VERSION ""

NS_ :

BS_:

BU_: TPM_HS EPS_HS IPC_HS TestTool_HS EBCM_HS BCM_HS TCM_HS ECM_HS

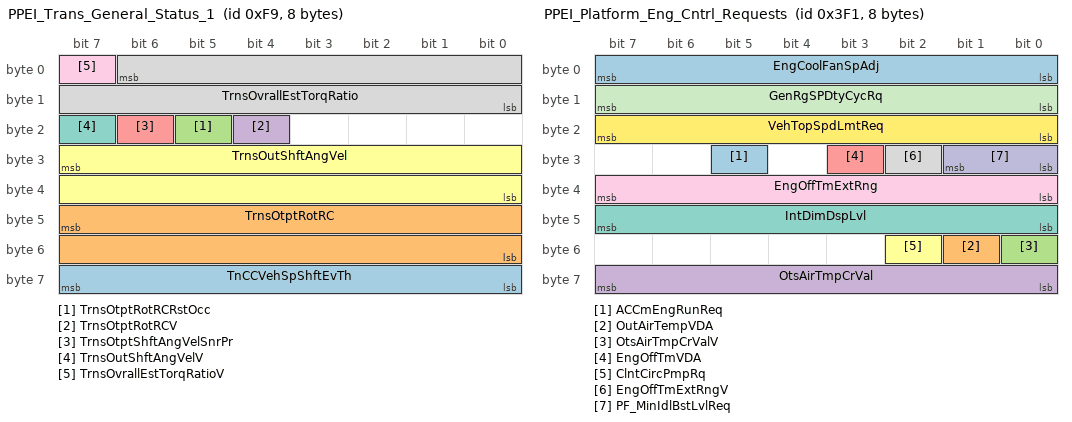
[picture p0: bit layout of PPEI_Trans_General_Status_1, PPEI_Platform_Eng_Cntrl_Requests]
BO_ 249 PPEI_Trans_General_Status_1: 8 ECM_HS
 SG_ TnCCVehSpShftEvTh : 63|8@0+ (2,0) [0|510] "km / h"  ECM_HS
 SG_ TrnsOtptRotRC : 47|16@0+ (0.0078125,0) [0|511.9921875] "rot"  ECM_HS
 SG_ TrnsOtptRotRCRstOcc : 21|1@0+ (1,0) [0|1] ""  ECM_HS
 SG_ TrnsOtptRotRCV : 20|1@0+ (1,0) [0|1] ""  ECM_HS
 SG_ TrnsOtptShftAngVelSnrPr : 22|1@0+ (1,0) [0|1] ""  ECM_HS
 SG_ TrnsOutShftAngVel : 31|16@0+ (0.25,0) [0|16383.75] "rpm"  ECM_HS
 SG_ TrnsOutShftAngVelV : 23|1@0+ (1,0) [0|1] ""  ECM_HS
 SG_ TrnsOvrallEstTorqRatio : 6|15@0- (0.00390625,0) [-64|63.99609375] ""  ECM_HS
 SG_ TrnsOvrallEstTorqRatioV : 7|1@0+ (1,0) [0|1] ""  ECM_HS

BO_ 1009 PPEI_Platform_Eng_Cntrl_Requests: 8 BCM_HS
 SG_ ACCmEngRunReq : 29|1@0+ (1,0) [0|1] ""  ECM_HS
 SG_ OutAirTempVDA : 49|1@0+ (1,0) [0|1] ""  ECM_HS
 SG_ OtsAirTmpCrValV : 48|1@0+ (1,0) [0|1] ""  ECM_HS
 SG_ OtsAirTmpCrVal : 63|8@0+ (0.5,-40) [-40|87.5] "deg C"  ECM_HS
 SG_ EngOffTmVDA : 27|1@0+ (1,0) [0|1] ""  EPS_HS
 SG_ ClntCircPmpRq : 50|1@0+ (1,0) [0|1] ""  ECM_HS
 SG_ IntDimDspLvl : 47|8@0+ (0.392157,0) [0|100.000035] "%" Vector__XXX
 SG_ EngOffTmExtRngV : 26|1@0+ (1,0) [0|1] ""  EPS_HS
 SG_ EngOffTmExtRng : 39|8@0+ (4,0) [0|1020] "min"  EPS_HS
 SG_ PF_MinIdlBstLvlReq : 25|2@0+ (1,0) [0|3] ""  ECM_HS
 SG_ GenRgSPDtyCycRq : 15|8@0+ (0.392157,0) [0|100.000035] "%"  ECM_HS
 SG_ VehTopSpdLmtReq : 23|8@0+ (2,0) [0|510] "km / h"  ECM_HS
 SG_ EngCoolFanSpAdj : 7|8@0- (0.78125,0) [-100|99.21875] "%"  ECM_HS

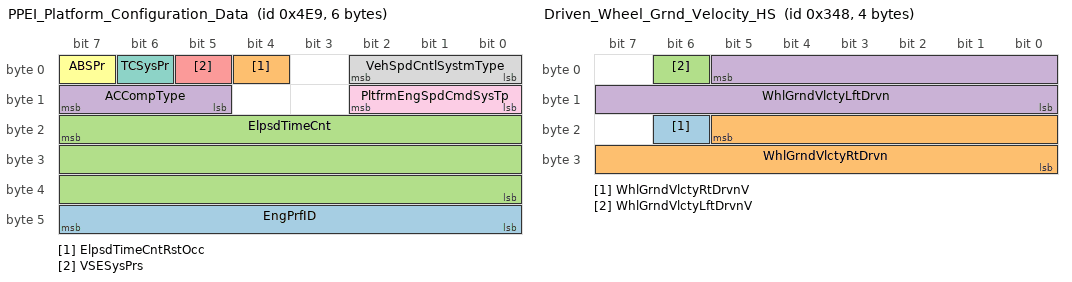
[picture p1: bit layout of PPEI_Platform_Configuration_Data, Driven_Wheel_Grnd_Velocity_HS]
BO_ 1257 PPEI_Platform_Configuration_Data: 6 BCM_HS
 SG_ EngPrfID : 47|8@0+ (2,0) [0|510] "kW"  ECM_HS
 SG_ ElpsdTimeCntRstOcc : 4|1@0+ (1,0) [0|1] ""  ECM_HS
 SG_ ElpsdTimeCnt : 23|24@0+ (1,0) [0|16777215] "min"  ECM_HS
 SG_ ACCompType : 15|3@0+ (1,0) [0|7] ""  ECM_HS
 SG_ VSESysPrs : 5|1@0+ (1,0) [0|1] ""  TCM_HS,ECM_HS
 SG_ ABSPr : 7|1@0+ (1,0) [0|1] ""  TCM_HS,ECM_HS
 SG_ TCSysPr : 6|1@0+ (1,0) [0|1] ""  TCM_HS,ECM_HS
 SG_ VehSpdCntlSystmType : 2|3@0+ (1,0) [0|7] ""  ECM_HS
 SG_ PltfrmEngSpdCmdSysTp : 10|3@0+ (1,0) [0|7] ""  TCM_HS,ECM_HS

BO_ 497 PPEI_Platform_General_Status: 8 BCM_HS
 SG_ FuelFltLfRstRqd : 56|1@0+ (1,0) [0|1] ""  IPC_HS,ECM_HS
 SG_ ACCompSysVDA : 9|1@0+ (1,0) [0|1] ""  ECM_HS
 SG_ BkupPwrModeMstrVDA : 7|1@0+ (1,0) [0|1] ""  EBCM_HS
 SG_ PrkBrkVDA : 35|1@0+ (1,0) [0|1] ""  ECM_HS
 SG_ PrkBrkVDM : 62|1@0+ (1,0) [0|1] "" Vector__XXX
 SG_ BkupPwrModeMstrVDM : 61|1@0+ (1,0) [0|1] ""  ECM_HS
 SG_ ACCompSysVDM : 60|1@0+ (1,0) [0|1] "" Vector__XXX
 SG_ AirbgVDA : 57|1@0+ (1,0) [0|1] ""  ECM_HS
 SG_ SysBkupPwrMdEn : 6|1@0+ (1,0) [0|1] ""  EPS_HS,EBCM_HS,TCM_HS,ECM_HS
 SG_ SysBkUpPwrMd : 5|2@0+ (1,0) [0|3] ""  EPS_HS,EBCM_HS,TCM_HS,ECM_HS
 SG_ SysPwrMd : 1|2@0+ (1,0) [0|3] ""  TPM_HS,EPS_HS,IPC_HS,TCM_HS,ECM_HS,EBCM_HS
 SG_ TrStLgMdAtv : 34|1@0+ (1,0) [0|1] ""  EPS_HS,TCM_HS,ECM_HS,EBCM_HS
 SG_ DispMeasSys : 59|1@0+ (1,0) [0|1] ""  ECM_HS
 SG_ ACCmpsrFldOn : 63|1@0+ (1,0) [0|1] ""  ECM_HS
 SG_ ACCompModReq : 12|2@0+ (1,0) [0|3] ""  ECM_HS
 SG_ ACCompNormLd : 55|8@0+ (0.1,0) [0|25.5] "l/min"  ECM_HS
 SG_ ACCompNormLdV : 10|1@0+ (1,0) [0|1] ""  ECM_HS
 SG_ PTORSMstrEngShtReq : 13|1@0+ (1,0) [0|1] ""  ECM_HS
 SG_ EngOilLfRstRq : 37|1@0+ (1,0) [0|1] ""  ECM_HS
 SG_ SIRDpl : 58|1@0+ (1,0) [0|1] ""  IPC_HS,ECM_HS
 SG_ PTORmStMsEngStRq : 14|1@0+ (1,0) [0|1] ""  ECM_HS
 SG_ RmVehStrRq : 15|1@0+ (1,0) [0|1] ""  ECM_HS
 SG_ ThrtlPrgrsnReq : 39|2@0+ (1,0) [0|3] ""  ECM_HS
 SG_ PrkBrkSwAtv : 36|1@0+ (1,0) [0|1] ""  TPM_HS,IPC_HS,EBCM_HS,ECM_HS
 SG_ PMMAccTrmSt : 2|1@0+ (1,0) [0|1] ""  IPC_HS,TCM_HS,ECM_HS
 SG_ PMMRunCrkTrmSt : 3|1@0+ (1,0) [0|1] ""  IPC_HS,TCM_HS,ECM_HS
 SG_ ImmblzrPreRelPswdStat : 8|1@0+ (1,0) [0|1] ""  ECM_HS
 SG_ ImmblzrPreRelPswrd : 23|16@0+ (1,0) [0|65535] "passwrd"  ECM_HS

BO_ 969 PPEI_Platform_Immobilizer_Data: 8 BCM_HS
 SG_ ImoInf : 7|64@0+ (1,0) [0|1.8446744074E+019] ""  ECM_HS

BO_ 1249 PPEI_VIN_Digits_10_to_17: 8 BCM_HS
 SG_ VehIdNmDig10_17 : 7|64@0+ (1,0) [0|1] ""  TCM_HS,ECM_HS

BO_ 2024 USDT_Resp_From_ECM_HS: 8 ECM_HS
 SG_ DgnInf : 7|64@0+ (1,0) [0|1.8446744074E+019] ""  TestTool_HS

BO_ 1512 UUDT_Resp_From_ECM: 8 ECM_HS
 SG_ DgnInf : 7|64@0+ (1,0) [0|1.8446744074E+019] ""  TestTool_HS

BO_ 840 Driven_Wheel_Grnd_Velocity_HS: 4 EBCM_HS
 SG_ WhlGrndVlctyRtDrvnV : 22|1@0+ (1,0) [0|1] ""  EPS_HS,IPC_HS,BCM_HS
 SG_ WhlGrndVlctyRtDrvn : 21|14@0+ (0.03125,0) [0|511.96875] "km / h"  EPS_HS,IPC_HS,BCM_HS
 SG_ WhlGrndVlctyLftDrvnV : 6|1@0+ (1,0) [0|1] ""  EPS_HS,IPC_HS,BCM_HS
 SG_ WhlGrndVlctyLftDrvn : 5|14@0+ (0.03125,0) [0|511.96875] "km / h"  EPS_HS,IPC_HS,BCM_HS

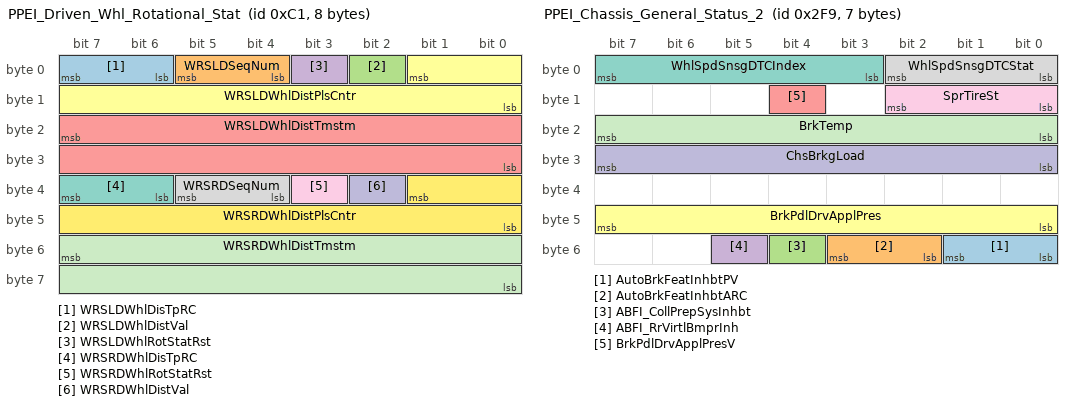
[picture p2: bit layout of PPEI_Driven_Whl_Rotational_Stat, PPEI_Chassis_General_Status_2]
BO_ 193 PPEI_Driven_Whl_Rotational_Stat: 8 EBCM_HS
 SG_ WRSLDWhlDisTpRC : 7|2@0+ (1,0) [0|3] "counts"  EPS_HS,BCM_HS,TCM_HS,ECM_HS
 SG_ WRSLDSeqNum : 5|2@0+ (1,0) [0|3] "counts"  EPS_HS,BCM_HS,TCM_HS,ECM_HS
 SG_ WRSLDWhlDistVal : 2|1@0+ (1,0) [0|1] ""  EPS_HS,BCM_HS,TCM_HS,ECM_HS
 SG_ WRSLDWhlRotStatRst : 3|1@0+ (1,0) [0|1] ""  EPS_HS,BCM_HS,TCM_HS,ECM_HS
 SG_ WRSLDWhlDistTmstm : 23|16@0+ (1,0) [0|65535] "counts"  EPS_HS,BCM_HS,TCM_HS,ECM_HS
 SG_ WRSLDWhlDistPlsCntr : 1|10@0+ (1,0) [0|1023] "counts"  EPS_HS,BCM_HS,TCM_HS,ECM_HS
 SG_ WRSRDWhlDisTpRC : 39|2@0+ (1,0) [0|3] "counts"  EPS_HS,BCM_HS,TCM_HS,ECM_HS
 SG_ WRSRDSeqNum : 37|2@0+ (1,0) [0|3] "counts"  EPS_HS,BCM_HS,TCM_HS,ECM_HS
 SG_ WRSRDWhlRotStatRst : 35|1@0+ (1,0) [0|1] ""  EPS_HS,BCM_HS,TCM_HS,ECM_HS
 SG_ WRSRDWhlDistVal : 34|1@0+ (1,0) [0|1] ""  EPS_HS,BCM_HS,TCM_HS,ECM_HS
 SG_ WRSRDWhlDistTmstm : 55|16@0+ (1,0) [0|65535] "counts"  EPS_HS,BCM_HS,TCM_HS,ECM_HS
 SG_ WRSRDWhlDistPlsCntr : 33|10@0+ (1,0) [0|1023] "counts"  EPS_HS,BCM_HS,TCM_HS,ECM_HS

BO_ 481 PPEI_Cruise_Control_Sw_Status: 7 BCM_HS
 SG_ AuxHtrRq : 31|1@0+ (1,0) [0|1] ""  ECM_HS
 SG_ AuxHtrAtv : 30|1@0+ (1,0) [0|1] ""  ECM_HS
 SG_ DrvSelMdSwStaARC : 33|2@0+ (1,0) [0|3] ""  ECM_HS
 SG_ DrvSelMdSw1Sta : 39|1@0+ (1,0) [0|1] ""  ECM_HS
 SG_ CrsSpdLmtrSwStatPVal : 55|4@0+ (1,0) [0|15] ""  ECM_HS
 SG_ CrsSpdLmtrSwStatARC : 43|2@0+ (1,0) [0|3] ""  ECM_HS
 SG_ FuelMdSwActV : 29|1@0+ (1,0) [0|1] ""  ECM_HS
 SG_ FuelMdSwAct : 28|1@0+ (1,0) [0|1] ""  ECM_HS
 SG_ CrsSpdLmtrSwStat : 47|4@0+ (1,0) [0|15] ""  ECM_HS
 SG_ AdptCrsGapSwAct : 23|2@0+ (1,0) [0|3] "" Vector__XXX
 SG_ CrsCntrlSwStCanSwAct : 7|1@0+ (1,0) [0|1] ""  ECM_HS
 SG_ CrsCntrlSwStSwDataIntgty : 1|2@0+ (1,0) [0|3] ""  ECM_HS
 SG_ CrsCntrlSwStSpdInSwAct : 3|1@0+ (1,0) [0|1] ""  ECM_HS
 SG_ CrsCntrlSwStSpDcSwAct : 2|1@0+ (1,0) [0|1] ""  ECM_HS
 SG_ CrsCntrlSwStSetSwAct : 4|1@0+ (1,0) [0|1] ""  ECM_HS
 SG_ CrsCntrlSwStResSwAct : 5|1@0+ (1,0) [0|1] ""  ECM_HS
 SG_ CrsCntrlSwStOnSwAct : 6|1@0+ (1,0) [0|1] ""  ECM_HS
 SG_ CrsCntrlSwStatProtValue : 15|8@0+ (1,0) [0|255] ""  ECM_HS
 SG_ CrsCntrlSwStAlvRollCnt : 17|2@0+ (1,0) [0|3] ""  ECM_HS
 SG_ CrsCntCncRq : 18|1@0+ (1,0) [0|1] ""  ECM_HS

BO_ 761 PPEI_Chassis_General_Status_2: 7 EBCM_HS
 SG_ AutoBrkFeatInhbtPV : 49|2@0+ (1,0) [0|3] ""  ECM_HS
 SG_ AutoBrkFeatInhbtARC : 51|2@0+ (1,0) [0|3] ""  ECM_HS
 SG_ ABFI_CollPrepSysInhbt : 52|1@0+ (1,0) [0|1] ""  ECM_HS
 SG_ ABFI_RrVirtlBmprInh : 53|1@0+ (1,0) [0|1] ""  ECM_HS
 SG_ BrkPdlDrvApplPresV : 12|1@0+ (1,0) [0|1] ""  ECM_HS,TCM_HS
 SG_ BrkPdlDrvApplPres : 47|8@0+ (75,0) [0|19125] "kPa"  ECM_HS,TCM_HS
 SG_ WhlSpdSnsgDTCIndex : 7|5@0+ (1,0) [0|31] ""  ECM_HS
 SG_ WhlSpdSnsgDTCStat : 2|3@0+ (1,0) [0|7] ""  ECM_HS
 SG_ SprTireSt : 10|3@0+ (1,0) [0|7] ""  BCM_HS
 SG_ ChsBrkgLoad : 31|8@0+ (0.392157,0) [0|100.000035] "%"  TCM_HS
 SG_ BrkTemp : 23|8@0+ (4,-40) [-40|980] "deg C"  TCM_HS

BO_ 489 PPEI_Chassis_General_Status_1: 8 EBCM_HS
 SG_ DrvIndpntBrkAppAct : 55|1@0+ (1,0) [0|1] ""  TCM_HS,ECM_HS
 SG_ WhlSlpSt : 52|2@0+ (1,0) [0|3] ""  ECM_HS,TCM_HS
 SG_ BSTGRReqdGear : 19|4@0+ (1,0) [0|15] ""  TCM_HS
 SG_ BSTGRReqType : 21|2@0+ (1,0) [0|3] ""  TCM_HS
 SG_ VehDynOvrUndrStr : 49|10@0- (0.5,0) [-256|255.5] "%" Vector__XXX
 SG_ VSELatAccV : 4|1@0+ (1,0) [0|1] ""  BCM_HS,TCM_HS,ECM_HS
 SG_ VSELatAcc : 3|12@0- (0.015625,0) [-32|31.984375] "m/s^2"  BCM_HS,TCM_HS,ECM_HS
 SG_ VSEAct : 24|1@0+ (1,0) [0|1] ""  EPS_HS,ECM_HS
 SG_ VhDynCntlSysSt : 39|3@0+ (1,0) [0|7] ""  EPS_HS,ECM_HS
 SG_ VehDynYawRateV : 36|1@0+ (1,0) [0|1] ""  EPS_HS,BCM_HS
 SG_ VehDynYawRate : 35|12@0- (0.0625,0) [-128|127.9375] "deg/sec"  EPS_HS,BCM_HS
 SG_ TrnsBrkSysCltchRelRqd : 5|1@0+ (1,0) [0|1] ""  TCM_HS
 SG_ TracCntrlSysDrIntnt : 26|1@0+ (1,0) [0|1] ""  ECM_HS
 SG_ VehDynOvrUndrStrV : 50|1@0+ (1,0) [0|1] "" Vector__XXX
 SG_ TCSysEnbld : 27|1@0+ (1,0) [0|1] ""  EPS_HS,TCM_HS,ECM_HS
 SG_ TCSysAtv : 28|1@0+ (1,0) [0|1] ""  EPS_HS,BCM_HS,TCM_HS,ECM_HS
 SG_ BrkPdlDrvAppPrsDetcdV : 7|1@0+ (1,0) [0|1] ""  TCM_HS,ECM_HS
 SG_ BrkPdlDrvAppPrsDetcd : 6|1@0+ (1,0) [0|1] ""  TCM_HS,ECM_HS
 SG_ ACCBrkngAct : 31|1@0+ (1,0) [0|1] ""  TCM_HS,ECM_HS
 SG_ ABSFld : 29|1@0+ (1,0) [0|1] ""  EPS_HS,TCM_HS,ECM_HS
 SG_ ABSAtv : 30|1@0+ (1,0) [0|1] ""  EPS_HS,IPC_HS,BCM_HS,TCM_HS,ECM_HS

BO_ 381 Antilock_Brake_and_TC_Status_HS: 6 EBCM_HS
 SG_ EBDFailed : 23|1@0+ (1,0) [0|1] ""  IPC_HS,BCM_HS
 SG_ StWhAnVDA : 17|1@0+ (1,0) [0|1] ""  IPC_HS,BCM_HS
 SG_ TirePrsLowIO : 9|1@0+ (1,0) [0|1] ""  BCM_HS
 SG_ VaccBoostFailure : 16|1@0+ (1,0) [0|1] ""  BCM_HS
 SG_ VSESysPrs : 1|1@0+ (1,0) [0|1] ""  BCM_HS
 SG_ HalfSysFail : 18|1@0+ (1,0) [0|1] ""  IPC_HS,BCM_HS
 SG_ ActVehAccel : 35|12@0- (0.01,0) [-20.48|20.47] "m/s^2" Vector__XXX
 SG_ ActVehAccelV : 20|1@0+ (1,0) [0|1] "" Vector__XXX
 SG_ BksOvht : 8|1@0+ (1,0) [0|1] ""  IPC_HS,BCM_HS
 SG_ TCSysPr : 10|1@0+ (1,0) [0|1] ""  BCM_HS
 SG_ ABSPr : 22|1@0+ (1,0) [0|1] ""  IPC_HS,BCM_HS
 SG_ TreInfMonSysRstPrfmd : 11|1@0+ (1,0) [0|1] ""  BCM_HS
 SG_ ABSIO : 12|1@0+ (1,0) [0|1] ""  IPC_HS,BCM_HS
 SG_ BrkPadWrnIO : 0|1@0+ (1,0) [0|1] ""  BCM_HS
 SG_ VehStabEnhmntMd : 15|3@0+ (1,0) [0|7] ""  BCM_HS
 SG_ VehStabEnhmntStat : 4|3@0+ (1,0) [0|7] ""  BCM_HS
 SG_ TCSysOpMd : 7|3@0+ (1,0) [0|7] ""  BCM_HS
 SG_ TCSysOpStat : 38|3@0+ (1,0) [0|7] ""  IPC_HS,BCM_HS
 SG_ BrkSysVTopSpdLimVal : 31|8@0+ (2,0) [0|510] "km / h"  IPC_HS,BCM_HS
 SG_ BrkSysRedBrkTlltlReq : 19|1@0+ (1,0) [0|1] ""  IPC_HS,BCM_HS
 SG_ BrkSysBrkLtsReqd : 21|1@0+ (1,0) [0|1] ""  IPC_HS,BCM_HS

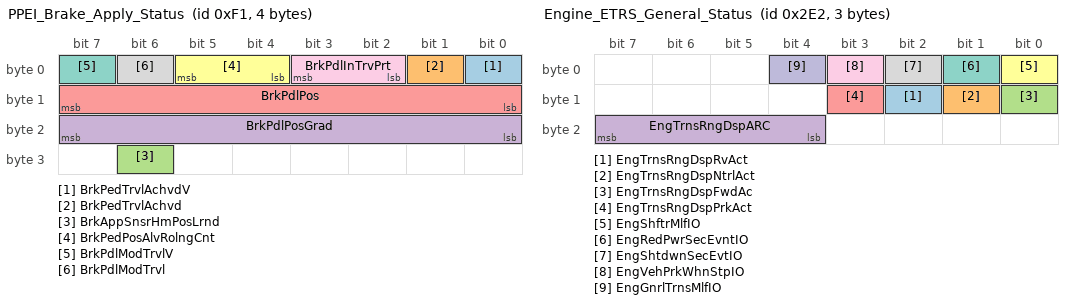
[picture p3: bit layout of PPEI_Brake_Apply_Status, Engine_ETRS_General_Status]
BO_ 241 PPEI_Brake_Apply_Status: 4 BCM_HS
 SG_ BrkPedTrvlAchvdV : 0|1@0+ (1,0) [0|1] ""  ECM_HS,EBCM_HS
 SG_ BrkPedTrvlAchvd : 1|1@0+ (1,0) [0|1] ""  ECM_HS,EBCM_HS
 SG_ BrkAppSnsrHmPosLrnd : 30|1@0+ (1,0) [0|1] ""  ECM_HS,EBCM_HS
 SG_ BrkPdlPosGrad : 23|8@0- (40,0) [-5120|5080] "%/s"  EBCM_HS
 SG_ BrkPdlPos : 15|8@0+ (0.392157,0) [0|100.000035] "% full"  TCM_HS,EBCM_HS
 SG_ BrkPedPosAlvRolngCnt : 5|2@0+ (1,0) [0|3] ""  EBCM_HS,TCM_HS,ECM_HS
 SG_ BrkPdlModTrvlV : 7|1@0+ (1,0) [0|1] ""  TCM_HS,ECM_HS
 SG_ BrkPdlModTrvl : 6|1@0+ (1,0) [0|1] ""  TCM_HS,ECM_HS
 SG_ BrkPdlInTrvPrt : 3|2@0+ (1,0) [0|3] ""  EBCM_HS,TCM_HS,ECM_HS

BO_ 1356 UUDT_Resp_From_IPC_HS: 8 IPC_HS
 SG_ DgnInf_HS541 : 7|64@0+ (1,0) [0|1.8446744074E+019] ""  TestTool_HS

BO_ 500 PPEI_Drv_Pref_Mode_Switch_Status: 2 ECM_HS
 SG_ DrvSelMd1ReqDnd : 14|1@0+ (1,0) [0|1] ""  BCM_HS
 SG_ DrvSelMd1Stat : 15|1@0+ (1,0) [0|1] ""  BCM_HS

BO_ 407 PTEI_Trans_Ratio_Status: 2 TCM_HS
 SG_ TrnsOvrallActTorqRatioV : 7|1@0+ (1,0) [0|0] ""  ECM_HS
 SG_ TrnsOvrallActTorqRatio : 6|15@0- (0.00390625,0) [0|127.99609375] ""  ECM_HS

BO_ 1221 PPEI_Platform_Eng_Cntrl_Req_2: 2 BCM_HS
 SG_ PFFanSpdPrcntRq : 15|8@0+ (0.392157,0) [0|100.000035] "%"  ECM_HS

BO_ 738 Engine_ETRS_General_Status: 3 ECM_HS
 SG_ EngTrnsRngDspRvAct : 10|1@0+ (1,0) [0|1] ""  BCM_HS
 SG_ EngTrnsRngDspNtrlAct : 9|1@0+ (1,0) [0|1] ""  BCM_HS
 SG_ EngTrnsRngDspFwdAc : 8|1@0+ (1,0) [0|1] ""  BCM_HS
 SG_ EngTrnsRngDspARC : 23|4@0+ (1,0) [0|15] ""  BCM_HS
 SG_ EngTrnsRngDspPrkAct : 11|1@0+ (1,0) [0|1] ""  BCM_HS
 SG_ EngShftrMlfIO : 0|1@0+ (1,0) [0|1] ""  BCM_HS
 SG_ EngRedPwrSecEvntIO : 1|1@0+ (1,0) [0|1] ""  BCM_HS
 SG_ EngShtdwnSecEvtIO : 2|1@0+ (1,0) [0|1] ""  BCM_HS
 SG_ EngVehPrkWhnStpIO : 3|1@0+ (1,0) [0|1] ""  BCM_HS
 SG_ EngGnrlTrnsMlfIO : 4|1@0+ (1,0) [0|1] ""  BCM_HS

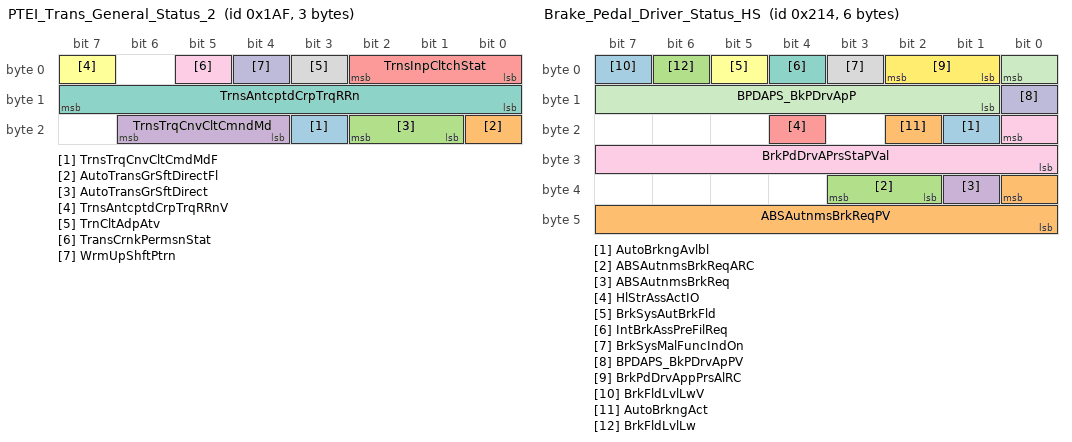
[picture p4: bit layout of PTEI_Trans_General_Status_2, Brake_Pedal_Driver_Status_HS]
BO_ 431 PTEI_Trans_General_Status_2: 3 TCM_HS
 SG_ TrnsTrqCnvCltCmdMdF : 19|1@0+ (1,0) [0|1] ""  ECM_HS
 SG_ AutoTransGrSftDirectFl : 16|1@0+ (1,0) [0|1] ""  ECM_HS
 SG_ AutoTransGrSftDirect : 18|2@0+ (1,0) [0|3] ""  ECM_HS
 SG_ TrnsTrqCnvCltCmndMd : 22|3@0+ (1,0) [0|7] ""  ECM_HS
 SG_ TrnsInpCltchStat : 2|3@0+ (1,0) [0|0] ""  ECM_HS
 SG_ TrnsAntcptdCrpTrqRRnV : 7|1@0+ (1,0) [0|0] ""  ECM_HS
 SG_ TrnsAntcptdCrpTrqRRn : 15|8@0+ (0.5,0) [0|127.5] "Nm"  ECM_HS
 SG_ TrnCltAdpAtv : 3|1@0+ (1,0) [0|1] ""  ECM_HS
 SG_ TransCrnkPermsnStat : 5|1@0+ (1,0) [0|0] ""  ECM_HS
 SG_ WrmUpShftPtrn : 4|1@0+ (1,0) [0|0] ""  ECM_HS

BO_ 1345 UUDT_Resp_From_BCM_HS: 8 BCM_HS
 SG_ DgnInf_HS541 : 7|64@0+ (1,0) [0|1.8446744074E+019] ""  TestTool_HS

BO_ 309 Body_Information_2_HS: 8 BCM_HS
 SG_ StBltTgtCSRq : 23|3@0+ (1,0) [0|0] "" Vector__XXX
 SG_ ColPrSysCustReq : 15|3@0+ (1,0) [0|0] "" Vector__XXX
 SG_ SecV : 62|1@0+ (1,0) [0|1] "" Vector__XXX
 SG_ Sec : 61|6@0+ (1,0) [0|63] "s" Vector__XXX
 SG_ CldrYr_154 : 55|8@0+ (1,2000) [2000|2255] "year" Vector__XXX
 SG_ CldrYr : 47|8@0+ (1,2000) [2000|2255] "year" Vector__XXX
 SG_ CldrMth_154 : 39|4@0+ (1,0) [0|15] "" Vector__XXX
 SG_ CldrMth : 35|4@0+ (1,0) [0|15] "" Vector__XXX
 SG_ CldrDay_154 : 30|5@0+ (1,0) [0|31] "days" Vector__XXX
 SG_ CldrDay : 20|5@0+ (1,0) [0|31] "days" Vector__XXX
 SG_ AutoHiBmVDA : 25|1@0+ (1,0) [0|1] "" Vector__XXX
 SG_ CtLghtDet : 24|1@0+ (1,0) [0|1] "" Vector__XXX
 SG_ RrClosVDA : 11|1@0+ (1,0) [0|1] "" Vector__XXX
 SG_ TCSysDisSwAtv : 4|1@0+ (1,0) [0|1] "" Vector__XXX
 SG_ VehMovState : 2|3@0+ (1,0) [0|0] "" Vector__XXX
 SG_ TCSysDisSwAtvV : 3|1@0+ (1,0) [0|1] "" Vector__XXX
 SG_ HillDesCtrlMdSwActV : 10|1@0+ (1,0) [0|0] "" Vector__XXX
 SG_ WSWshSwAtv : 5|1@0+ (1,0) [0|1] "" Vector__XXX
 SG_ HillDesCtrlMdSwAct : 9|1@0+ (1,0) [0|1] "" Vector__XXX
 SG_ RrClosAjarSwAct : 12|1@0+ (1,0) [0|1] ""  IPC_HS
 SG_ WSWprAct : 6|1@0+ (1,0) [0|1] "" Vector__XXX

BO_ 532 Brake_Pedal_Driver_Status_HS: 6 EBCM_HS
 SG_ AutoBrkngAvlbl : 17|1@0+ (1,0) [0|1] "" Vector__XXX
 SG_ ABSAutnmsBrkReqPV : 32|9@0+ (1,0) [0|511] "" Vector__XXX
 SG_ ABSAutnmsBrkReqARC : 35|2@0+ (1,0) [0|3] "" Vector__XXX
 SG_ ABSAutnmsBrkReq : 33|1@0+ (1,0) [0|1] "" Vector__XXX
 SG_ HlStrAssActIO : 20|1@0+ (1,0) [0|1] ""  BCM_HS
 SG_ BrkSysAutBrkFld : 5|1@0+ (1,0) [0|1] ""  BCM_HS
 SG_ IntBrkAssPreFilReq : 4|1@0+ (1,0) [0|1] "N/A"  BCM_HS
 SG_ BrkSysMalFuncIndOn : 3|1@0+ (1,0) [0|1] ""  IPC_HS,BCM_HS
 SG_ BrkPdDrvAPrsStaPVal : 16|9@0+ (1,0) [0|511] "" Vector__XXX
 SG_ BPDAPS_BkPDrvApPV : 8|1@0+ (1,0) [0|1] ""  BCM_HS
 SG_ BPDAPS_BkPDrvApP : 0|8@0+ (75,0) [0|19125] "kPa"  BCM_HS
 SG_ BrkPdDrvAppPrsAlRC : 2|2@0+ (1,0) [0|3] "" Vector__XXX
 SG_ BrkFldLvlLwV : 7|1@0+ (1,0) [0|1] ""  IPC_HS,BCM_HS
 SG_ AutoBrkngAct : 18|1@0+ (1,0) [0|1] "" Vector__XXX
 SG_ BrkFldLvlLw : 6|1@0+ (1,0) [0|1] ""  IPC_HS,BCM_HS

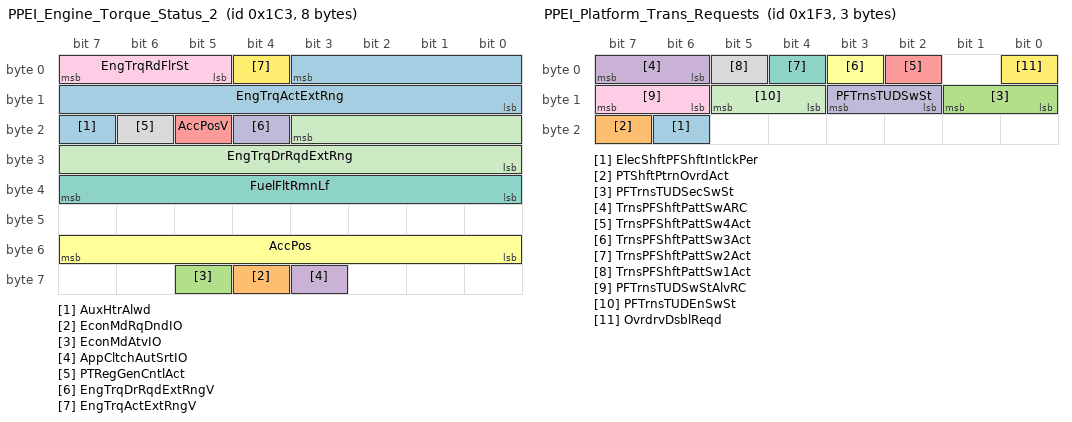
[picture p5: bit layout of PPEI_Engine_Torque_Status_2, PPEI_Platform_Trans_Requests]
BO_ 451 PPEI_Engine_Torque_Status_2: 8 ECM_HS
 SG_ AuxHtrAlwd : 23|1@0+ (1,0) [0|1] ""  BCM_HS
 SG_ EconMdRqDndIO : 60|1@0+ (1,0) [0|1] ""  BCM_HS
 SG_ EconMdAtvIO : 61|1@0+ (1,0) [0|1] ""  BCM_HS
 SG_ AppCltchAutSrtIO : 59|1@0+ (1,0) [0|1] ""  BCM_HS
 SG_ AccPosV : 21|1@0+ (1,0) [0|1] "" Vector__XXX
 SG_ AccPos : 55|8@0+ (0.392157,0) [0|100.000035] "%" Vector__XXX
 SG_ FuelFltRmnLf : 39|8@0+ (0.392157,0) [0|100.000035] "%"  BCM_HS
 SG_ PTRegGenCntlAct : 22|1@0+ (1,0) [0|1] ""  BCM_HS
 SG_ EngTrqRdFlrSt : 7|3@0+ (1,0) [0|7] "" Vector__XXX
 SG_ EngTrqDrRqdExtRngV : 20|1@0+ (1,0) [0|1] "" Vector__XXX
 SG_ EngTrqDrRqdExtRng : 19|12@0+ (0.5,-848) [-848|1199.5] "Nm" Vector__XXX
 SG_ EngTrqActExtRngV : 4|1@0+ (1,0) [0|1] ""  EPS_HS,BCM_HS
 SG_ EngTrqActExtRng : 3|12@0+ (0.5,-848) [-848|1199.5] "Nm"  EPS_HS,BCM_HS

BO_ 320 Exterior_Lighting_HS: 6 BCM_HS
 SG_ IntDimDspLvlPlt : 39|8@0+ (0.392157,0) [0|100.000035] "%"  IPC_HS
 SG_ IntDimLvl : 47|8@0+ (0.392157,0) [0|100.000035] "%"  IPC_HS
 SG_ HiBmIO : 13|1@0+ (1,0) [0|1] ""  IPC_HS
 SG_ PrkLtIO : 23|1@0+ (1,0) [0|1] ""  IPC_HS
 SG_ RrFgLtIO : 20|1@0+ (1,0) [0|1] ""  IPC_HS
 SG_ FrFgLtIO : 21|1@0+ (1,0) [0|1] ""  IPC_HS
 SG_ RtTrnLmpAtv : 27|2@0+ (1,0) [0|3] ""  IPC_HS
 SG_ LftTrnLmpAtv : 25|2@0+ (1,0) [0|3] ""  IPC_HS
 SG_ HazSwAtv : 22|1@0+ (1,0) [0|1] ""  IPC_HS
 SG_ BrkLtsAtv : 6|1@0+ (1,0) [0|1] ""  IPC_HS
 SG_ TrnSwAct : 19|2@0+ (1,0) [0|3] ""  IPC_HS
 SG_ RrFogLmpsAct : 8|1@0+ (1,0) [0|1] ""  IPC_HS
 SG_ OtsdAmbtLtLvlStatV : 2|1@0+ (1,0) [0|1] ""  IPC_HS
 SG_ OtsdAmbtLtLvlStat : 17|2@0+ (1,0) [0|3] ""  IPC_HS
 SG_ MainLghtSw : 12|2@0+ (1,0) [0|3] "N/A"  IPC_HS
 SG_ LowBmAct : 1|1@0+ (1,0) [0|1] ""  IPC_HS
 SG_ HighBmAct : 7|1@0+ (1,0) [0|1] ""  IPC_HS
 SG_ HdlmpBmSelectStat : 10|2@0+ (1,0) [0|3] ""  IPC_HS
 SG_ FlToPsSwAtv : 5|1@0+ (1,0) [0|1] ""  IPC_HS
 SG_ AdvFrntLghtSysEnbld : 3|1@0+ (1,0) [0|1] ""  IPC_HS
 SG_ FrFogLmpsAct : 0|1@0+ (1,0) [0|1] ""  IPC_HS
 SG_ AutLghtCtrl : 4|1@0+ (1,0) [0|1] "N/A"  IPC_HS

BO_ 1919 DTC_Triggered_77F: 7 TCM_HS
 SG_ DTCI_DTCFaultType_77F : 55|8@0+ (1,0) [0|255] "" Vector__XXX
 SG_ DTCI_CodeSupported_77F : 40|1@0+ (1,0) [0|1] "" Vector__XXX
 SG_ DTCI_CurrentStatus_77F : 41|1@0+ (1,0) [0|1] "" Vector__XXX
 SG_ DTCI_TstNPsdCdClrdSt_77F : 42|1@0+ (1,0) [0|1] "" Vector__XXX
 SG_ DTCI_TstFldCdClrdStat_77F : 43|1@0+ (1,0) [0|1] "" Vector__XXX
 SG_ DTCI_HistStat_77F : 44|1@0+ (1,0) [0|1] "" Vector__XXX
 SG_ DTCI_TstNPsdPwrUpSt_77F : 45|1@0+ (1,0) [0|1] "" Vector__XXX
 SG_ DTCI_TstFldPwrUpSt_77F : 46|1@0+ (1,0) [0|1] "" Vector__XXX
 SG_ DTCI_WrnIndRqdSt_77F : 47|1@0+ (1,0) [0|1] "" Vector__XXX
 SG_ DTCI_DTCFailType_77F : 39|8@0+ (1,0) [0|255] "" Vector__XXX
 SG_ DTCI_DTCNumber_77F : 23|16@0+ (1,0) [0|65535] "" Vector__XXX
 SG_ DTCI_DTCSource_77F : 15|8@0+ (1,0) [0|255] "" Vector__XXX
 SG_ DTCI_DTCTriggered_77F : 0|1@0+ (1,0) [0|1] "" Vector__XXX
 SG_ DTCIUnused7_77F : 1|1@0+ (1,0) [0|1] "" Vector__XXX
 SG_ DTCIUnused6_77F : 2|1@0+ (1,0) [0|1] "" Vector__XXX
 SG_ DTCIUnused5_77F : 3|1@0+ (1,0) [0|1] "" Vector__XXX
 SG_ DTCIUnused4_77F : 4|1@0+ (1,0) [0|1] "" Vector__XXX
 SG_ DTCIUnused3_77F : 5|1@0+ (1,0) [0|1] "" Vector__XXX
 SG_ DTCIUnused2_77F : 6|1@0+ (1,0) [0|1] "" Vector__XXX
 SG_ DTCIUnused1_77F : 7|1@0+ (1,0) [0|1] "" Vector__XXX

BO_ 588 USDT_Req_to_IPC_HS: 8 TestTool_HS
 SG_ DgnInf : 7|64@0+ (1,0) [0|1.8446744074E+019] ""  IPC_HS

BO_ 499 PPEI_Platform_Trans_Requests: 3 BCM_HS
 SG_ ElecShftPFShftIntlckPer : 22|1@0+ (1,0) [0|1] ""  TCM_HS
 SG_ PTShftPtrnOvrdAct : 23|1@0+ (1,0) [0|1] ""  TCM_HS
 SG_ PFTrnsTUDSecSwSt : 9|2@0+ (1,0) [0|3] ""  TCM_HS
 SG_ TrnsPFShftPattSwARC : 7|2@0+ (1,0) [0|3] ""  ECM_HS,TCM_HS
 SG_ TrnsPFShftPattSw4Act : 2|1@0+ (1,0) [0|1] ""  ECM_HS,TCM_HS
 SG_ TrnsPFShftPattSw3Act : 3|1@0+ (1,0) [0|1] ""  ECM_HS,TCM_HS
 SG_ TrnsPFShftPattSw2Act : 4|1@0+ (1,0) [0|1] ""  ECM_HS,TCM_HS
 SG_ TrnsPFShftPattSw1Act : 5|1@0+ (1,0) [0|1] ""  ECM_HS,TCM_HS
 SG_ PFTrnsTUDSwStAlvRC : 15|2@0+ (1,0) [0|3] ""  TCM_HS
 SG_ PFTrnsTUDSwSt : 11|2@0+ (1,0) [0|3] ""  TCM_HS
 SG_ PFTrnsTUDEnSwSt : 13|2@0+ (1,0) [0|3] ""  TCM_HS
 SG_ OvrdrvDsblReqd : 0|1@0+ (1,0) [0|1] "" Vector__XXX

BO_ 1906 DTC_Triggered_772: 7 ECM_HS
 SG_ DTCI_DTCFaultType_772 : 55|8@0+ (1,0) [0|255] "" Vector__XXX
 SG_ DTCI_CodeSupported_772 : 40|1@0+ (1,0) [0|1] "" Vector__XXX
 SG_ DTCI_CurrentStatus_772 : 41|1@0+ (1,0) [0|1] "" Vector__XXX
 SG_ DTCI_TstNPsdCdClrdSt_772 : 42|1@0+ (1,0) [0|1] "" Vector__XXX
 SG_ DTCI_TstFldCdClrdStat_772 : 43|1@0+ (1,0) [0|1] "" Vector__XXX
 SG_ DTCI_HistStat_772 : 44|1@0+ (1,0) [0|1] "" Vector__XXX
 SG_ DTCI_TstNPsdPwrUpSt_772 : 45|1@0+ (1,0) [0|1] "" Vector__XXX
 SG_ DTCI_TstFldPwrUpSt_772 : 46|1@0+ (1,0) [0|1] "" Vector__XXX
 SG_ DTCI_WrnIndRqdSt_772 : 47|1@0+ (1,0) [0|1] "" Vector__XXX
 SG_ DTCI_DTCFailType_772 : 39|8@0+ (1,0) [0|255] "" Vector__XXX
 SG_ DTCI_DTCNumber_772 : 23|16@0+ (1,0) [0|65535] "" Vector__XXX
 SG_ DTCI_DTCSource_772 : 15|8@0+ (1,0) [0|255] "" Vector__XXX
 SG_ DTCI_DTCTriggered_772 : 0|1@0+ (1,0) [0|1] "" Vector__XXX
 SG_ DTCIUnused7_772 : 1|1@0+ (1,0) [0|1] "" Vector__XXX
 SG_ DTCIUnused6_772 : 2|1@0+ (1,0) [0|1] "" Vector__XXX
 SG_ DTCIUnused5_772 : 3|1@0+ (1,0) [0|1] "" Vector__XXX
 SG_ DTCIUnused4_772 : 4|1@0+ (1,0) [0|1] "" Vector__XXX
 SG_ DTCIUnused3_772 : 5|1@0+ (1,0) [0|1] "" Vector__XXX
 SG_ DTCIUnused2_772 : 6|1@0+ (1,0) [0|1] "" Vector__XXX
 SG_ DTCIUnused1_772 : 7|1@0+ (1,0) [0|1] "" Vector__XXX

BO_ 579 USDT_Req_to_EBCM_HS: 8 TestTool_HS
 SG_ DgnInf : 7|64@0+ (1,0) [0|1.8446744074E+019] ""  EBCM_HS

BO_ 1603 USDT_Resp_From_EBCM_HS: 8 EBCM_HS
 SG_ DgnInf : 7|64@0+ (1,0) [0|1.8446744074E+019] ""  TestTool_HS

BO_ 1347 UUDT_Resp_From_EBCM: 8 EBCM_HS
 SG_ DgnInf_HS : 7|64@0+ (1,0) [0|1.8446744074E+019] ""  TestTool_HS

BO_ 577 USDT_Req_to_BCM_HS: 8 TestTool_HS
 SG_ DgnInf : 7|64@0+ (1,0) [0|1.8446744074E+019] ""  BCM_HS

BO_ 298 Body_Information_HS: 8 BCM_HS
 SG_ VhSecNImmoIndRq : 57|2@0+ (1,0) [0|3] ""  IPC_HS
 SG_ ChmAct : 55|1@0+ (1,0) [0|1] ""  IPC_HS
 SG_ DDAjrSwAtvM : 63|1@0+ (1,0) [0|0] "" Vector__XXX
 SG_ CrshAlrtDrvrSlctdType : 5|1@0+ (1,0) [0|0] "" Vector__XXX
 SG_ PsSbltAtcV : 54|1@0+ (1,0) [0|1] ""  IPC_HS
 SG_ PsSbltAtc : 53|1@0+ (1,0) [0|1] ""  IPC_HS
 SG_ TrlrBrkDsplyAct : 51|1@0+ (1,0) [0|1] "" Vector__XXX
 SG_ RdSpdCatType : 45|2@0+ (1,0) [0|0] "" Vector__XXX
 SG_ LnCat : 47|2@0+ (1,0) [0|0] "" Vector__XXX
 SG_ FncRdClass : 50|3@0+ (1,0) [0|7] "" Vector__XXX
 SG_ SprtLnRd : 43|1@0+ (1,0) [0|1] "" Vector__XXX
 SG_ CntrldAccRd : 39|1@0+ (1,0) [0|1] ""  IPC_HS
 SG_ BldUpArDet : 11|1@0+ (1,0) [0|1] "" Vector__XXX
 SG_ MpDataAvlbl : 3|1@0+ (1,0) [0|1] "" Vector__XXX
 SG_ SusCustStngReq : 42|3@0+ (1,0) [0|0] "" Vector__XXX
 SG_ StrCustStngReq : 38|3@0+ (1,0) [0|0] "" Vector__XXX
 SG_ RstrCustFctrDef : 35|1@0+ (1,0) [0|0] "" Vector__XXX
 SG_ DrvlnCustStngReq : 34|3@0+ (1,0) [0|7] "" Vector__XXX
 SG_ ChmMstrVDA : 22|1@0+ (1,0) [0|1] ""  IPC_HS
 SG_ IPCVDA : 21|1@0+ (1,0) [0|1] ""  IPC_HS
 SG_ HeadUpDispVDA : 20|1@0+ (1,0) [0|1] "" Vector__XXX
 SG_ HapticSeatVDA : 52|1@0+ (1,0) [0|1] "" Vector__XXX
 SG_ RRDoorAjarSwAct : 23|1@0+ (1,0) [0|1] ""  IPC_HS
 SG_ PDAjrSwAtv : 10|1@0+ (1,0) [0|1] ""  IPC_HS
 SG_ DDAjrSwAtv : 9|1@0+ (1,0) [0|1] ""  IPC_HS
 SG_ TrlrHWIntrfcVDA : 4|1@0+ (1,0) [0|1] "" Vector__XXX
 SG_ DrId : 15|3@0+ (1,0) [0|7] "" Vector__XXX
 SG_ EnrgMgtLdShdRq : 19|4@0+ (1,0) [0|15] "" Vector__XXX
 SG_ DrSbltAtcV : 2|1@0+ (1,0) [0|1] ""  IPC_HS
 SG_ TrlrHtchSwAtv : 0|1@0+ (1,0) [0|1] "" Vector__XXX
 SG_ TreInfMonSysRstReq : 7|1@0+ (1,0) [0|1] "" Vector__XXX
 SG_ HUDActv : 6|1@0+ (1,0) [0|1] "" Vector__XXX
 SG_ BatVltV : 1|1@0+ (1,0) [0|1] ""  IPC_HS
 SG_ BatVlt : 31|8@0+ (0.1,3) [3|28.5] "volts"  TPM_HS,IPC_HS
 SG_ RLDoorAjarSwAct : 8|1@0+ (1,0) [0|1] ""  IPC_HS
 SG_ DrSbltAtc : 12|1@0+ (1,0) [0|1] ""  IPC_HS

BO_ 1601 USDT_Resp_From_BCM_HS: 8 BCM_HS
 SG_ DgnInf : 7|64@0+ (1,0) [0|1.8446744074E+019] ""  TestTool_HS

BO_ 2018 USDT_Req_to_TCM_MTA_MTIO_HS: 8 TestTool_HS
 SG_ DgnInf : 7|64@0+ (1,0) [0|1.8446744074E+019] ""  TCM_HS

BO_ 2026 USDT_Resp_From_TCM_MTA_MTIO_HS: 8 TCM_HS
 SG_ DgnInf : 7|64@0+ (1,0) [0|1.8446744074E+019] ""  TestTool_HS

BO_ 1514 UUDT_Resp_From_TCM_MTA_MTIO_HS: 8 TCM_HS
 SG_ DgnInf : 7|64@0+ (1,0) [0|1.8446744074E+019] ""  TestTool_HS

BO_ 288 Vehicle_Odometer_HS: 5 IPC_HS
 SG_ VehOdo : 7|32@0+ (0.015625,0) [0|67108863.984] "km"  BCM_HS
 SG_ VehOdoV : 32|1@0+ (1,0) [0|1] ""  BCM_HS

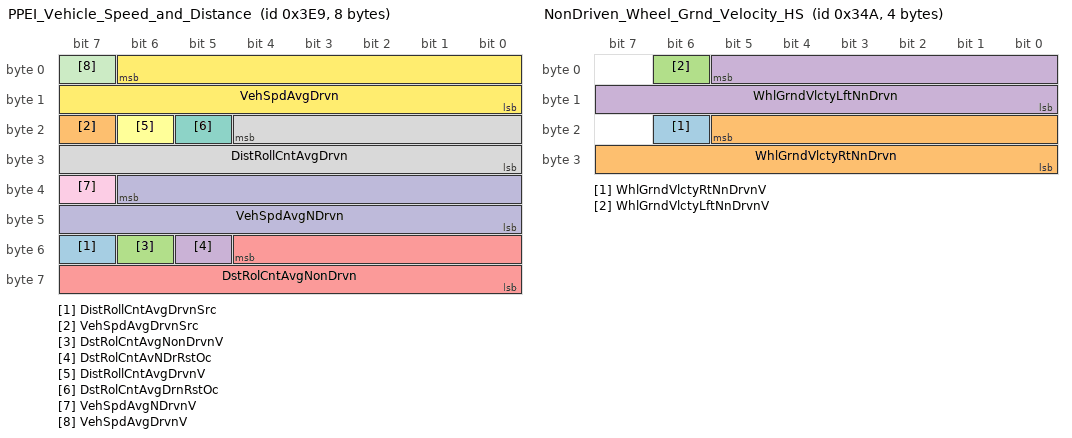
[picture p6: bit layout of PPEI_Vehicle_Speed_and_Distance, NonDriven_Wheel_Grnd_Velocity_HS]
BO_ 1001 PPEI_Vehicle_Speed_and_Distance: 8 ECM_HS
 SG_ DistRollCntAvgDrvnSrc : 55|1@0+ (1,0) [0|1] ""  EPS_HS,IPC_HS,TCM_HS,BCM_HS
 SG_ VehSpdAvgDrvnSrc : 23|1@0+ (1,0) [0|1] ""  EPS_HS,IPC_HS,BCM_HS
 SG_ DstRolCntAvgNonDrvnV : 54|1@0+ (1,0) [0|1] ""  EPS_HS,IPC_HS,BCM_HS
 SG_ DstRolCntAvNDrRstOc : 53|1@0+ (1,0) [0|1] ""  EPS_HS,IPC_HS,BCM_HS
 SG_ DstRolCntAvgNonDrvn : 52|13@0+ (0.125,0) [0|1023.875] "m"  EPS_HS,IPC_HS,BCM_HS
 SG_ DistRollCntAvgDrvnV : 22|1@0+ (1,0) [0|1] ""  EPS_HS,IPC_HS,TCM_HS,BCM_HS
 SG_ DstRolCntAvgDrnRstOc : 21|1@0+ (1,0) [0|1] ""  EPS_HS,IPC_HS,TCM_HS,BCM_HS
 SG_ DistRollCntAvgDrvn : 20|13@0+ (0.125,0) [0|1023.875] "m"  EPS_HS,IPC_HS,TCM_HS,BCM_HS
 SG_ VehSpdAvgNDrvnV : 39|1@0+ (1,0) [0|1] ""  EPS_HS,IPC_HS,BCM_HS
 SG_ VehSpdAvgNDrvn : 38|15@0+ (0.015625,0) [0|511.984375] "km / h"  EPS_HS,IPC_HS,BCM_HS
 SG_ VehSpdAvgDrvnV : 7|1@0+ (1,0) [0|1] ""  TPM_HS,EPS_HS,IPC_HS,BCM_HS
 SG_ VehSpdAvgDrvn : 6|15@0+ (0.015625,0) [0|511.984375] "km / h"  TPM_HS,EPS_HS,IPC_HS,BCM_HS

BO_ 961 PPEI_Powertrain_Immobilizer_Data: 8 ECM_HS
 SG_ PTImmblzerInfo : 7|64@0+ (1,0) [0|1.8446744074E+019] ""  BCM_HS

BO_ 842 NonDriven_Wheel_Grnd_Velocity_HS: 4 EBCM_HS
 SG_ WhlGrndVlctyRtNnDrvnV : 22|1@0+ (1,0) [0|1] ""  EPS_HS,IPC_HS,BCM_HS
 SG_ WhlGrndVlctyRtNnDrvn : 21|14@0+ (0.03125,0) [0|511.96875] "km / h"  EPS_HS,IPC_HS,BCM_HS
 SG_ WhlGrndVlctyLftNnDrvnV : 6|1@0+ (1,0) [0|1] ""  EPS_HS,IPC_HS,BCM_HS
 SG_ WhlGrndVlctyLftNnDrvn : 5|14@0+ (0.03125,0) [0|511.96875] "km / h"  EPS_HS,IPC_HS,BCM_HS

BO_TX_BU_ 249 : TCM_HS,ECM_HS;
CM_ SG_ 1249 VehIdNmDig10_17 "Desc: 8 ASCII Characters";
CM_ SG_ 481 AuxHtrRq "Auxiliary Heater shall be used to denote a heater function that uses some kind of power, electrical or mechanical,  that was generated by the engine.";
CM_ SG_ 481 AuxHtrAtv "Auxiliary Heater shall be used to denote a heater function that uses some kind of power, electrical or mechanical,  that was generated by the engine.";
CM_ BO_ 489 "Changed for PPEI 3.6";
CM_ SG_ 381 BrkSysRedBrkTlltlReq "Added acc to Björn 0410";
CM_ SG_ 241 BrkPdlModTrvlV "Indicates that the brake pedal position has passed a threshold for brake torque management and some 2 channel Vehicle Dynamics Control systems.";
CM_ SG_ 241 BrkPdlModTrvl "Indicates that the brake pedal position has passed a threshold for brake torque management and some 2 channel Vehicle Dynamics Control systems.";
CM_ SG_ 532 BrkSysAutBrkFld "BrakeSystemAutomaticBrakingFailed";
CM_ SG_ 532 IntBrkAssPreFilReq "IntelligentBrakeAssistPreFillRequest";
CM_ SG_ 320 IntDimDspLvlPlt "Change short and long name to differ from signal IntDimDspLvl of PPEI_Platform_Eng_Cntrl_Requests. 20110629";
CM_ SG_ 320 MainLghtSw "Operator selection for the main lighting switch";
CM_ SG_ 320 AutLghtCtrl "This signal represents if Automatic Lights Control feature is active/inactive";
CM_ SG_ 1919 DTCI_DTCFaultType_77F "Based on Powertrain definition.  Not expected to be supported by all devices.";
CM_ SG_ 1919 DTCI_DTCFailType_77F "Assigned per GMW3110, Appendix E";
CM_ SG_ 1919 DTCI_DTCSource_77F "This shall be equal to the Diagnostic Address of the transmittting device.";
CM_ SG_ 499 PFTrnsTUDSecSwSt "Added 2006 Nov 10 according to CR1112";
CM_ SG_ 1906 DTCI_DTCFaultType_772 "Based on Powertrain definition.  Not expected to be supported by all devices.";
CM_ SG_ 1906 DTCI_DTCFailType_772 "Assigned per GMW3110, Appendix E";
CM_ SG_ 1906 DTCI_DTCSource_772 "This shall be equal to the Diagnostic Address of the transmittting device.";
CM_ SG_ 298 DrId "Driver 8 changed to Unknown on 3/30/99";
BA_DEF_ SG_  "VNSigSLHS_VNReq" ENUM  "No","Yes";
BA_DEF_ SG_  "VNSigSLHSSharedDiagnostic" ENUM  "No","Yes";
BA_DEF_ SG_  "SignalType" STRING ;
BA_DEF_ SG_  "PacketOrder" INT 0 65535;
BA_DEF_ SG_  "SignalLongName" STRING ;
BA_DEF_ SG_  "GenSigStartValue" INT 0 65535;
BA_DEF_ SG_  "VNSigAllNodes" ENUM  "No","Yes";
BA_DEF_ SG_  "GenSigDeltaValue" INT 0 0;
BA_DEF_ SG_  "GenSigSendType_signal" ENUM  "not used","not used","not used","not used","not used","not used","not used","NoSigSendType","not used","not used","OnAnyChange","OnChangeIfActive","OnDelta";
BA_DEF_ SG_  "GenSigSendOnInit_signal" ENUM  "Not Initialized","Application","Handler";
BA_DEF_ SG_  "GenSigSendType" ENUM  "not used","not used","not used","not used","not used","not used","not used","NoSigSendType","not used","not used","OnAnyChange","OnChangeIfActive","OnDelta";
BA_DEF_ SG_  "GenSigSendOnInit" ENUM  "Not Initialized","Application","Handler";
BA_DEF_ BO_  "GenMsgILSupport" ENUM  "No","Yes";
BA_DEF_ BO_  "TpApplType" STRING ;
BA_DEF_ BO_  "Prio" INT 0 7;
BA_DEF_ BO_  "MessageSubnet" ENUM  "LS","MS","HS","CE","PE","CC";
BA_DEF_ BO_  "DiagState" ENUM  "No","Yes";
BA_DEF_ BO_  "GenMsgDelayTime" INT 0 100000;
BA_DEF_ BO_  "GenMsgCycleTime" INT 0 100000;
BA_DEF_ BO_  "GenMsgSendType" ENUM  "cyclicX","spontanX","cyclicIfActiveX","spontanWithDelay","cyclicAndSpontanX","cyclicAndSpontanWithDelay","spontanWithRepitition","cyclicIfActiveAndSpontanWD";
BA_DEF_ BO_  "DiagResponse" ENUM  "No","Yes";
BA_DEF_ BO_  "DiagRequest" ENUM  "No","Yes";
BA_DEF_ BO_  "NmMessage" ENUM  "No","Yes";
BA_DEF_REL_ BU_SG_REL_  "GenSigSuprvRespComment" STRING ;
BA_DEF_REL_ BU_SG_REL_  "GenSigVBitResp" ENUM  "No","Yes";
BA_DEF_REL_ BU_SG_REL_  "GenSigVBitRespComment" STRING ;
BA_DEF_REL_ BU_SG_REL_  "GenSigVDAFailComment" STRING ;
BA_DEF_REL_ BU_SG_REL_  "GenSigVDAFailResp" ENUM  "No","Yes";
BA_DEF_REL_ BU_SG_REL_  "GenSigRxStartValue" STRING ;
BA_DEF_REL_ BU_SG_REL_  "GenSigSuprvRespSubValue" INT 0 65535;
BA_DEF_REL_ BU_SG_REL_  "GenSigSuprvResp" ENUM  "None","Notify App","Substitute Default";
BA_DEF_REL_ BU_SG_REL_  "GenSigTimeoutMsg" HEX -2147483648 268435455;
BA_DEF_REL_ BU_SG_REL_  "GenSigTimeoutTime" INT 0 15000;
BA_DEF_DEF_  "VNSigSLHS_VNReq" "No";
BA_DEF_DEF_  "VNSigSLHSSharedDiagnostic" "No";
BA_DEF_DEF_  "SignalType" "";
BA_DEF_DEF_  "PacketOrder" 0;
BA_DEF_DEF_  "SignalLongName" "";
BA_DEF_DEF_  "GenSigStartValue" 0;
BA_DEF_DEF_  "VNSigAllNodes" "No";
BA_DEF_DEF_  "GenSigDeltaValue" 0;
BA_DEF_DEF_  "GenSigSendType_signal" "NoSigSendType";
BA_DEF_DEF_  "GenSigSendOnInit_signal" "Not Initialized";
BA_DEF_DEF_  "GenSigSendType" "NoSigSendType";
BA_DEF_DEF_  "GenSigSendOnInit" "Not Initialized";
BA_DEF_DEF_  "GenMsgILSupport" "Yes";
BA_DEF_DEF_  "TpApplType" "";
BA_DEF_DEF_  "Prio" 4;
BA_DEF_DEF_  "MessageSubnet" "LS";
BA_DEF_DEF_  "DiagState" "No";
BA_DEF_DEF_  "GenMsgDelayTime" 0;
BA_DEF_DEF_  "GenMsgCycleTime" 0;
BA_DEF_DEF_  "GenMsgSendType" "spontanX";
BA_DEF_DEF_  "DiagResponse" "No";
BA_DEF_DEF_  "DiagRequest" "No";
BA_DEF_DEF_  "NmMessage" "No";
BA_DEF_DEF_REL_ "GenSigSuprvRespComment" "";
BA_DEF_DEF_REL_ "GenSigVBitResp" "No";
BA_DEF_DEF_REL_ "GenSigVBitRespComment" "";
BA_DEF_DEF_REL_ "GenSigVDAFailComment" "";
BA_DEF_DEF_REL_ "GenSigVDAFailResp" "No";
BA_DEF_DEF_REL_ "GenSigRxStartValue" "";
BA_DEF_DEF_REL_ "GenSigSuprvRespSubValue" 0;
BA_DEF_DEF_REL_ "GenSigSuprvResp" "None";
BA_DEF_DEF_REL_ "GenSigTimeoutMsg" 0;
BA_DEF_DEF_REL_ "GenSigTimeoutTime" 0;
BA_ "GenMsgSendType" BO_ 249 0;
BA_ "GenMsgCycleTime" BO_ 249 12;
BA_ "MessageSubnet" BO_ 249 2;
BA_ "Prio" BO_ 249 0;
BA_ "GenMsgSendType" BO_ 1009 0;
BA_ "GenMsgCycleTime" BO_ 1009 250;
BA_ "MessageSubnet" BO_ 1009 2;
BA_ "Prio" BO_ 1009 0;
BA_ "GenMsgSendType" BO_ 1257 0;
BA_ "GenMsgCycleTime" BO_ 1257 1000;
BA_ "MessageSubnet" BO_ 1257 2;
BA_ "Prio" BO_ 1257 0;
BA_ "GenMsgSendType" BO_ 497 0;
BA_ "GenMsgCycleTime" BO_ 497 100;
BA_ "GenMsgDelayTime" BO_ 497 30;
BA_ "MessageSubnet" BO_ 497 2;
BA_ "Prio" BO_ 497 0;
BA_ "GenMsgSendType" BO_ 969 0;
BA_ "GenMsgCycleTime" BO_ 969 100;
BA_ "MessageSubnet" BO_ 969 2;
BA_ "Prio" BO_ 969 0;
BA_ "GenMsgSendType" BO_ 1249 0;
BA_ "GenMsgCycleTime" BO_ 1249 1000;
BA_ "MessageSubnet" BO_ 1249 2;
BA_ "Prio" BO_ 1249 0;
BA_ "DiagResponse" BO_ 2024 1;
BA_ "MessageSubnet" BO_ 2024 2;
BA_ "Prio" BO_ 2024 0;
BA_ "MessageSubnet" BO_ 1512 2;
BA_ "Prio" BO_ 1512 0;
BA_ "TpApplType" BO_ 1512 "DiagUUDTResponse";
BA_ "GenMsgILSupport" BO_ 1512 0;
BA_ "GenMsgSendType" BO_ 840 0;
BA_ "GenMsgCycleTime" BO_ 840 50;
BA_ "MessageSubnet" BO_ 840 2;
BA_ "Prio" BO_ 840 0;
BA_ "GenMsgSendType" BO_ 193 0;
BA_ "GenMsgCycleTime" BO_ 193 10;
BA_ "MessageSubnet" BO_ 193 2;
BA_ "Prio" BO_ 193 0;
BA_ "GenMsgSendType" BO_ 481 0;
BA_ "GenMsgCycleTime" BO_ 481 30;
BA_ "MessageSubnet" BO_ 481 2;
BA_ "Prio" BO_ 481 0;
BA_ "GenMsgSendType" BO_ 761 0;
BA_ "GenMsgCycleTime" BO_ 761 50;
BA_ "MessageSubnet" BO_ 761 2;
BA_ "Prio" BO_ 761 0;
BA_ "GenMsgSendType" BO_ 489 0;
BA_ "GenMsgCycleTime" BO_ 489 20;
BA_ "MessageSubnet" BO_ 489 2;
BA_ "Prio" BO_ 489 0;
BA_ "GenMsgSendType" BO_ 381 0;
BA_ "GenMsgCycleTime" BO_ 381 100;
BA_ "MessageSubnet" BO_ 381 2;
BA_ "Prio" BO_ 381 0;
BA_ "GenMsgSendType" BO_ 241 0;
BA_ "GenMsgCycleTime" BO_ 241 10;
BA_ "MessageSubnet" BO_ 241 2;
BA_ "Prio" BO_ 241 0;
BA_ "MessageSubnet" BO_ 1356 2;
BA_ "Prio" BO_ 1356 0;
BA_ "TpApplType" BO_ 1356 "DiagUUDTResponse";
BA_ "GenMsgILSupport" BO_ 1356 0;
BA_ "GenMsgSendType" BO_ 500 0;
BA_ "GenMsgCycleTime" BO_ 500 25;
BA_ "GenMsgDelayTime" BO_ 500 62;
BA_ "MessageSubnet" BO_ 500 2;
BA_ "Prio" BO_ 500 0;
BA_ "GenMsgSendType" BO_ 407 0;
BA_ "GenMsgCycleTime" BO_ 407 25;
BA_ "MessageSubnet" BO_ 407 2;
BA_ "Prio" BO_ 407 0;
BA_ "GenMsgSendType" BO_ 1221 0;
BA_ "GenMsgCycleTime" BO_ 1221 500;
BA_ "MessageSubnet" BO_ 1221 2;
BA_ "Prio" BO_ 1221 0;
BA_ "GenMsgSendType" BO_ 738 0;
BA_ "GenMsgCycleTime" BO_ 738 100;
BA_ "MessageSubnet" BO_ 738 2;
BA_ "Prio" BO_ 738 0;
BA_ "GenMsgSendType" BO_ 431 0;
BA_ "GenMsgCycleTime" BO_ 431 25;
BA_ "MessageSubnet" BO_ 431 2;
BA_ "Prio" BO_ 431 0;
BA_ "MessageSubnet" BO_ 1345 2;
BA_ "Prio" BO_ 1345 0;
BA_ "TpApplType" BO_ 1345 "DiagUUDTResponse";
BA_ "GenMsgILSupport" BO_ 1345 0;
BA_ "GenMsgSendType" BO_ 309 0;
BA_ "GenMsgCycleTime" BO_ 309 100;
BA_ "MessageSubnet" BO_ 309 2;
BA_ "Prio" BO_ 309 0;
BA_ "GenMsgSendType" BO_ 532 0;
BA_ "GenMsgCycleTime" BO_ 532 50;
BA_ "MessageSubnet" BO_ 532 2;
BA_ "Prio" BO_ 532 0;
BA_ "GenMsgSendType" BO_ 451 0;
BA_ "GenMsgCycleTime" BO_ 451 25;
BA_ "MessageSubnet" BO_ 451 2;
BA_ "Prio" BO_ 451 0;
BA_ "GenMsgSendType" BO_ 320 0;
BA_ "GenMsgCycleTime" BO_ 320 30;
BA_ "GenMsgDelayTime" BO_ 320 10;
BA_ "MessageSubnet" BO_ 320 2;
BA_ "Prio" BO_ 320 0;
BA_ "GenMsgSendType" BO_ 1919 0;
BA_ "GenMsgCycleTime" BO_ 1919 1000;
BA_ "MessageSubnet" BO_ 1919 2;
BA_ "Prio" BO_ 1919 6;
BA_ "DiagRequest" BO_ 588 1;
BA_ "MessageSubnet" BO_ 588 2;
BA_ "Prio" BO_ 588 0;
BA_ "GenMsgSendType" BO_ 499 0;
BA_ "GenMsgCycleTime" BO_ 499 30;
BA_ "MessageSubnet" BO_ 499 2;
BA_ "Prio" BO_ 499 0;
BA_ "GenMsgSendType" BO_ 1906 0;
BA_ "GenMsgCycleTime" BO_ 1906 1000;
BA_ "MessageSubnet" BO_ 1906 2;
BA_ "Prio" BO_ 1906 6;
BA_ "DiagRequest" BO_ 579 1;
BA_ "MessageSubnet" BO_ 579 2;
BA_ "Prio" BO_ 579 0;
BA_ "DiagResponse" BO_ 1603 1;
BA_ "MessageSubnet" BO_ 1603 2;
BA_ "Prio" BO_ 1603 0;
BA_ "MessageSubnet" BO_ 1347 2;
BA_ "Prio" BO_ 1347 0;
BA_ "TpApplType" BO_ 1347 "DiagUUDTResponse";
BA_ "GenMsgILSupport" BO_ 1347 0;
BA_ "DiagRequest" BO_ 577 1;
BA_ "MessageSubnet" BO_ 577 2;
BA_ "Prio" BO_ 577 0;
BA_ "GenMsgSendType" BO_ 298 0;
BA_ "GenMsgCycleTime" BO_ 298 100;
BA_ "MessageSubnet" BO_ 298 2;
BA_ "Prio" BO_ 298 0;
BA_ "DiagResponse" BO_ 1601 1;
BA_ "MessageSubnet" BO_ 1601 2;
BA_ "Prio" BO_ 1601 0;
BA_ "DiagRequest" BO_ 2018 1;
BA_ "MessageSubnet" BO_ 2018 2;
BA_ "Prio" BO_ 2018 0;
BA_ "DiagResponse" BO_ 2026 1;
BA_ "MessageSubnet" BO_ 2026 2;
BA_ "Prio" BO_ 2026 0;
BA_ "MessageSubnet" BO_ 1514 2;
BA_ "Prio" BO_ 1514 0;
BA_ "TpApplType" BO_ 1514 "DiagUUDTResponse";
BA_ "GenMsgILSupport" BO_ 1514 0;
BA_ "GenMsgSendType" BO_ 288 0;
BA_ "GenMsgCycleTime" BO_ 288 1000;
BA_ "MessageSubnet" BO_ 288 2;
BA_ "Prio" BO_ 288 0;
BA_ "GenMsgSendType" BO_ 1001 0;
BA_ "GenMsgCycleTime" BO_ 1001 100;
BA_ "MessageSubnet" BO_ 1001 2;
BA_ "Prio" BO_ 1001 0;
BA_ "GenMsgSendType" BO_ 961 0;
BA_ "GenMsgCycleTime" BO_ 961 100;
BA_ "MessageSubnet" BO_ 961 2;
BA_ "Prio" BO_ 961 0;
BA_ "GenMsgSendType" BO_ 842 0;
BA_ "GenMsgCycleTime" BO_ 842 50;
BA_ "MessageSubnet" BO_ 842 2;
BA_ "Prio" BO_ 842 0;
BA_ "VNSigAllNodes" SG_ 249 TnCCVehSpShftEvTh 1;
BA_ "SignalLongName" SG_ 249 TnCCVehSpShftEvTh "Transmission Cruise Control Vehicle Speed Shift Event Threshold";
BA_ "SignalType" SG_ 249 TnCCVehSpShftEvTh "UNM";
BA_ "VNSigAllNodes" SG_ 249 TrnsOtptRotRC 1;
BA_ "SignalLongName" SG_ 249 TrnsOtptRotRC "Transmission Output Rotations Rolling Count";
BA_ "SignalType" SG_ 249 TrnsOtptRotRC "UNM";
BA_ "VNSigAllNodes" SG_ 249 TrnsOtptRotRCRstOcc 1;
BA_ "SignalLongName" SG_ 249 TrnsOtptRotRCRstOcc "Transmission Output Rotations Rolling Count Reset Occurred";
BA_ "SignalType" SG_ 249 TrnsOtptRotRCRstOcc "BLN";
BA_ "VNSigAllNodes" SG_ 249 TrnsOtptRotRCV 1;
BA_ "SignalLongName" SG_ 249 TrnsOtptRotRCV "Transmission Output Rotations Rolling Count Validity";
BA_ "SignalType" SG_ 249 TrnsOtptRotRCV "ENM";
BA_ "VNSigAllNodes" SG_ 249 TrnsOtptShftAngVelSnrPr 1;
BA_ "SignalLongName" SG_ 249 TrnsOtptShftAngVelSnrPr "Transmission Output Shaft Angular Velocity Sensor Present";
BA_ "SignalType" SG_ 249 TrnsOtptShftAngVelSnrPr "BLN";
BA_ "VNSigAllNodes" SG_ 249 TrnsOutShftAngVel 1;
BA_ "SignalLongName" SG_ 249 TrnsOutShftAngVel "Transmission Output Shaft Angular Velocity";
BA_ "SignalType" SG_ 249 TrnsOutShftAngVel "UNM";
BA_ "VNSigAllNodes" SG_ 249 TrnsOutShftAngVelV 1;
BA_ "SignalLongName" SG_ 249 TrnsOutShftAngVelV "Transmission Output Shaft Angular Velocity Validity";
BA_ "SignalType" SG_ 249 TrnsOutShftAngVelV "ENM";
BA_ "VNSigAllNodes" SG_ 249 TrnsOvrallEstTorqRatio 1;
BA_ "SignalLongName" SG_ 249 TrnsOvrallEstTorqRatio "Transmission Overall Estimated Torque Ratio";
BA_ "SignalType" SG_ 249 TrnsOvrallEstTorqRatio "SNM";
BA_ "VNSigAllNodes" SG_ 249 TrnsOvrallEstTorqRatioV 1;
BA_ "SignalLongName" SG_ 249 TrnsOvrallEstTorqRatioV "Transmission Overall Estimated Torque Ratio Validity";
BA_ "SignalType" SG_ 249 TrnsOvrallEstTorqRatioV "ENM";
BA_ "VNSigAllNodes" SG_ 1009 ACCmEngRunReq 1;
BA_ "SignalLongName" SG_ 1009 ACCmEngRunReq "Air Conditioning Compressor Engine Run Request";
BA_ "SignalType" SG_ 1009 ACCmEngRunReq "ENM";
BA_ "VNSigAllNodes" SG_ 1009 OutAirTempVDA 1;
BA_ "GenSigStartValue" SG_ 1009 OutAirTempVDA 1;
BA_ "SignalLongName" SG_ 1009 OutAirTempVDA "Outside Air Temperature Virtual Device Availability";
BA_ "SignalType" SG_ 1009 OutAirTempVDA "ENM";
BA_ "VNSigAllNodes" SG_ 1009 OtsAirTmpCrValV 1;
BA_ "SignalLongName" SG_ 1009 OtsAirTmpCrValV "Outside Air Temperature Corrected Value Validity";
BA_ "SignalType" SG_ 1009 OtsAirTmpCrValV "ENM";
BA_ "VNSigAllNodes" SG_ 1009 OtsAirTmpCrVal 1;
BA_ "SignalLongName" SG_ 1009 OtsAirTmpCrVal "Outside Air Temperature Corrected Value";
BA_ "SignalType" SG_ 1009 OtsAirTmpCrVal "UNM";
BA_ "VNSigAllNodes" SG_ 1009 EngOffTmVDA 1;
BA_ "GenSigStartValue" SG_ 1009 EngOffTmVDA 1;
BA_ "SignalLongName" SG_ 1009 EngOffTmVDA "Engine Off Time Virtual Device Availability";
BA_ "SignalType" SG_ 1009 EngOffTmVDA "ENM";
BA_ "VNSigAllNodes" SG_ 1009 ClntCircPmpRq 1;
BA_ "SignalLongName" SG_ 1009 ClntCircPmpRq "Coolant Circulation Pump Request";
BA_ "SignalType" SG_ 1009 ClntCircPmpRq "ENM";
BA_ "VNSigAllNodes" SG_ 1009 IntDimDspLvl 1;
BA_ "SignalLongName" SG_ 1009 IntDimDspLvl "Interior Dimming Display Level";
BA_ "SignalType" SG_ 1009 IntDimDspLvl "UNM";
BA_ "VNSigAllNodes" SG_ 1009 EngOffTmExtRngV 1;
BA_ "SignalLongName" SG_ 1009 EngOffTmExtRngV "Engine Off Time Extended Range Validity";
BA_ "SignalType" SG_ 1009 EngOffTmExtRngV "ENM";
BA_ "VNSigAllNodes" SG_ 1009 EngOffTmExtRng 1;
BA_ "SignalLongName" SG_ 1009 EngOffTmExtRng "Engine Off Time Extended Range";
BA_ "SignalType" SG_ 1009 EngOffTmExtRng "UNM";
BA_ "VNSigAllNodes" SG_ 1009 PF_MinIdlBstLvlReq 1;
BA_ "SignalLongName" SG_ 1009 PF_MinIdlBstLvlReq "Platform Minimum Idle Boost Level Request";
BA_ "SignalType" SG_ 1009 PF_MinIdlBstLvlReq "ENM";
BA_ "VNSigAllNodes" SG_ 1009 GenRgSPDtyCycRq 1;
BA_ "SignalLongName" SG_ 1009 GenRgSPDtyCycRq "Generator Regulator Setpoint Duty Cycle Request";
BA_ "SignalType" SG_ 1009 GenRgSPDtyCycRq "UNM";
BA_ "VNSigAllNodes" SG_ 1009 VehTopSpdLmtReq 1;
BA_ "SignalLongName" SG_ 1009 VehTopSpdLmtReq "Vehicle Top Speed Limit Request";
BA_ "SignalType" SG_ 1009 VehTopSpdLmtReq "UNM";
BA_ "VNSigAllNodes" SG_ 1009 EngCoolFanSpAdj 1;
BA_ "SignalLongName" SG_ 1009 EngCoolFanSpAdj "Engine Cooling Fan Speed Adjustment";
BA_ "SignalType" SG_ 1009 EngCoolFanSpAdj "SNM";
BA_ "VNSigAllNodes" SG_ 1257 EngPrfID 1;
BA_ "SignalLongName" SG_ 1257 EngPrfID "Engine Performance Identifier";
BA_ "SignalType" SG_ 1257 EngPrfID "UNM";
BA_ "VNSigAllNodes" SG_ 1257 ElpsdTimeCntRstOcc 1;
BA_ "SignalLongName" SG_ 1257 ElpsdTimeCntRstOcc "Elapsed Time Count Reset Occurred";
BA_ "SignalType" SG_ 1257 ElpsdTimeCntRstOcc "BLN";
BA_ "VNSigAllNodes" SG_ 1257 ElpsdTimeCnt 1;
BA_ "SignalLongName" SG_ 1257 ElpsdTimeCnt "Elapsed Time Count";
BA_ "SignalType" SG_ 1257 ElpsdTimeCnt "UNM";
BA_ "VNSigAllNodes" SG_ 1257 ACCompType 1;
BA_ "SignalLongName" SG_ 1257 ACCompType "Air Conditioning Compressor Type";
BA_ "SignalType" SG_ 1257 ACCompType "ENM";
BA_ "VNSigAllNodes" SG_ 1257 VSESysPrs 1;
BA_ "SignalLongName" SG_ 1257 VSESysPrs "Vehicle Stability Enhancement System Present";
BA_ "SignalType" SG_ 1257 VSESysPrs "BLN";
BA_ "VNSigAllNodes" SG_ 1257 ABSPr 1;
BA_ "SignalLongName" SG_ 1257 ABSPr "Antilock Brake System Present";
BA_ "SignalType" SG_ 1257 ABSPr "BLN";
BA_ "VNSigAllNodes" SG_ 1257 TCSysPr 1;
BA_ "SignalLongName" SG_ 1257 TCSysPr "Traction Control System Present";
BA_ "SignalType" SG_ 1257 TCSysPr "BLN";
BA_ "VNSigAllNodes" SG_ 1257 VehSpdCntlSystmType 1;
BA_ "SignalLongName" SG_ 1257 VehSpdCntlSystmType "Vehicle Speed Control System Type";
BA_ "SignalType" SG_ 1257 VehSpdCntlSystmType "ENM";
BA_ "VNSigAllNodes" SG_ 1257 PltfrmEngSpdCmdSysTp 1;
BA_ "SignalLongName" SG_ 1257 PltfrmEngSpdCmdSysTp "Platform Engine Speed Command System Type";
BA_ "SignalType" SG_ 1257 PltfrmEngSpdCmdSysTp "ENM";
BA_ "GenSigSendType_signal" SG_ 497 FuelFltLfRstRqd 10;
BA_ "VNSigAllNodes" SG_ 497 FuelFltLfRstRqd 1;
BA_ "SignalLongName" SG_ 497 FuelFltLfRstRqd "Fuel Filter Life Reset Requested";
BA_ "SignalType" SG_ 497 FuelFltLfRstRqd "BLN";
BA_ "GenSigSendType_signal" SG_ 497 ACCompSysVDA 10;
BA_ "VNSigAllNodes" SG_ 497 ACCompSysVDA 1;
BA_ "GenSigStartValue" SG_ 497 ACCompSysVDA 1;
BA_ "SignalLongName" SG_ 497 ACCompSysVDA "Air Conditioning Compressor System Virtual Device Availability";
BA_ "SignalType" SG_ 497 ACCompSysVDA "ENM";
BA_ "GenSigSendType_signal" SG_ 497 BkupPwrModeMstrVDA 10;
BA_ "VNSigAllNodes" SG_ 497 BkupPwrModeMstrVDA 1;
BA_ "GenSigStartValue" SG_ 497 BkupPwrModeMstrVDA 1;
BA_ "SignalLongName" SG_ 497 BkupPwrModeMstrVDA "Backup Power Mode Master Virtual Device Availability";
BA_ "SignalType" SG_ 497 BkupPwrModeMstrVDA "ENM";
BA_ "GenSigSendType_signal" SG_ 497 PrkBrkVDA 10;
BA_ "VNSigAllNodes" SG_ 497 PrkBrkVDA 1;
BA_ "GenSigStartValue" SG_ 497 PrkBrkVDA 1;
BA_ "SignalLongName" SG_ 497 PrkBrkVDA "Park Brake Virtual Device Availability";
BA_ "SignalType" SG_ 497 PrkBrkVDA "ENM";
BA_ "GenSigSendType_signal" SG_ 497 PrkBrkVDM 10;
BA_ "VNSigAllNodes" SG_ 497 PrkBrkVDM 1;
BA_ "GenSigStartValue" SG_ 497 PrkBrkVDM 1;
BA_ "SignalLongName" SG_ 497 PrkBrkVDM "Park Brake Virtual Device Mask";
BA_ "SignalType" SG_ 497 PrkBrkVDM "ENM";
BA_ "GenSigSendType_signal" SG_ 497 BkupPwrModeMstrVDM 10;
BA_ "VNSigAllNodes" SG_ 497 BkupPwrModeMstrVDM 1;
BA_ "SignalLongName" SG_ 497 BkupPwrModeMstrVDM "Backup Power Mode Master Virtual Device Mask";
BA_ "SignalType" SG_ 497 BkupPwrModeMstrVDM "ENM";
BA_ "GenSigSendType_signal" SG_ 497 ACCompSysVDM 10;
BA_ "VNSigAllNodes" SG_ 497 ACCompSysVDM 1;
BA_ "SignalLongName" SG_ 497 ACCompSysVDM "Air Conditioning Compressor System Virtual Device Mask";
BA_ "SignalType" SG_ 497 ACCompSysVDM "ENM";
BA_ "GenSigSendType_signal" SG_ 497 AirbgVDA 10;
BA_ "VNSigAllNodes" SG_ 497 AirbgVDA 1;
BA_ "GenSigStartValue" SG_ 497 AirbgVDA 1;
BA_ "SignalLongName" SG_ 497 AirbgVDA "Airbag Virtual Device Availability";
BA_ "SignalType" SG_ 497 AirbgVDA "ENM";
BA_ "GenSigSendType_signal" SG_ 497 SysBkupPwrMdEn 10;
BA_ "VNSigAllNodes" SG_ 497 SysBkupPwrMdEn 1;
BA_ "SignalLongName" SG_ 497 SysBkupPwrMdEn "System Backup Power Mode Enabled";
BA_ "SignalType" SG_ 497 SysBkupPwrMdEn "BLN";
BA_ "GenSigSendType_signal" SG_ 497 SysBkUpPwrMd 10;
BA_ "VNSigAllNodes" SG_ 497 SysBkUpPwrMd 1;
BA_ "SignalLongName" SG_ 497 SysBkUpPwrMd "System Backup Power Mode";
BA_ "SignalType" SG_ 497 SysBkUpPwrMd "ENM";
BA_ "GenSigSendType_signal" SG_ 497 SysPwrMd 10;
BA_ "VNSigAllNodes" SG_ 497 SysPwrMd 1;
BA_ "SignalLongName" SG_ 497 SysPwrMd "System Power Mode";
BA_ "SignalType" SG_ 497 SysPwrMd "ENM";
BA_ "GenSigSendType_signal" SG_ 497 TrStLgMdAtv 10;
BA_ "VNSigAllNodes" SG_ 497 TrStLgMdAtv 1;
BA_ "SignalLongName" SG_ 497 TrStLgMdAtv "Transport Storage Logistic Mode Active";
BA_ "SignalType" SG_ 497 TrStLgMdAtv "BLN";
BA_ "GenSigSendType_signal" SG_ 497 DispMeasSys 10;
BA_ "VNSigAllNodes" SG_ 497 DispMeasSys 1;
BA_ "SignalLongName" SG_ 497 DispMeasSys "Display Measurement System";
BA_ "SignalType" SG_ 497 DispMeasSys "ENM";
BA_ "GenSigSendType_signal" SG_ 497 ACCmpsrFldOn 10;
BA_ "VNSigAllNodes" SG_ 497 ACCmpsrFldOn 1;
BA_ "SignalLongName" SG_ 497 ACCmpsrFldOn "Air Conditioning Compressor Failed On";
BA_ "SignalType" SG_ 497 ACCmpsrFldOn "BLN";
BA_ "GenSigSendType_signal" SG_ 497 ACCompModReq 10;
BA_ "VNSigAllNodes" SG_ 497 ACCompModReq 1;
BA_ "SignalLongName" SG_ 497 ACCompModReq "Air Conditioning Compressor Mode Request";
BA_ "SignalType" SG_ 497 ACCompModReq "ENM";
BA_ "GenSigSendType_signal" SG_ 497 ACCompNormLd 12;
BA_ "GenSigDeltaValue" SG_ 497 ACCompNormLd 1;
BA_ "VNSigAllNodes" SG_ 497 ACCompNormLd 1;
BA_ "SignalLongName" SG_ 497 ACCompNormLd "Air Conditioning Compressor Normalized Load";
BA_ "SignalType" SG_ 497 ACCompNormLd "UNM";
BA_ "GenSigSendType_signal" SG_ 497 ACCompNormLdV 10;
BA_ "VNSigAllNodes" SG_ 497 ACCompNormLdV 1;
BA_ "SignalLongName" SG_ 497 ACCompNormLdV "Air Conditioning Compressor Normalized Load Validity";
BA_ "SignalType" SG_ 497 ACCompNormLdV "ENM";
BA_ "GenSigSendType_signal" SG_ 497 PTORSMstrEngShtReq 10;
BA_ "VNSigAllNodes" SG_ 497 PTORSMstrEngShtReq 1;
BA_ "SignalLongName" SG_ 497 PTORSMstrEngShtReq "Power Take Off Remote Start Master Engine Shutdown Requested";
BA_ "SignalType" SG_ 497 PTORSMstrEngShtReq "BLN";
BA_ "GenSigSendType_signal" SG_ 497 EngOilLfRstRq 10;
BA_ "VNSigAllNodes" SG_ 497 EngOilLfRstRq 1;
BA_ "SignalLongName" SG_ 497 EngOilLfRstRq "Engine Oil Life Reset Request";
BA_ "SignalType" SG_ 497 EngOilLfRstRq "BLN";
BA_ "GenSigSendType_signal" SG_ 497 SIRDpl 10;
BA_ "VNSigAllNodes" SG_ 497 SIRDpl 1;
BA_ "SignalLongName" SG_ 497 SIRDpl "Airbag Deployed";
BA_ "SignalType" SG_ 497 SIRDpl "BLN";
BA_ "GenSigSendType_signal" SG_ 497 PTORmStMsEngStRq 10;
BA_ "VNSigAllNodes" SG_ 497 PTORmStMsEngStRq 1;
BA_ "SignalLongName" SG_ 497 PTORmStMsEngStRq "Power Take Off Remote Start Master Engine Start Request";
BA_ "SignalType" SG_ 497 PTORmStMsEngStRq "ENM";
BA_ "GenSigSendType_signal" SG_ 497 RmVehStrRq 10;
BA_ "VNSigAllNodes" SG_ 497 RmVehStrRq 1;
BA_ "SignalLongName" SG_ 497 RmVehStrRq "Remote Vehicle Start Request";
BA_ "SignalType" SG_ 497 RmVehStrRq "ENM";
BA_ "GenSigSendType_signal" SG_ 497 ThrtlPrgrsnReq 10;
BA_ "VNSigAllNodes" SG_ 497 ThrtlPrgrsnReq 1;
BA_ "SignalLongName" SG_ 497 ThrtlPrgrsnReq "Throttle Progression Request";
BA_ "SignalType" SG_ 497 ThrtlPrgrsnReq "ENM";
BA_ "GenSigSendType_signal" SG_ 497 PrkBrkSwAtv 10;
BA_ "VNSigAllNodes" SG_ 497 PrkBrkSwAtv 1;
BA_ "SignalLongName" SG_ 497 PrkBrkSwAtv "Park Brake Switch Active";
BA_ "SignalType" SG_ 497 PrkBrkSwAtv "BLN";
BA_ "GenSigSendType_signal" SG_ 497 PMMAccTrmSt 10;
BA_ "VNSigAllNodes" SG_ 497 PMMAccTrmSt 1;
BA_ "SignalLongName" SG_ 497 PMMAccTrmSt "Power Mode Master Accessory Terminal Status";
BA_ "SignalType" SG_ 497 PMMAccTrmSt "ENM";
BA_ "GenSigSendType_signal" SG_ 497 PMMRunCrkTrmSt 10;
BA_ "VNSigAllNodes" SG_ 497 PMMRunCrkTrmSt 1;
BA_ "SignalLongName" SG_ 497 PMMRunCrkTrmSt "Power Mode Master Run Crank Terminal Status";
BA_ "SignalType" SG_ 497 PMMRunCrkTrmSt "ENM";
BA_ "GenSigSendType_signal" SG_ 497 ImmblzrPreRelPswdStat 10;
BA_ "VNSigAllNodes" SG_ 497 ImmblzrPreRelPswdStat 1;
BA_ "SignalLongName" SG_ 497 ImmblzrPreRelPswdStat "Immobilizer Pre Release Password Status";
BA_ "SignalType" SG_ 497 ImmblzrPreRelPswdStat "ENM";
BA_ "GenSigSendType_signal" SG_ 497 ImmblzrPreRelPswrd 12;
BA_ "GenSigDeltaValue" SG_ 497 ImmblzrPreRelPswrd 1;
BA_ "VNSigAllNodes" SG_ 497 ImmblzrPreRelPswrd 1;
BA_ "SignalLongName" SG_ 497 ImmblzrPreRelPswrd "Immobilizer Pre Release Password";
BA_ "SignalType" SG_ 497 ImmblzrPreRelPswrd "UNM";
BA_ "VNSigAllNodes" SG_ 969 ImoInf 1;
BA_ "SignalLongName" SG_ 969 ImoInf "Immobilizer Information";
BA_ "SignalType" SG_ 969 ImoInf "UNM";
BA_ "VNSigAllNodes" SG_ 1249 VehIdNmDig10_17 1;
BA_ "SignalLongName" SG_ 1249 VehIdNmDig10_17 "Vehicle Identification Number Digits 10-17";
BA_ "SignalType" SG_ 1249 VehIdNmDig10_17 "ASC";
BA_ "VNSigAllNodes" SG_ 2024 DgnInf 1;
BA_ "SignalLongName" SG_ 2024 DgnInf "Diagnostic Information";
BA_ "SignalType" SG_ 2024 DgnInf "UNM";
BA_ "VNSigSLHSSharedDiagnostic" SG_ 2024 DgnInf 1;
BA_ "VNSigAllNodes" SG_ 1512 DgnInf 1;
BA_ "SignalLongName" SG_ 1512 DgnInf "Diagnostic Information";
BA_ "SignalType" SG_ 1512 DgnInf "UNM";
BA_ "VNSigSLHSSharedDiagnostic" SG_ 1512 DgnInf 1;
BA_ "VNSigAllNodes" SG_ 840 WhlGrndVlctyRtDrvnV 1;
BA_ "SignalLongName" SG_ 840 WhlGrndVlctyRtDrvnV "Wheel Ground Velocity Right Driven Validity";
BA_ "SignalType" SG_ 840 WhlGrndVlctyRtDrvnV "ENM";
BA_ "VNSigAllNodes" SG_ 840 WhlGrndVlctyRtDrvn 1;
BA_ "SignalLongName" SG_ 840 WhlGrndVlctyRtDrvn "Wheel Ground Velocity Right Driven";
BA_ "SignalType" SG_ 840 WhlGrndVlctyRtDrvn "UNM";
BA_ "VNSigAllNodes" SG_ 840 WhlGrndVlctyLftDrvnV 1;
BA_ "SignalLongName" SG_ 840 WhlGrndVlctyLftDrvnV "Wheel Ground Velocity Left Driven Validity";
BA_ "SignalType" SG_ 840 WhlGrndVlctyLftDrvnV "ENM";
BA_ "VNSigAllNodes" SG_ 840 WhlGrndVlctyLftDrvn 1;
BA_ "SignalLongName" SG_ 840 WhlGrndVlctyLftDrvn "Wheel Ground Velocity Left Driven";
BA_ "SignalType" SG_ 840 WhlGrndVlctyLftDrvn "UNM";
BA_ "VNSigAllNodes" SG_ 193 WRSLDWhlDisTpRC 1;
BA_ "SignalLongName" SG_ 193 WRSLDWhlDisTpRC "Wheel Rotational Status Left Driven : Wheel Distance Timestamp Rollover Counter";
BA_ "PacketOrder" SG_ 193 WRSLDWhlDisTpRC 1;
BA_ "SignalType" SG_ 193 WRSLDWhlDisTpRC "UNM";
BA_ "VNSigAllNodes" SG_ 193 WRSLDSeqNum 1;
BA_ "SignalLongName" SG_ 193 WRSLDSeqNum "Wheel Rotational Status Left Driven : Sequence Number";
BA_ "PacketOrder" SG_ 193 WRSLDSeqNum 2;
BA_ "SignalType" SG_ 193 WRSLDSeqNum "UNM";
BA_ "VNSigAllNodes" SG_ 193 WRSLDWhlDistVal 1;
BA_ "SignalLongName" SG_ 193 WRSLDWhlDistVal "Wheel Rotational Status Left Driven : Wheel Distance Validity";
BA_ "PacketOrder" SG_ 193 WRSLDWhlDistVal 4;
BA_ "SignalType" SG_ 193 WRSLDWhlDistVal "ENM";
BA_ "VNSigAllNodes" SG_ 193 WRSLDWhlRotStatRst 1;
BA_ "SignalLongName" SG_ 193 WRSLDWhlRotStatRst "Wheel Rotational Status Left Driven : Wheel Rotational Status Reset Occurred";
BA_ "PacketOrder" SG_ 193 WRSLDWhlRotStatRst 3;
BA_ "SignalType" SG_ 193 WRSLDWhlRotStatRst "BLN";
BA_ "VNSigAllNodes" SG_ 193 WRSLDWhlDistTmstm 1;
BA_ "SignalLongName" SG_ 193 WRSLDWhlDistTmstm "Wheel Rotational Status Left Driven : Wheel Distance Timestamp";
BA_ "PacketOrder" SG_ 193 WRSLDWhlDistTmstm 6;
BA_ "SignalType" SG_ 193 WRSLDWhlDistTmstm "UNM";
BA_ "VNSigAllNodes" SG_ 193 WRSLDWhlDistPlsCntr 1;
BA_ "SignalLongName" SG_ 193 WRSLDWhlDistPlsCntr "Wheel Rotational Status Left Driven : Wheel Distance Pulse Counter";
BA_ "PacketOrder" SG_ 193 WRSLDWhlDistPlsCntr 5;
BA_ "SignalType" SG_ 193 WRSLDWhlDistPlsCntr "UNM";
BA_ "VNSigAllNodes" SG_ 193 WRSRDWhlDisTpRC 1;
BA_ "SignalLongName" SG_ 193 WRSRDWhlDisTpRC "Wheel Rotational Status Right Driven : Wheel Distance Timestamp Rollover Counter";
BA_ "PacketOrder" SG_ 193 WRSRDWhlDisTpRC 1;
BA_ "SignalType" SG_ 193 WRSRDWhlDisTpRC "UNM";
BA_ "VNSigAllNodes" SG_ 193 WRSRDSeqNum 1;
BA_ "SignalLongName" SG_ 193 WRSRDSeqNum "Wheel Rotational Status Right Driven : Sequence Number";
BA_ "PacketOrder" SG_ 193 WRSRDSeqNum 2;
BA_ "SignalType" SG_ 193 WRSRDSeqNum "UNM";
BA_ "VNSigAllNodes" SG_ 193 WRSRDWhlRotStatRst 1;
BA_ "SignalLongName" SG_ 193 WRSRDWhlRotStatRst "Wheel Rotational Status Right Driven : Wheel Rotational Status Reset Occurred";
BA_ "PacketOrder" SG_ 193 WRSRDWhlRotStatRst 3;
BA_ "SignalType" SG_ 193 WRSRDWhlRotStatRst "BLN";
BA_ "VNSigAllNodes" SG_ 193 WRSRDWhlDistVal 1;
BA_ "SignalLongName" SG_ 193 WRSRDWhlDistVal "Wheel Rotational Status Right Driven : Wheel Distance Validity";
BA_ "PacketOrder" SG_ 193 WRSRDWhlDistVal 4;
BA_ "SignalType" SG_ 193 WRSRDWhlDistVal "ENM";
BA_ "VNSigAllNodes" SG_ 193 WRSRDWhlDistTmstm 1;
BA_ "SignalLongName" SG_ 193 WRSRDWhlDistTmstm "Wheel Rotational Status Right Driven : Wheel Distance Timestamp";
BA_ "PacketOrder" SG_ 193 WRSRDWhlDistTmstm 6;
BA_ "SignalType" SG_ 193 WRSRDWhlDistTmstm "UNM";
BA_ "VNSigAllNodes" SG_ 193 WRSRDWhlDistPlsCntr 1;
BA_ "SignalLongName" SG_ 193 WRSRDWhlDistPlsCntr "Wheel Rotational Status Right Driven : Wheel Distance Pulse Counter";
BA_ "PacketOrder" SG_ 193 WRSRDWhlDistPlsCntr 5;
BA_ "SignalType" SG_ 193 WRSRDWhlDistPlsCntr "UNM";
BA_ "VNSigAllNodes" SG_ 481 AuxHtrRq 1;
BA_ "SignalLongName" SG_ 481 AuxHtrRq "Auxiliary Heater Request";
BA_ "SignalType" SG_ 481 AuxHtrRq "ENM";
BA_ "VNSigAllNodes" SG_ 481 AuxHtrAtv 1;
BA_ "SignalLongName" SG_ 481 AuxHtrAtv "Auxiliary Heater Active";
BA_ "SignalType" SG_ 481 AuxHtrAtv "BLN";
BA_ "VNSigAllNodes" SG_ 481 DrvSelMdSwStaARC 1;
BA_ "SignalLongName" SG_ 481 DrvSelMdSwStaARC "Driver Selected Mode Switch State Alive Rolling Count";
BA_ "SignalType" SG_ 481 DrvSelMdSwStaARC "UNM";
BA_ "VNSigAllNodes" SG_ 481 DrvSelMdSw1Sta 1;
BA_ "SignalLongName" SG_ 481 DrvSelMdSw1Sta "Driver Selected Mode Switch 1 State";
BA_ "SignalType" SG_ 481 DrvSelMdSw1Sta "ENM";
BA_ "VNSigAllNodes" SG_ 481 CrsSpdLmtrSwStatPVal 1;
BA_ "SignalLongName" SG_ 481 CrsSpdLmtrSwStatPVal "Cruise and Speed Limiter Switch Status Protection Value";
BA_ "SignalType" SG_ 481 CrsSpdLmtrSwStatPVal "UNM";
BA_ "VNSigAllNodes" SG_ 481 CrsSpdLmtrSwStatARC 1;
BA_ "SignalLongName" SG_ 481 CrsSpdLmtrSwStatARC "Cruise and Speed Limiter Switch Status Alive Rolling Count";
BA_ "SignalType" SG_ 481 CrsSpdLmtrSwStatARC "UNM";
BA_ "VNSigAllNodes" SG_ 481 FuelMdSwActV 1;
BA_ "SignalLongName" SG_ 481 FuelMdSwActV "Fuel Mode Switch Active Validity";
BA_ "SignalType" SG_ 481 FuelMdSwActV "ENM";
BA_ "VNSigAllNodes" SG_ 481 FuelMdSwAct 1;
BA_ "SignalLongName" SG_ 481 FuelMdSwAct "Fuel Mode Switch Active";
BA_ "SignalType" SG_ 481 FuelMdSwAct "ENM";
BA_ "VNSigAllNodes" SG_ 481 CrsSpdLmtrSwStat 1;
BA_ "SignalLongName" SG_ 481 CrsSpdLmtrSwStat "Cruise and Speed Limiter Switch Status";
BA_ "SignalType" SG_ 481 CrsSpdLmtrSwStat "ENM";
BA_ "VNSigAllNodes" SG_ 481 AdptCrsGapSwAct 1;
BA_ "SignalLongName" SG_ 481 AdptCrsGapSwAct "Adaptive Cruise Control Gap Switch Activation";
BA_ "SignalType" SG_ 481 AdptCrsGapSwAct "ENM";
BA_ "GenSigSendType_signal" SG_ 481 CrsCntrlSwStCanSwAct 10;
BA_ "VNSigAllNodes" SG_ 481 CrsCntrlSwStCanSwAct 1;
BA_ "SignalLongName" SG_ 481 CrsCntrlSwStCanSwAct "Cruise Control Switch Status : Cancel Switch Active";
BA_ "PacketOrder" SG_ 481 CrsCntrlSwStCanSwAct 1;
BA_ "SignalType" SG_ 481 CrsCntrlSwStCanSwAct "BLN";
BA_ "GenSigSendType_signal" SG_ 481 CrsCntrlSwStSwDataIntgty 10;
BA_ "VNSigAllNodes" SG_ 481 CrsCntrlSwStSwDataIntgty 1;
BA_ "SignalLongName" SG_ 481 CrsCntrlSwStSwDataIntgty "Cruise Control Switch Status : Switch Data Integrity";
BA_ "PacketOrder" SG_ 481 CrsCntrlSwStSwDataIntgty 7;
BA_ "SignalType" SG_ 481 CrsCntrlSwStSwDataIntgty "ENM";
BA_ "GenSigSendType_signal" SG_ 481 CrsCntrlSwStSpdInSwAct 10;
BA_ "VNSigAllNodes" SG_ 481 CrsCntrlSwStSpdInSwAct 1;
BA_ "SignalLongName" SG_ 481 CrsCntrlSwStSpdInSwAct "Cruise Control Switch Status : Speed Increase Switch Active";
BA_ "PacketOrder" SG_ 481 CrsCntrlSwStSpdInSwAct 5;
BA_ "SignalType" SG_ 481 CrsCntrlSwStSpdInSwAct "BLN";
BA_ "GenSigSendType_signal" SG_ 481 CrsCntrlSwStSpDcSwAct 10;
BA_ "VNSigAllNodes" SG_ 481 CrsCntrlSwStSpDcSwAct 1;
BA_ "SignalLongName" SG_ 481 CrsCntrlSwStSpDcSwAct "Cruise Control Switch Status : Speed Decrease Switch Active";
BA_ "PacketOrder" SG_ 481 CrsCntrlSwStSpDcSwAct 6;
BA_ "SignalType" SG_ 481 CrsCntrlSwStSpDcSwAct "BLN";
BA_ "GenSigSendType_signal" SG_ 481 CrsCntrlSwStSetSwAct 10;
BA_ "VNSigAllNodes" SG_ 481 CrsCntrlSwStSetSwAct 1;
BA_ "SignalLongName" SG_ 481 CrsCntrlSwStSetSwAct "Cruise Control Switch Status : Set Switch Active";
BA_ "PacketOrder" SG_ 481 CrsCntrlSwStSetSwAct 4;
BA_ "SignalType" SG_ 481 CrsCntrlSwStSetSwAct "BLN";
BA_ "GenSigSendType_signal" SG_ 481 CrsCntrlSwStResSwAct 10;
BA_ "VNSigAllNodes" SG_ 481 CrsCntrlSwStResSwAct 1;
BA_ "SignalLongName" SG_ 481 CrsCntrlSwStResSwAct "Cruise Control Switch Status : Resume Switch Active";
BA_ "PacketOrder" SG_ 481 CrsCntrlSwStResSwAct 3;
BA_ "SignalType" SG_ 481 CrsCntrlSwStResSwAct "BLN";
BA_ "GenSigSendType_signal" SG_ 481 CrsCntrlSwStOnSwAct 10;
BA_ "VNSigAllNodes" SG_ 481 CrsCntrlSwStOnSwAct 1;
BA_ "SignalLongName" SG_ 481 CrsCntrlSwStOnSwAct "Cruise Control Switch Status : On Switch Active";
BA_ "PacketOrder" SG_ 481 CrsCntrlSwStOnSwAct 2;
BA_ "SignalType" SG_ 481 CrsCntrlSwStOnSwAct "BLN";
BA_ "VNSigAllNodes" SG_ 481 CrsCntrlSwStatProtValue 1;
BA_ "SignalLongName" SG_ 481 CrsCntrlSwStatProtValue "Cruise Control Switch Status Protection Value";
BA_ "SignalType" SG_ 481 CrsCntrlSwStatProtValue "UNM";
BA_ "VNSigAllNodes" SG_ 481 CrsCntrlSwStAlvRollCnt 1;
BA_ "SignalLongName" SG_ 481 CrsCntrlSwStAlvRollCnt "Cruise Control Switch Status Alive Rolling Count";
BA_ "SignalType" SG_ 481 CrsCntrlSwStAlvRollCnt "UNM";
BA_ "VNSigAllNodes" SG_ 481 CrsCntCncRq 1;
BA_ "SignalLongName" SG_ 481 CrsCntCncRq "Cruise Control Cancel Request";
BA_ "SignalType" SG_ 481 CrsCntCncRq "ENM";
BA_ "VNSigAllNodes" SG_ 761 AutoBrkFeatInhbtPV 1;
BA_ "SignalLongName" SG_ 761 AutoBrkFeatInhbtPV "Automatic Braking Feature Inhibit Protection Value";
BA_ "SignalType" SG_ 761 AutoBrkFeatInhbtPV "UNM";
BA_ "VNSigAllNodes" SG_ 761 AutoBrkFeatInhbtARC 1;
BA_ "SignalLongName" SG_ 761 AutoBrkFeatInhbtARC "Automatic Braking Feature Inhibit Alive Rolling Count";
BA_ "SignalType" SG_ 761 AutoBrkFeatInhbtARC "UNM";
BA_ "VNSigAllNodes" SG_ 761 ABFI_CollPrepSysInhbt 1;
BA_ "SignalLongName" SG_ 761 ABFI_CollPrepSysInhbt "Automatic Braking Feature Inhibit : Collision Preparation System Inhibit";
BA_ "PacketOrder" SG_ 761 ABFI_CollPrepSysInhbt 2;
BA_ "SignalType" SG_ 761 ABFI_CollPrepSysInhbt "BLN";
BA_ "VNSigAllNodes" SG_ 761 ABFI_RrVirtlBmprInh 1;
BA_ "SignalLongName" SG_ 761 ABFI_RrVirtlBmprInh "Automatic Braking Feature Inhibit : Rear Virtual Bumper Inhibit";
BA_ "PacketOrder" SG_ 761 ABFI_RrVirtlBmprInh 1;
BA_ "SignalType" SG_ 761 ABFI_RrVirtlBmprInh "BLN";
BA_ "VNSigAllNodes" SG_ 761 BrkPdlDrvApplPresV 1;
BA_ "SignalLongName" SG_ 761 BrkPdlDrvApplPresV "Brake Pedal Driver Applied Pressure Validity";
BA_ "SignalType" SG_ 761 BrkPdlDrvApplPresV "ENM";
BA_ "VNSigAllNodes" SG_ 761 BrkPdlDrvApplPres 1;
BA_ "SignalLongName" SG_ 761 BrkPdlDrvApplPres "Brake Pedal Driver Applied Pressure";
BA_ "SignalType" SG_ 761 BrkPdlDrvApplPres "UNM";
BA_ "VNSigAllNodes" SG_ 761 WhlSpdSnsgDTCIndex 1;
BA_ "SignalLongName" SG_ 761 WhlSpdSnsgDTCIndex "Wheel Speed Sensing Legislated Diagnostic Status : Diagnostic Trouble Code Index";
BA_ "PacketOrder" SG_ 761 WhlSpdSnsgDTCIndex 1;
BA_ "SignalType" SG_ 761 WhlSpdSnsgDTCIndex "UNM";
BA_ "VNSigAllNodes" SG_ 761 WhlSpdSnsgDTCStat 1;
BA_ "SignalLongName" SG_ 761 WhlSpdSnsgDTCStat "Wheel Speed Sensing Legislated Diagnostic Status : Diagnostic Trouble Code Status";
BA_ "PacketOrder" SG_ 761 WhlSpdSnsgDTCStat 2;
BA_ "SignalType" SG_ 761 WhlSpdSnsgDTCStat "ENM";
BA_ "VNSigAllNodes" SG_ 761 SprTireSt 1;
BA_ "SignalLongName" SG_ 761 SprTireSt "Spare Tire Status";
BA_ "SignalType" SG_ 761 SprTireSt "ENM";
BA_ "VNSigAllNodes" SG_ 761 ChsBrkgLoad 1;
BA_ "SignalLongName" SG_ 761 ChsBrkgLoad "Chassis Braking Load";
BA_ "SignalType" SG_ 761 ChsBrkgLoad "UNM";
BA_ "VNSigAllNodes" SG_ 761 BrkTemp 1;
BA_ "SignalLongName" SG_ 761 BrkTemp "Brake Temperature";
BA_ "SignalType" SG_ 761 BrkTemp "UNM";
BA_ "VNSigAllNodes" SG_ 489 DrvIndpntBrkAppAct 1;
BA_ "SignalLongName" SG_ 489 DrvIndpntBrkAppAct "Driver Independent Brake Apply Active";
BA_ "SignalType" SG_ 489 DrvIndpntBrkAppAct "BLN";
BA_ "VNSigAllNodes" SG_ 489 WhlSlpSt 1;
BA_ "SignalLongName" SG_ 489 WhlSlpSt "Wheel Slip Status";
BA_ "SignalType" SG_ 489 WhlSlpSt "ENM";
BA_ "VNSigAllNodes" SG_ 489 BSTGRReqdGear 1;
BA_ "SignalLongName" SG_ 489 BSTGRReqdGear "Brake System Transmission Gear Request : Requested Gear";
BA_ "PacketOrder" SG_ 489 BSTGRReqdGear 2;
BA_ "SignalType" SG_ 489 BSTGRReqdGear "ENM";
BA_ "VNSigAllNodes" SG_ 489 BSTGRReqType 1;
BA_ "SignalLongName" SG_ 489 BSTGRReqType "Brake System Transmission Gear Request : Request Type";
BA_ "PacketOrder" SG_ 489 BSTGRReqType 1;
BA_ "SignalType" SG_ 489 BSTGRReqType "ENM";
BA_ "VNSigAllNodes" SG_ 489 VehDynOvrUndrStr 1;
BA_ "SignalLongName" SG_ 489 VehDynOvrUndrStr "Vehicle Dynamics Over Under Steer";
BA_ "SignalType" SG_ 489 VehDynOvrUndrStr "SNM";
BA_ "VNSigAllNodes" SG_ 489 VSELatAccV 1;
BA_ "SignalLongName" SG_ 489 VSELatAccV "Vehicle Stability Enhancement Lateral Acceleration Validity";
BA_ "SignalType" SG_ 489 VSELatAccV "ENM";
BA_ "VNSigAllNodes" SG_ 489 VSELatAcc 1;
BA_ "SignalLongName" SG_ 489 VSELatAcc "Vehicle Stability Enhancement Lateral Acceleration";
BA_ "SignalType" SG_ 489 VSELatAcc "SNM";
BA_ "VNSigAllNodes" SG_ 489 VSEAct 1;
BA_ "SignalLongName" SG_ 489 VSEAct "Vehicle Stability Enhancement System Active";
BA_ "SignalType" SG_ 489 VSEAct "BLN";
BA_ "VNSigAllNodes" SG_ 489 VhDynCntlSysSt 1;
BA_ "SignalLongName" SG_ 489 VhDynCntlSysSt "Vehicle Dynamics Control System Status";
BA_ "SignalType" SG_ 489 VhDynCntlSysSt "ENM";
BA_ "VNSigAllNodes" SG_ 489 VehDynYawRateV 1;
BA_ "SignalLongName" SG_ 489 VehDynYawRateV "Vehicle Dynamics Yaw Rate Validity";
BA_ "SignalType" SG_ 489 VehDynYawRateV "ENM";
BA_ "VNSigAllNodes" SG_ 489 VehDynYawRate 1;
BA_ "SignalLongName" SG_ 489 VehDynYawRate "Vehicle Dynamics Yaw Rate";
BA_ "SignalType" SG_ 489 VehDynYawRate "SNM";
BA_ "VNSigAllNodes" SG_ 489 TrnsBrkSysCltchRelRqd 1;
BA_ "SignalLongName" SG_ 489 TrnsBrkSysCltchRelRqd "Transmission Brake System Clutch Release Requested";
BA_ "SignalType" SG_ 489 TrnsBrkSysCltchRelRqd "BLN";
BA_ "VNSigAllNodes" SG_ 489 TracCntrlSysDrIntnt 1;
BA_ "SignalLongName" SG_ 489 TracCntrlSysDrIntnt "Traction Control System Driver Intent";
BA_ "SignalType" SG_ 489 TracCntrlSysDrIntnt "ENM";
BA_ "VNSigAllNodes" SG_ 489 VehDynOvrUndrStrV 1;
BA_ "SignalLongName" SG_ 489 VehDynOvrUndrStrV "Vehicle Dynamics Over Under Steer Validity";
BA_ "SignalType" SG_ 489 VehDynOvrUndrStrV "ENM";
BA_ "VNSigAllNodes" SG_ 489 TCSysEnbld 1;
BA_ "SignalLongName" SG_ 489 TCSysEnbld "Traction Control System Enabled";
BA_ "SignalType" SG_ 489 TCSysEnbld "BLN";
BA_ "VNSigAllNodes" SG_ 489 TCSysAtv 1;
BA_ "SignalLongName" SG_ 489 TCSysAtv "Traction Control System Active";
BA_ "SignalType" SG_ 489 TCSysAtv "BLN";
BA_ "VNSigAllNodes" SG_ 489 BrkPdlDrvAppPrsDetcdV 1;
BA_ "SignalLongName" SG_ 489 BrkPdlDrvAppPrsDetcdV "Brake Pedal Driver Applied Pressure Detected Validity";
BA_ "SignalType" SG_ 489 BrkPdlDrvAppPrsDetcdV "ENM";
BA_ "VNSigAllNodes" SG_ 489 BrkPdlDrvAppPrsDetcd 1;
BA_ "GenSigStartValue" SG_ 489 BrkPdlDrvAppPrsDetcd 1;
BA_ "SignalLongName" SG_ 489 BrkPdlDrvAppPrsDetcd "Brake Pedal Driver Applied Pressure Detected";
BA_ "SignalType" SG_ 489 BrkPdlDrvAppPrsDetcd "BLN";
BA_ "VNSigAllNodes" SG_ 489 ACCBrkngAct 1;
BA_ "SignalLongName" SG_ 489 ACCBrkngAct "Adaptive Cruise Control Braking Active";
BA_ "SignalType" SG_ 489 ACCBrkngAct "BLN";
BA_ "VNSigAllNodes" SG_ 489 ABSFld 1;
BA_ "SignalLongName" SG_ 489 ABSFld "Antilock Brake System Failed";
BA_ "SignalType" SG_ 489 ABSFld "BLN";
BA_ "VNSigAllNodes" SG_ 489 ABSAtv 1;
BA_ "SignalLongName" SG_ 489 ABSAtv "Antilock Brake System Active";
BA_ "SignalType" SG_ 489 ABSAtv "BLN";
BA_ "VNSigAllNodes" SG_ 381 EBDFailed 1;
BA_ "SignalLongName" SG_ 381 EBDFailed "Electronic Brake Distribution Failed";
BA_ "SignalType" SG_ 381 EBDFailed "BLN";
BA_ "VNSigAllNodes" SG_ 381 StWhAnVDA 1;
BA_ "GenSigStartValue" SG_ 381 StWhAnVDA 1;
BA_ "SignalLongName" SG_ 381 StWhAnVDA "Steering Wheel Angle Virtual Device Availability";
BA_ "SignalType" SG_ 381 StWhAnVDA "ENM";
BA_ "VNSigAllNodes" SG_ 381 TirePrsLowIO 1;
BA_ "SignalLongName" SG_ 381 TirePrsLowIO "Tire Pressure Low Indication On";
BA_ "SignalType" SG_ 381 TirePrsLowIO "BLN";
BA_ "VNSigAllNodes" SG_ 381 VaccBoostFailure 1;
BA_ "SignalLongName" SG_ 381 VaccBoostFailure "Vaccum Boost Failure";
BA_ "SignalType" SG_ 381 VaccBoostFailure "BLN";
BA_ "VNSigAllNodes" SG_ 381 VSESysPrs 1;
BA_ "SignalLongName" SG_ 381 VSESysPrs "Vehicle Stability Enhancement System Present";
BA_ "SignalType" SG_ 381 VSESysPrs "BLN";
BA_ "VNSigAllNodes" SG_ 381 HalfSysFail 1;
BA_ "SignalLongName" SG_ 381 HalfSysFail "Half System Failure";
BA_ "SignalType" SG_ 381 HalfSysFail "BLN";
BA_ "VNSigAllNodes" SG_ 381 ActVehAccel 1;
BA_ "SignalLongName" SG_ 381 ActVehAccel "Actual Vehicle Acceleration";
BA_ "SignalType" SG_ 381 ActVehAccel "SNM";
BA_ "VNSigAllNodes" SG_ 381 ActVehAccelV 1;
BA_ "SignalLongName" SG_ 381 ActVehAccelV "Actual Vehicle Acceleration Validity";
BA_ "SignalType" SG_ 381 ActVehAccelV "ENM";
BA_ "VNSigAllNodes" SG_ 381 BksOvht 1;
BA_ "SignalLongName" SG_ 381 BksOvht "Brakes Overheated";
BA_ "SignalType" SG_ 381 BksOvht "BLN";
BA_ "VNSigAllNodes" SG_ 381 TCSysPr 1;
BA_ "SignalLongName" SG_ 381 TCSysPr "Traction Control System Present";
BA_ "SignalType" SG_ 381 TCSysPr "BLN";
BA_ "VNSigAllNodes" SG_ 381 ABSPr 1;
BA_ "SignalLongName" SG_ 381 ABSPr "Antilock Brake System Present";
BA_ "SignalType" SG_ 381 ABSPr "BLN";
BA_ "VNSigAllNodes" SG_ 381 TreInfMonSysRstPrfmd 1;
BA_ "SignalLongName" SG_ 381 TreInfMonSysRstPrfmd "Tire Inflation Monitoring System Reset Performed";
BA_ "SignalType" SG_ 381 TreInfMonSysRstPrfmd "BLN";
BA_ "VNSigAllNodes" SG_ 381 ABSIO 1;
BA_ "SignalLongName" SG_ 381 ABSIO "Antilock Brake System Indication On";
BA_ "SignalType" SG_ 381 ABSIO "BLN";
BA_ "VNSigAllNodes" SG_ 381 BrkPadWrnIO 1;
BA_ "SignalLongName" SG_ 381 BrkPadWrnIO "Brake Pad Worn Indication On";
BA_ "SignalType" SG_ 381 BrkPadWrnIO "BLN";
BA_ "VNSigAllNodes" SG_ 381 VehStabEnhmntMd 1;
BA_ "SignalLongName" SG_ 381 VehStabEnhmntMd "Vehicle Stability Enhancement Mode";
BA_ "SignalType" SG_ 381 VehStabEnhmntMd "ENM";
BA_ "VNSigAllNodes" SG_ 381 VehStabEnhmntStat 1;
BA_ "SignalLongName" SG_ 381 VehStabEnhmntStat "Vehicle Stability Enhancement Status";
BA_ "SignalType" SG_ 381 VehStabEnhmntStat "ENM";
BA_ "VNSigAllNodes" SG_ 381 TCSysOpMd 1;
BA_ "SignalLongName" SG_ 381 TCSysOpMd "Traction Control System Operating Mode";
BA_ "SignalType" SG_ 381 TCSysOpMd "ENM";
BA_ "VNSigAllNodes" SG_ 381 TCSysOpStat 1;
BA_ "SignalLongName" SG_ 381 TCSysOpStat "Traction Control System Operating Status";
BA_ "SignalType" SG_ 381 TCSysOpStat "ENM";
BA_ "VNSigAllNodes" SG_ 381 BrkSysVTopSpdLimVal 1;
BA_ "GenSigStartValue" SG_ 381 BrkSysVTopSpdLimVal 255;
BA_ "SignalLongName" SG_ 381 BrkSysVTopSpdLimVal "Braking System Vehicle Top Speed Limit Value";
BA_ "SignalType" SG_ 381 BrkSysVTopSpdLimVal "UNM";
BA_ "VNSigAllNodes" SG_ 381 BrkSysRedBrkTlltlReq 1;
BA_ "SignalLongName" SG_ 381 BrkSysRedBrkTlltlReq "Brake System Red Brake Telltale Request";
BA_ "SignalType" SG_ 381 BrkSysRedBrkTlltlReq "BLN";
BA_ "VNSigAllNodes" SG_ 381 BrkSysBrkLtsReqd 1;
BA_ "SignalLongName" SG_ 381 BrkSysBrkLtsReqd "Brake System Brake Lights Requested";
BA_ "SignalType" SG_ 381 BrkSysBrkLtsReqd "BLN";
BA_ "GenSigSendType_signal" SG_ 241 BrkPedTrvlAchvdV 10;
BA_ "VNSigAllNodes" SG_ 241 BrkPedTrvlAchvdV 1;
BA_ "SignalLongName" SG_ 241 BrkPedTrvlAchvdV "Brake Pedal Initial Travel Achieved Status : Brake Pedal Initial Travel Achieved Validity";
BA_ "PacketOrder" SG_ 241 BrkPedTrvlAchvdV 2;
BA_ "SignalType" SG_ 241 BrkPedTrvlAchvdV "ENM";
BA_ "GenSigSendType_signal" SG_ 241 BrkPedTrvlAchvd 10;
BA_ "VNSigAllNodes" SG_ 241 BrkPedTrvlAchvd 1;
BA_ "SignalLongName" SG_ 241 BrkPedTrvlAchvd "Brake Pedal Initial Travel Achieved Status : Brake Pedal Initial Travel Achieved";
BA_ "PacketOrder" SG_ 241 BrkPedTrvlAchvd 1;
BA_ "SignalType" SG_ 241 BrkPedTrvlAchvd "BLN";
BA_ "VNSigAllNodes" SG_ 241 BrkAppSnsrHmPosLrnd 1;
BA_ "SignalLongName" SG_ 241 BrkAppSnsrHmPosLrnd "Brake Apply Sensor Home Position Learned";
BA_ "SignalType" SG_ 241 BrkAppSnsrHmPosLrnd "BLN";
BA_ "VNSigAllNodes" SG_ 241 BrkPdlPosGrad 1;
BA_ "SignalLongName" SG_ 241 BrkPdlPosGrad "Brake Pedal Position Gradient";
BA_ "SignalType" SG_ 241 BrkPdlPosGrad "SNM";
BA_ "VNSigAllNodes" SG_ 241 BrkPdlPos 1;
BA_ "SignalLongName" SG_ 241 BrkPdlPos "Brake Pedal Position";
BA_ "SignalType" SG_ 241 BrkPdlPos "UNM";
BA_ "VNSigAllNodes" SG_ 241 BrkPedPosAlvRolngCnt 1;
BA_ "SignalLongName" SG_ 241 BrkPedPosAlvRolngCnt "Brake Pedal Position Alive Rolling Count";
BA_ "SignalType" SG_ 241 BrkPedPosAlvRolngCnt "UNM";
BA_ "VNSigAllNodes" SG_ 241 BrkPdlModTrvlV 1;
BA_ "SignalLongName" SG_ 241 BrkPdlModTrvlV "Brake Pedal Moderate Travel Achieved Validity";
BA_ "SignalType" SG_ 241 BrkPdlModTrvlV "ENM";
BA_ "VNSigAllNodes" SG_ 241 BrkPdlModTrvl 1;
BA_ "SignalLongName" SG_ 241 BrkPdlModTrvl "Brake Pedal Moderate Travel Achieved";
BA_ "SignalType" SG_ 241 BrkPdlModTrvl "BLN";
BA_ "VNSigAllNodes" SG_ 241 BrkPdlInTrvPrt 1;
BA_ "SignalLongName" SG_ 241 BrkPdlInTrvPrt "Brake Pedal Initial Travel Achieved Protection";
BA_ "SignalType" SG_ 241 BrkPdlInTrvPrt "UNM";
BA_ "VNSigAllNodes" SG_ 1356 DgnInf_HS541 1;
BA_ "SignalLongName" SG_ 1356 DgnInf_HS541 "Diagnostic Information HS541";
BA_ "SignalType" SG_ 1356 DgnInf_HS541 "UNM";
BA_ "VNSigSLHSSharedDiagnostic" SG_ 1356 DgnInf_HS541 1;
BA_ "GenSigSendType_signal" SG_ 500 DrvSelMd1ReqDnd 10;
BA_ "VNSigAllNodes" SG_ 500 DrvSelMd1ReqDnd 1;
BA_ "SignalLongName" SG_ 500 DrvSelMd1ReqDnd "Driver Selected Mode 1 Request Denied";
BA_ "SignalType" SG_ 500 DrvSelMd1ReqDnd "BLN";
BA_ "GenSigSendType_signal" SG_ 500 DrvSelMd1Stat 10;
BA_ "VNSigAllNodes" SG_ 500 DrvSelMd1Stat 1;
BA_ "SignalLongName" SG_ 500 DrvSelMd1Stat "Driver Selected Mode 1 Status";
BA_ "SignalType" SG_ 500 DrvSelMd1Stat "ENM";
BA_ "VNSigAllNodes" SG_ 407 TrnsOvrallActTorqRatioV 1;
BA_ "SignalLongName" SG_ 407 TrnsOvrallActTorqRatioV "Transmission Overall Actual Torque Ratio Validity";
BA_ "SignalType" SG_ 407 TrnsOvrallActTorqRatioV "ENM";
BA_ "VNSigAllNodes" SG_ 407 TrnsOvrallActTorqRatio 1;
BA_ "SignalLongName" SG_ 407 TrnsOvrallActTorqRatio "Transmission Overall Actual Torque Ratio";
BA_ "SignalType" SG_ 407 TrnsOvrallActTorqRatio "SNM";
BA_ "VNSigAllNodes" SG_ 1221 PFFanSpdPrcntRq 1;
BA_ "SignalLongName" SG_ 1221 PFFanSpdPrcntRq "Platform Fan Speed Percent Request";
BA_ "SignalType" SG_ 1221 PFFanSpdPrcntRq "UNM";
BA_ "VNSigAllNodes" SG_ 738 EngTrnsRngDspRvAct 1;
BA_ "SignalLongName" SG_ 738 EngTrnsRngDspRvAct "Engine Transmission Range Display Reverse Active";
BA_ "SignalType" SG_ 738 EngTrnsRngDspRvAct "BLN";
BA_ "VNSigAllNodes" SG_ 738 EngTrnsRngDspNtrlAct 1;
BA_ "SignalLongName" SG_ 738 EngTrnsRngDspNtrlAct "Engine Transmission Range Display Neutral Active";
BA_ "SignalType" SG_ 738 EngTrnsRngDspNtrlAct "BLN";
BA_ "VNSigAllNodes" SG_ 738 EngTrnsRngDspFwdAc 1;
BA_ "SignalLongName" SG_ 738 EngTrnsRngDspFwdAc "Engine Transmission Range Display Forward Active";
BA_ "SignalType" SG_ 738 EngTrnsRngDspFwdAc "BLN";
BA_ "VNSigAllNodes" SG_ 738 EngTrnsRngDspARC 1;
BA_ "SignalLongName" SG_ 738 EngTrnsRngDspARC "Engine Transmission Range Display Alive Rolling Count Extended";
BA_ "SignalType" SG_ 738 EngTrnsRngDspARC "UNM";
BA_ "VNSigAllNodes" SG_ 738 EngTrnsRngDspPrkAct 1;
BA_ "SignalLongName" SG_ 738 EngTrnsRngDspPrkAct "Engine Transmission Range Display Park Active";
BA_ "SignalType" SG_ 738 EngTrnsRngDspPrkAct "BLN";
BA_ "VNSigAllNodes" SG_ 738 EngShftrMlfIO 1;
BA_ "SignalLongName" SG_ 738 EngShftrMlfIO "Engine Shifter Malfunction Indication On";
BA_ "SignalType" SG_ 738 EngShftrMlfIO "BLN";
BA_ "VNSigAllNodes" SG_ 738 EngRedPwrSecEvntIO 1;
BA_ "SignalLongName" SG_ 738 EngRedPwrSecEvntIO "Engine Reduced Power Security Event Indication On";
BA_ "SignalType" SG_ 738 EngRedPwrSecEvntIO "BLN";
BA_ "VNSigAllNodes" SG_ 738 EngShtdwnSecEvtIO 1;
BA_ "SignalLongName" SG_ 738 EngShtdwnSecEvtIO "Engine Shutdown Security Event Indication On";
BA_ "SignalType" SG_ 738 EngShtdwnSecEvtIO "BLN";
BA_ "VNSigAllNodes" SG_ 738 EngVehPrkWhnStpIO 1;
BA_ "SignalLongName" SG_ 738 EngVehPrkWhnStpIO "Engine Vehicle Will Park When Stopped Indication On";
BA_ "SignalType" SG_ 738 EngVehPrkWhnStpIO "BLN";
BA_ "VNSigAllNodes" SG_ 738 EngGnrlTrnsMlfIO 1;
BA_ "SignalLongName" SG_ 738 EngGnrlTrnsMlfIO "Engine General Transmission Malfunction Indication On";
BA_ "SignalType" SG_ 738 EngGnrlTrnsMlfIO "BLN";
BA_ "VNSigAllNodes" SG_ 431 TrnsTrqCnvCltCmdMdF 1;
BA_ "SignalLongName" SG_ 431 TrnsTrqCnvCltCmdMdF "Transmission Torque Converter Clutch Commanded Mode Failure";
BA_ "SignalType" SG_ 431 TrnsTrqCnvCltCmdMdF "BLN";
BA_ "VNSigAllNodes" SG_ 431 AutoTransGrSftDirectFl 1;
BA_ "SignalLongName" SG_ 431 AutoTransGrSftDirectFl "Automatic Transmission Gear Shift Direction Failure";
BA_ "SignalType" SG_ 431 AutoTransGrSftDirectFl "BLN";
BA_ "VNSigAllNodes" SG_ 431 AutoTransGrSftDirect 1;
BA_ "SignalLongName" SG_ 431 AutoTransGrSftDirect "Automatic Transmission Gear Shift Direction";
BA_ "SignalType" SG_ 431 AutoTransGrSftDirect "ENM";
BA_ "VNSigAllNodes" SG_ 431 TrnsTrqCnvCltCmndMd 1;
BA_ "GenSigStartValue" SG_ 431 TrnsTrqCnvCltCmndMd 7;
BA_ "SignalLongName" SG_ 431 TrnsTrqCnvCltCmndMd "Transmission Torque Converter Clutch Commanded Mode";
BA_ "SignalType" SG_ 431 TrnsTrqCnvCltCmndMd "ENM";
BA_ "VNSigAllNodes" SG_ 431 TrnsInpCltchStat 1;
BA_ "SignalLongName" SG_ 431 TrnsInpCltchStat "Transmission Input Clutch Status";
BA_ "SignalType" SG_ 431 TrnsInpCltchStat "ENM";
BA_ "VNSigAllNodes" SG_ 431 TrnsAntcptdCrpTrqRRnV 1;
BA_ "SignalLongName" SG_ 431 TrnsAntcptdCrpTrqRRnV "Transmission Anticipated Creep Torque Reduced Range Validity";
BA_ "SignalType" SG_ 431 TrnsAntcptdCrpTrqRRnV "ENM";
BA_ "VNSigAllNodes" SG_ 431 TrnsAntcptdCrpTrqRRn 1;
BA_ "SignalLongName" SG_ 431 TrnsAntcptdCrpTrqRRn "Transmission Anticipated Creep Torque Reduced Range";
BA_ "SignalType" SG_ 431 TrnsAntcptdCrpTrqRRn "UNM";
BA_ "VNSigAllNodes" SG_ 431 TrnCltAdpAtv 1;
BA_ "SignalLongName" SG_ 431 TrnCltAdpAtv "Transmission Clutch Adaptation Active";
BA_ "SignalType" SG_ 431 TrnCltAdpAtv "BLN";
BA_ "VNSigAllNodes" SG_ 431 TransCrnkPermsnStat 1;
BA_ "SignalLongName" SG_ 431 TransCrnkPermsnStat "Transmission Crank Permission Status";
BA_ "SignalType" SG_ 431 TransCrnkPermsnStat "ENM";
BA_ "VNSigAllNodes" SG_ 431 WrmUpShftPtrn 1;
BA_ "SignalLongName" SG_ 431 WrmUpShftPtrn "Warm Up Shift Pattern Status";
BA_ "SignalType" SG_ 431 WrmUpShftPtrn "ENM";
BA_ "VNSigAllNodes" SG_ 1345 DgnInf_HS541 1;
BA_ "SignalLongName" SG_ 1345 DgnInf_HS541 "Diagnostic Information HS541";
BA_ "SignalType" SG_ 1345 DgnInf_HS541 "UNM";
BA_ "VNSigSLHSSharedDiagnostic" SG_ 1345 DgnInf_HS541 1;
BA_ "VNSigAllNodes" SG_ 309 StBltTgtCSRq 1;
BA_ "SignalLongName" SG_ 309 StBltTgtCSRq "Seat Belt Tightening Customize Setting Request";
BA_ "SignalType" SG_ 309 StBltTgtCSRq "ENM";
BA_ "VNSigAllNodes" SG_ 309 ColPrSysCustReq 1;
BA_ "SignalLongName" SG_ 309 ColPrSysCustReq "Collision Preparation System Customization Setting Request";
BA_ "SignalType" SG_ 309 ColPrSysCustReq "ENM";
BA_ "VNSigAllNodes" SG_ 309 SecV 1;
BA_ "SignalLongName" SG_ 309 SecV "Seconds Validity";
BA_ "SignalType" SG_ 309 SecV "ENM";
BA_ "VNSigAllNodes" SG_ 309 Sec 1;
BA_ "SignalLongName" SG_ 309 Sec "Seconds";
BA_ "SignalType" SG_ 309 Sec "UNM";
BA_ "VNSigAllNodes" SG_ 309 CldrYr_154 1;
BA_ "SignalLongName" SG_ 309 CldrYr_154 "Calendar Year";
BA_ "SignalType" SG_ 309 CldrYr_154 "UNM";
BA_ "VNSigAllNodes" SG_ 309 CldrYr 1;
BA_ "SignalLongName" SG_ 309 CldrYr "Calendar Year";
BA_ "SignalType" SG_ 309 CldrYr "UNM";
BA_ "VNSigAllNodes" SG_ 309 CldrMth_154 1;
BA_ "SignalLongName" SG_ 309 CldrMth_154 "Calendar Month";
BA_ "SignalType" SG_ 309 CldrMth_154 "ENM";
BA_ "VNSigAllNodes" SG_ 309 CldrMth 1;
BA_ "SignalLongName" SG_ 309 CldrMth "Calendar Month";
BA_ "SignalType" SG_ 309 CldrMth "ENM";
BA_ "VNSigAllNodes" SG_ 309 CldrDay_154 1;
BA_ "SignalLongName" SG_ 309 CldrDay_154 "Calendar Day";
BA_ "SignalType" SG_ 309 CldrDay_154 "UNM";
BA_ "VNSigAllNodes" SG_ 309 CldrDay 1;
BA_ "SignalLongName" SG_ 309 CldrDay "Calendar Day";
BA_ "SignalType" SG_ 309 CldrDay "UNM";
BA_ "VNSigAllNodes" SG_ 309 AutoHiBmVDA 1;
BA_ "GenSigStartValue" SG_ 309 AutoHiBmVDA 1;
BA_ "SignalLongName" SG_ 309 AutoHiBmVDA "Automatic High Beam Virtual Device Availability";
BA_ "SignalType" SG_ 309 AutoHiBmVDA "ENM";
BA_ "VNSigAllNodes" SG_ 309 CtLghtDet 1;
BA_ "SignalLongName" SG_ 309 CtLghtDet "City Light Detected";
BA_ "SignalType" SG_ 309 CtLghtDet "BLN";
BA_ "VNSigAllNodes" SG_ 309 RrClosVDA 1;
BA_ "GenSigStartValue" SG_ 309 RrClosVDA 1;
BA_ "SignalLongName" SG_ 309 RrClosVDA "Rear Closure Virtual Device Availability";
BA_ "SignalType" SG_ 309 RrClosVDA "ENM";
BA_ "VNSigAllNodes" SG_ 309 TCSysDisSwAtv 1;
BA_ "SignalLongName" SG_ 309 TCSysDisSwAtv "Traction Control System Disable Switch Active";
BA_ "SignalType" SG_ 309 TCSysDisSwAtv "BLN";
BA_ "VNSigAllNodes" SG_ 309 VehMovState 1;
BA_ "SignalLongName" SG_ 309 VehMovState "Vehicle Movement State";
BA_ "SignalType" SG_ 309 VehMovState "ENM";
BA_ "VNSigAllNodes" SG_ 309 TCSysDisSwAtvV 1;
BA_ "SignalLongName" SG_ 309 TCSysDisSwAtvV "Traction Control System Disable Switch Active Validity";
BA_ "SignalType" SG_ 309 TCSysDisSwAtvV "ENM";
BA_ "VNSigAllNodes" SG_ 309 HillDesCtrlMdSwActV 1;
BA_ "SignalLongName" SG_ 309 HillDesCtrlMdSwActV "Hill Descent Control Mode Switch Active Validity";
BA_ "SignalType" SG_ 309 HillDesCtrlMdSwActV "ENM";
BA_ "VNSigAllNodes" SG_ 309 WSWshSwAtv 1;
BA_ "SignalLongName" SG_ 309 WSWshSwAtv "Windshield Washer Switch Active";
BA_ "SignalType" SG_ 309 WSWshSwAtv "BLN";
BA_ "VNSigAllNodes" SG_ 309 HillDesCtrlMdSwAct 1;
BA_ "SignalLongName" SG_ 309 HillDesCtrlMdSwAct "Hill Descent Control Mode Switch Active";
BA_ "SignalType" SG_ 309 HillDesCtrlMdSwAct "BLN";
BA_ "VNSigAllNodes" SG_ 309 RrClosAjarSwAct 1;
BA_ "SignalLongName" SG_ 309 RrClosAjarSwAct "Rear Closure Ajar Switch Active";
BA_ "SignalType" SG_ 309 RrClosAjarSwAct "BLN";
BA_ "VNSigAllNodes" SG_ 309 WSWprAct 1;
BA_ "SignalLongName" SG_ 309 WSWprAct "Windshield Wiper Active";
BA_ "SignalType" SG_ 309 WSWprAct "BLN";
BA_ "VNSigAllNodes" SG_ 532 AutoBrkngAvlbl 1;
BA_ "SignalLongName" SG_ 532 AutoBrkngAvlbl "Automatic Braking Available";
BA_ "SignalType" SG_ 532 AutoBrkngAvlbl "BLN";
BA_ "VNSigAllNodes" SG_ 532 ABSAutnmsBrkReqPV 1;
BA_ "SignalLongName" SG_ 532 ABSAutnmsBrkReqPV "Antilock Brake System Autonomous Braking Request Protection Value";
BA_ "SignalType" SG_ 532 ABSAutnmsBrkReqPV "UNM";
BA_ "VNSigAllNodes" SG_ 532 ABSAutnmsBrkReqARC 1;
BA_ "SignalLongName" SG_ 532 ABSAutnmsBrkReqARC "Antilock Brake System Autonomous Braking Request Alive Rolling Count";
BA_ "SignalType" SG_ 532 ABSAutnmsBrkReqARC "UNM";
BA_ "VNSigAllNodes" SG_ 532 ABSAutnmsBrkReq 1;
BA_ "SignalLongName" SG_ 532 ABSAutnmsBrkReq "Antilock Brake System Autonomous Braking Request";
BA_ "SignalType" SG_ 532 ABSAutnmsBrkReq "BLN";
BA_ "VNSigAllNodes" SG_ 532 HlStrAssActIO 1;
BA_ "SignalLongName" SG_ 532 HlStrAssActIO "Hill Start Assist Active Indication On";
BA_ "SignalType" SG_ 532 HlStrAssActIO "BLN";
BA_ "VNSigAllNodes" SG_ 532 BrkSysAutBrkFld 1;
BA_ "SignalLongName" SG_ 532 BrkSysAutBrkFld "Brake System Automatic Braking Failed";
BA_ "SignalType" SG_ 532 BrkSysAutBrkFld "BLN";
BA_ "VNSigAllNodes" SG_ 532 IntBrkAssPreFilReq 1;
BA_ "SignalLongName" SG_ 532 IntBrkAssPreFilReq "Inteligent Brake Assist Pre-Fil Request";
BA_ "SignalType" SG_ 532 IntBrkAssPreFilReq "BLN";
BA_ "VNSigAllNodes" SG_ 532 BrkSysMalFuncIndOn 1;
BA_ "SignalLongName" SG_ 532 BrkSysMalFuncIndOn "Brake System Malfunction Indication On";
BA_ "SignalType" SG_ 532 BrkSysMalFuncIndOn "BLN";
BA_ "VNSigAllNodes" SG_ 532 BrkPdDrvAPrsStaPVal 1;
BA_ "SignalLongName" SG_ 532 BrkPdDrvAPrsStaPVal "Brake Pedal Driver Applied Pressure Status Protection Value";
BA_ "SignalType" SG_ 532 BrkPdDrvAPrsStaPVal "UNM";
BA_ "VNSigAllNodes" SG_ 532 BPDAPS_BkPDrvApPV 1;
BA_ "SignalLongName" SG_ 532 BPDAPS_BkPDrvApPV "Brake Pedal Driver Applied Pressure Status : Brake Pedal Driver Applied Pressure Validity";
BA_ "PacketOrder" SG_ 532 BPDAPS_BkPDrvApPV 2;
BA_ "SignalType" SG_ 532 BPDAPS_BkPDrvApPV "ENM";
BA_ "VNSigAllNodes" SG_ 532 BPDAPS_BkPDrvApP 1;
BA_ "SignalLongName" SG_ 532 BPDAPS_BkPDrvApP "Brake Pedal Driver Applied Pressure Status : Brake Pedal Driver Applied Pressure";
BA_ "PacketOrder" SG_ 532 BPDAPS_BkPDrvApP 1;
BA_ "SignalType" SG_ 532 BPDAPS_BkPDrvApP "UNM";
BA_ "VNSigAllNodes" SG_ 532 BrkPdDrvAppPrsAlRC 1;
BA_ "SignalLongName" SG_ 532 BrkPdDrvAppPrsAlRC "Brake Pedal Driver Applied Pressure Alive Rolling Count";
BA_ "SignalType" SG_ 532 BrkPdDrvAppPrsAlRC "UNM";
BA_ "VNSigAllNodes" SG_ 532 BrkFldLvlLwV 1;
BA_ "SignalLongName" SG_ 532 BrkFldLvlLwV "Brake Fluid Level Low Validity";
BA_ "SignalType" SG_ 532 BrkFldLvlLwV "ENM";
BA_ "VNSigAllNodes" SG_ 532 AutoBrkngAct 1;
BA_ "SignalLongName" SG_ 532 AutoBrkngAct "Automatic Braking Active";
BA_ "SignalType" SG_ 532 AutoBrkngAct "BLN";
BA_ "VNSigAllNodes" SG_ 532 BrkFldLvlLw 1;
BA_ "SignalLongName" SG_ 532 BrkFldLvlLw "Brake Fluid Level Low";
BA_ "SignalType" SG_ 532 BrkFldLvlLw "BLN";
BA_ "VNSigAllNodes" SG_ 451 AuxHtrAlwd 1;
BA_ "SignalLongName" SG_ 451 AuxHtrAlwd "Auxiliary Heater Allowed";
BA_ "SignalType" SG_ 451 AuxHtrAlwd "BLN";
BA_ "VNSigAllNodes" SG_ 451 EconMdRqDndIO 1;
BA_ "SignalLongName" SG_ 451 EconMdRqDndIO "Economy Mode Request Denied Indication On";
BA_ "SignalType" SG_ 451 EconMdRqDndIO "BLN";
BA_ "VNSigAllNodes" SG_ 451 EconMdAtvIO 1;
BA_ "SignalLongName" SG_ 451 EconMdAtvIO "Economy Mode Active Indication On";
BA_ "SignalType" SG_ 451 EconMdAtvIO "BLN";
BA_ "VNSigAllNodes" SG_ 451 AppCltchAutSrtIO 1;
BA_ "SignalLongName" SG_ 451 AppCltchAutSrtIO "Apply Clutch For Automatic Start Indication On";
BA_ "SignalType" SG_ 451 AppCltchAutSrtIO "BLN";
BA_ "VNSigAllNodes" SG_ 451 AccPosV 1;
BA_ "SignalLongName" SG_ 451 AccPosV "Accelerator Effective Position Validity";
BA_ "SignalType" SG_ 451 AccPosV "ENM";
BA_ "VNSigAllNodes" SG_ 451 AccPos 1;
BA_ "SignalLongName" SG_ 451 AccPos "Accelerator Effective Position";
BA_ "SignalType" SG_ 451 AccPos "UNM";
BA_ "VNSigAllNodes" SG_ 451 FuelFltRmnLf 1;
BA_ "SignalLongName" SG_ 451 FuelFltRmnLf "Fuel Filter Remaining Life";
BA_ "SignalType" SG_ 451 FuelFltRmnLf "UNM";
BA_ "VNSigAllNodes" SG_ 451 PTRegGenCntlAct 1;
BA_ "SignalLongName" SG_ 451 PTRegGenCntlAct "Powertrain Regulated Generator Control Active";
BA_ "SignalType" SG_ 451 PTRegGenCntlAct "BLN";
BA_ "VNSigAllNodes" SG_ 451 EngTrqRdFlrSt 1;
BA_ "SignalLongName" SG_ 451 EngTrqRdFlrSt "Engine Torque Reduction Failure Status";
BA_ "SignalType" SG_ 451 EngTrqRdFlrSt "ENM";
BA_ "VNSigAllNodes" SG_ 451 EngTrqDrRqdExtRngV 1;
BA_ "SignalLongName" SG_ 451 EngTrqDrRqdExtRngV "Engine Torque Driver Requested Extended Range Validity";
BA_ "SignalType" SG_ 451 EngTrqDrRqdExtRngV "ENM";
BA_ "VNSigAllNodes" SG_ 451 EngTrqDrRqdExtRng 1;
BA_ "GenSigStartValue" SG_ 451 EngTrqDrRqdExtRng 1696;
BA_ "SignalLongName" SG_ 451 EngTrqDrRqdExtRng "Engine Torque Driver Requested Extended Range";
BA_ "SignalType" SG_ 451 EngTrqDrRqdExtRng "UNM";
BA_ "VNSigAllNodes" SG_ 451 EngTrqActExtRngV 1;
BA_ "SignalLongName" SG_ 451 EngTrqActExtRngV "Engine Torque Actual Extended Range Validity";
BA_ "SignalType" SG_ 451 EngTrqActExtRngV "ENM";
BA_ "VNSigAllNodes" SG_ 451 EngTrqActExtRng 1;
BA_ "GenSigStartValue" SG_ 451 EngTrqActExtRng 1696;
BA_ "SignalLongName" SG_ 451 EngTrqActExtRng "Engine Torque Actual Extended Range";
BA_ "SignalType" SG_ 451 EngTrqActExtRng "UNM";
BA_ "GenSigSendOnInit_signal" SG_ 320 IntDimDspLvlPlt 2;
BA_ "GenSigSendType_signal" SG_ 320 IntDimDspLvlPlt 12;
BA_ "GenSigDeltaValue" SG_ 320 IntDimDspLvlPlt 1;
BA_ "VNSigAllNodes" SG_ 320 IntDimDspLvlPlt 1;
BA_ "SignalLongName" SG_ 320 IntDimDspLvlPlt "Interior Dimming Display Level platform";
BA_ "SignalType" SG_ 320 IntDimDspLvlPlt "UNM";
BA_ "GenSigSendOnInit" SG_ 320 IntDimDspLvlPlt 2;
BA_ "GenSigSendType" SG_ 320 IntDimDspLvlPlt 12;
BA_ "GenSigSendOnInit_signal" SG_ 320 IntDimLvl 2;
BA_ "GenSigSendType_signal" SG_ 320 IntDimLvl 12;
BA_ "GenSigDeltaValue" SG_ 320 IntDimLvl 1;
BA_ "VNSigAllNodes" SG_ 320 IntDimLvl 1;
BA_ "SignalLongName" SG_ 320 IntDimLvl "Interior Dimming Level";
BA_ "SignalType" SG_ 320 IntDimLvl "UNM";
BA_ "GenSigSendOnInit" SG_ 320 IntDimLvl 2;
BA_ "GenSigSendType" SG_ 320 IntDimLvl 12;
BA_ "GenSigSendOnInit_signal" SG_ 320 HiBmIO 2;
BA_ "GenSigSendType_signal" SG_ 320 HiBmIO 10;
BA_ "VNSigAllNodes" SG_ 320 HiBmIO 1;
BA_ "SignalLongName" SG_ 320 HiBmIO "High Beam Indication On";
BA_ "SignalType" SG_ 320 HiBmIO "BLN";
BA_ "GenSigSendOnInit" SG_ 320 HiBmIO 2;
BA_ "GenSigSendType" SG_ 320 HiBmIO 10;
BA_ "GenSigSendType_signal" SG_ 320 PrkLtIO 10;
BA_ "VNSigAllNodes" SG_ 320 PrkLtIO 1;
BA_ "SignalLongName" SG_ 320 PrkLtIO "Park Light Indication On";
BA_ "GenSigSendType_signal" SG_ 320 RrFgLtIO 10;
BA_ "VNSigAllNodes" SG_ 320 RrFgLtIO 1;
BA_ "SignalLongName" SG_ 320 RrFgLtIO "Rear Fog Light Indication On";
BA_ "SignalType" SG_ 320 RrFgLtIO "BLN";
BA_ "GenSigSendType_signal" SG_ 320 FrFgLtIO 10;
BA_ "VNSigAllNodes" SG_ 320 FrFgLtIO 1;
BA_ "SignalLongName" SG_ 320 FrFgLtIO "Front Fog Light Indication On";
BA_ "SignalType" SG_ 320 FrFgLtIO "BLN";
BA_ "SignalLongName" SG_ 320 RtTrnLmpAtv "Right Turn Lamp active";
BA_ "GenSigSendOnInit" SG_ 320 RtTrnLmpAtv 2;
BA_ "GenSigSendOnInit_signal" SG_ 320 LftTrnLmpAtv 2;
BA_ "GenSigSendType_signal" SG_ 320 LftTrnLmpAtv 10;
BA_ "VNSigAllNodes" SG_ 320 LftTrnLmpAtv 1;
BA_ "SignalLongName" SG_ 320 LftTrnLmpAtv "Left Turn Lamp Active";
BA_ "SignalType" SG_ 320 LftTrnLmpAtv "ENM";
BA_ "GenSigSendOnInit" SG_ 320 LftTrnLmpAtv 2;
BA_ "GenSigSendType_signal" SG_ 320 HazSwAtv 10;
BA_ "VNSigAllNodes" SG_ 320 HazSwAtv 1;
BA_ "SignalLongName" SG_ 320 HazSwAtv "Hazard Switch Active";
BA_ "SignalType" SG_ 320 HazSwAtv "BLN";
BA_ "GenSigSendType_signal" SG_ 320 BrkLtsAtv 10;
BA_ "VNSigAllNodes" SG_ 320 BrkLtsAtv 1;
BA_ "SignalLongName" SG_ 320 BrkLtsAtv "Brake Lights Active";
BA_ "SignalType" SG_ 320 BrkLtsAtv "BLN";
BA_ "GenSigSendType" SG_ 320 BrkLtsAtv 12;
BA_ "GenSigSendType_signal" SG_ 320 TrnSwAct 10;
BA_ "VNSigAllNodes" SG_ 320 TrnSwAct 1;
BA_ "SignalLongName" SG_ 320 TrnSwAct "Turn Switch Activation";
BA_ "SignalType" SG_ 320 TrnSwAct "ENM";
BA_ "GenSigSendType_signal" SG_ 320 RrFogLmpsAct 10;
BA_ "VNSigAllNodes" SG_ 320 RrFogLmpsAct 1;
BA_ "SignalLongName" SG_ 320 RrFogLmpsAct "Rear Fog Lamps Active";
BA_ "SignalType" SG_ 320 RrFogLmpsAct "BLN";
BA_ "GenSigSendType_signal" SG_ 320 OtsdAmbtLtLvlStatV 10;
BA_ "VNSigAllNodes" SG_ 320 OtsdAmbtLtLvlStatV 1;
BA_ "SignalLongName" SG_ 320 OtsdAmbtLtLvlStatV "Outside Ambient Light Level Status Validity";
BA_ "SignalType" SG_ 320 OtsdAmbtLtLvlStatV "ENM";
BA_ "GenSigSendType_signal" SG_ 320 OtsdAmbtLtLvlStat 10;
BA_ "VNSigAllNodes" SG_ 320 OtsdAmbtLtLvlStat 1;
BA_ "SignalLongName" SG_ 320 OtsdAmbtLtLvlStat "Outside Ambient Light Level Status";
BA_ "SignalType" SG_ 320 OtsdAmbtLtLvlStat "ENM";
BA_ "GenSigSendType_signal" SG_ 320 MainLghtSw 10;
BA_ "VNSigAllNodes" SG_ 320 MainLghtSw 1;
BA_ "SignalLongName" SG_ 320 MainLghtSw "Main Light Switch";
BA_ "SignalType" SG_ 320 MainLghtSw "ENM";
BA_ "GenSigSendType_signal" SG_ 320 LowBmAct 10;
BA_ "VNSigAllNodes" SG_ 320 LowBmAct 1;
BA_ "SignalLongName" SG_ 320 LowBmAct "Low Beam Active";
BA_ "SignalType" SG_ 320 LowBmAct "BLN";
BA_ "GenSigSendType" SG_ 320 LowBmAct 10;
BA_ "GenSigSendType_signal" SG_ 320 HighBmAct 10;
BA_ "VNSigAllNodes" SG_ 320 HighBmAct 1;
BA_ "SignalLongName" SG_ 320 HighBmAct "High Beam Active";
BA_ "SignalType" SG_ 320 HighBmAct "BLN";
BA_ "GenSigSendType" SG_ 320 HighBmAct 12;
BA_ "GenSigSendType_signal" SG_ 320 HdlmpBmSelectStat 10;
BA_ "VNSigAllNodes" SG_ 320 HdlmpBmSelectStat 1;
BA_ "SignalLongName" SG_ 320 HdlmpBmSelectStat "Headlamp Beam Select Status";
BA_ "SignalType" SG_ 320 HdlmpBmSelectStat "ENM";
BA_ "GenSigSendType_signal" SG_ 320 FlToPsSwAtv 10;
BA_ "VNSigAllNodes" SG_ 320 FlToPsSwAtv 1;
BA_ "SignalLongName" SG_ 320 FlToPsSwAtv "Flash To Pass Switch Active";
BA_ "SignalType" SG_ 320 FlToPsSwAtv "BLN";
BA_ "GenSigSendType" SG_ 320 FlToPsSwAtv 12;
BA_ "GenSigSendType_signal" SG_ 320 AdvFrntLghtSysEnbld 10;
BA_ "VNSigAllNodes" SG_ 320 AdvFrntLghtSysEnbld 1;
BA_ "SignalLongName" SG_ 320 AdvFrntLghtSysEnbld "Advanced Front Lighting System Enabled";
BA_ "SignalType" SG_ 320 AdvFrntLghtSysEnbld "BLN";
BA_ "GenSigSendType" SG_ 320 AdvFrntLghtSysEnbld 12;
BA_ "GenSigSendType_signal" SG_ 320 FrFogLmpsAct 10;
BA_ "VNSigAllNodes" SG_ 320 FrFogLmpsAct 1;
BA_ "SignalLongName" SG_ 320 FrFogLmpsAct "Front Fog Lamps Active";
BA_ "SignalType" SG_ 320 FrFogLmpsAct "BLN";
BA_ "GenSigSendType_signal" SG_ 320 AutLghtCtrl 10;
BA_ "VNSigAllNodes" SG_ 320 AutLghtCtrl 1;
BA_ "SignalLongName" SG_ 320 AutLghtCtrl "Auto Light Control";
BA_ "SignalType" SG_ 320 AutLghtCtrl "BLN";
BA_ "GenSigSendType" SG_ 320 AutLghtCtrl 12;
BA_ "VNSigAllNodes" SG_ 1919 DTCI_DTCFaultType_77F 1;
BA_ "SignalLongName" SG_ 1919 DTCI_DTCFaultType_77F "Diagnostic Trouble Code Information Extended 77F : Diagnostic Trouble Code Fault Type";
BA_ "PacketOrder" SG_ 1919 DTCI_DTCFaultType_77F 20;
BA_ "SignalType" SG_ 1919 DTCI_DTCFaultType_77F "ENM";
BA_ "VNSigAllNodes" SG_ 1919 DTCI_CodeSupported_77F 1;
BA_ "SignalLongName" SG_ 1919 DTCI_CodeSupported_77F "Diagnostic Trouble Code Information Extended 77F : Code Supported";
BA_ "PacketOrder" SG_ 1919 DTCI_CodeSupported_77F 19;
BA_ "SignalType" SG_ 1919 DTCI_CodeSupported_77F "BLN";
BA_ "VNSigAllNodes" SG_ 1919 DTCI_CurrentStatus_77F 1;
BA_ "SignalLongName" SG_ 1919 DTCI_CurrentStatus_77F "Diagnostic Trouble Code Information Extended 77F : Current Status";
BA_ "PacketOrder" SG_ 1919 DTCI_CurrentStatus_77F 18;
BA_ "SignalType" SG_ 1919 DTCI_CurrentStatus_77F "BLN";
BA_ "VNSigAllNodes" SG_ 1919 DTCI_TstNPsdCdClrdSt_77F 1;
BA_ "SignalLongName" SG_ 1919 DTCI_TstNPsdCdClrdSt_77F "Diagnostic Trouble Code Information Extended 77F : Test Not Passed Since Code Cleared Status";
BA_ "PacketOrder" SG_ 1919 DTCI_TstNPsdCdClrdSt_77F 17;
BA_ "SignalType" SG_ 1919 DTCI_TstNPsdCdClrdSt_77F "BLN";
BA_ "VNSigAllNodes" SG_ 1919 DTCI_TstFldCdClrdStat_77F 1;
BA_ "SignalLongName" SG_ 1919 DTCI_TstFldCdClrdStat_77F "Diagnostic Trouble Code Information Extended 77F : Test Failed Since Code Cleared Status";
BA_ "PacketOrder" SG_ 1919 DTCI_TstFldCdClrdStat_77F 16;
BA_ "SignalType" SG_ 1919 DTCI_TstFldCdClrdStat_77F "BLN";
BA_ "VNSigAllNodes" SG_ 1919 DTCI_HistStat_77F 1;
BA_ "SignalLongName" SG_ 1919 DTCI_HistStat_77F "Diagnostic Trouble Code Information Extended 77F : History Status";
BA_ "PacketOrder" SG_ 1919 DTCI_HistStat_77F 15;
BA_ "SignalType" SG_ 1919 DTCI_HistStat_77F "BLN";
BA_ "VNSigAllNodes" SG_ 1919 DTCI_TstNPsdPwrUpSt_77F 1;
BA_ "SignalLongName" SG_ 1919 DTCI_TstNPsdPwrUpSt_77F "Diagnostic Trouble Code Information Extended 77F : Test Not Passed Since Power Up Status";
BA_ "PacketOrder" SG_ 1919 DTCI_TstNPsdPwrUpSt_77F 14;
BA_ "SignalType" SG_ 1919 DTCI_TstNPsdPwrUpSt_77F "BLN";
BA_ "VNSigAllNodes" SG_ 1919 DTCI_TstFldPwrUpSt_77F 1;
BA_ "SignalLongName" SG_ 1919 DTCI_TstFldPwrUpSt_77F "Diagnostic Trouble Code Information Extended 77F : Test Failed Since Power Up Status";
BA_ "PacketOrder" SG_ 1919 DTCI_TstFldPwrUpSt_77F 13;
BA_ "SignalType" SG_ 1919 DTCI_TstFldPwrUpSt_77F "BLN";
BA_ "VNSigAllNodes" SG_ 1919 DTCI_WrnIndRqdSt_77F 1;
BA_ "SignalLongName" SG_ 1919 DTCI_WrnIndRqdSt_77F "Diagnostic Trouble Code Information Extended 77F : Warning Indicator Requested Status";
BA_ "PacketOrder" SG_ 1919 DTCI_WrnIndRqdSt_77F 12;
BA_ "SignalType" SG_ 1919 DTCI_WrnIndRqdSt_77F "BLN";
BA_ "VNSigAllNodes" SG_ 1919 DTCI_DTCFailType_77F 1;
BA_ "SignalLongName" SG_ 1919 DTCI_DTCFailType_77F "Diagnostic Trouble Code Information Extended 77F : Diagnostic Trouble Code Failure Type";
BA_ "PacketOrder" SG_ 1919 DTCI_DTCFailType_77F 11;
BA_ "SignalType" SG_ 1919 DTCI_DTCFailType_77F "UNM";
BA_ "VNSigAllNodes" SG_ 1919 DTCI_DTCNumber_77F 1;
BA_ "SignalLongName" SG_ 1919 DTCI_DTCNumber_77F "Diagnostic Trouble Code Information Extended 77F : Diagnostic Trouble Code Number";
BA_ "PacketOrder" SG_ 1919 DTCI_DTCNumber_77F 10;
BA_ "SignalType" SG_ 1919 DTCI_DTCNumber_77F "UNM";
BA_ "VNSigAllNodes" SG_ 1919 DTCI_DTCSource_77F 1;
BA_ "SignalLongName" SG_ 1919 DTCI_DTCSource_77F "Diagnostic Trouble Code Information Extended 77F : Diagnostic Trouble Code Source";
BA_ "PacketOrder" SG_ 1919 DTCI_DTCSource_77F 9;
BA_ "SignalType" SG_ 1919 DTCI_DTCSource_77F "UNM";
BA_ "VNSigAllNodes" SG_ 1919 DTCI_DTCTriggered_77F 1;
BA_ "SignalLongName" SG_ 1919 DTCI_DTCTriggered_77F "Diagnostic Trouble Code Information Extended 77F : Diagnostic Trouble Code Triggered";
BA_ "PacketOrder" SG_ 1919 DTCI_DTCTriggered_77F 8;
BA_ "SignalType" SG_ 1919 DTCI_DTCTriggered_77F "BLN";
BA_ "VNSigAllNodes" SG_ 1919 DTCIUnused7_77F 1;
BA_ "SignalLongName" SG_ 1919 DTCIUnused7_77F "Diagnostic Trouble Code Information Extended 77F : Unused 7";
BA_ "PacketOrder" SG_ 1919 DTCIUnused7_77F 7;
BA_ "SignalType" SG_ 1919 DTCIUnused7_77F "BLN";
BA_ "VNSigAllNodes" SG_ 1919 DTCIUnused6_77F 1;
BA_ "SignalLongName" SG_ 1919 DTCIUnused6_77F "Diagnostic Trouble Code Information Extended 77F : Unused 6";
BA_ "PacketOrder" SG_ 1919 DTCIUnused6_77F 6;
BA_ "SignalType" SG_ 1919 DTCIUnused6_77F "BLN";
BA_ "VNSigAllNodes" SG_ 1919 DTCIUnused5_77F 1;
BA_ "SignalLongName" SG_ 1919 DTCIUnused5_77F "Diagnostic Trouble Code Information Extended 77F : Unused 5";
BA_ "PacketOrder" SG_ 1919 DTCIUnused5_77F 5;
BA_ "SignalType" SG_ 1919 DTCIUnused5_77F "BLN";
BA_ "VNSigAllNodes" SG_ 1919 DTCIUnused4_77F 1;
BA_ "SignalLongName" SG_ 1919 DTCIUnused4_77F "Diagnostic Trouble Code Information Extended 77F : Unused 4";
BA_ "PacketOrder" SG_ 1919 DTCIUnused4_77F 4;
BA_ "SignalType" SG_ 1919 DTCIUnused4_77F "BLN";
BA_ "VNSigAllNodes" SG_ 1919 DTCIUnused3_77F 1;
BA_ "SignalLongName" SG_ 1919 DTCIUnused3_77F "Diagnostic Trouble Code Information Extended 77F : Unused 3";
BA_ "PacketOrder" SG_ 1919 DTCIUnused3_77F 3;
BA_ "SignalType" SG_ 1919 DTCIUnused3_77F "BLN";
BA_ "VNSigAllNodes" SG_ 1919 DTCIUnused2_77F 1;
BA_ "SignalLongName" SG_ 1919 DTCIUnused2_77F "Diagnostic Trouble Code Information Extended 77F : Unused 2";
BA_ "PacketOrder" SG_ 1919 DTCIUnused2_77F 2;
BA_ "SignalType" SG_ 1919 DTCIUnused2_77F "BLN";
BA_ "VNSigAllNodes" SG_ 1919 DTCIUnused1_77F 1;
BA_ "SignalLongName" SG_ 1919 DTCIUnused1_77F "Diagnostic Trouble Code Information Extended 77F : Unused 1";
BA_ "PacketOrder" SG_ 1919 DTCIUnused1_77F 1;
BA_ "SignalType" SG_ 1919 DTCIUnused1_77F "BLN";
BA_ "VNSigAllNodes" SG_ 588 DgnInf 1;
BA_ "SignalLongName" SG_ 588 DgnInf "Diagnostic Information";
BA_ "SignalType" SG_ 588 DgnInf "UNM";
BA_ "VNSigSLHSSharedDiagnostic" SG_ 588 DgnInf 1;
BA_ "VNSigAllNodes" SG_ 499 ElecShftPFShftIntlckPer 1;
BA_ "SignalLongName" SG_ 499 ElecShftPFShftIntlckPer "Electronic Shift Platform Shift Interlock Permission";
BA_ "SignalType" SG_ 499 ElecShftPFShftIntlckPer "ENM";
BA_ "VNSigAllNodes" SG_ 499 PTShftPtrnOvrdAct 1;
BA_ "SignalLongName" SG_ 499 PTShftPtrnOvrdAct "Powertrain Shift Pattern Override Active";
BA_ "SignalType" SG_ 499 PTShftPtrnOvrdAct "BLN";
BA_ "VNSigAllNodes" SG_ 499 PFTrnsTUDSecSwSt 1;
BA_ "SignalLongName" SG_ 499 PFTrnsTUDSecSwSt "Platform Transmission Tap Up/Down Secondary Switch State";
BA_ "SignalType" SG_ 499 PFTrnsTUDSecSwSt "ENM";
BA_ "VNSigAllNodes" SG_ 499 TrnsPFShftPattSwARC 1;
BA_ "SignalLongName" SG_ 499 TrnsPFShftPattSwARC "Transmission Platform Shift Pattern Switch Alive Rolling Count";
BA_ "SignalType" SG_ 499 TrnsPFShftPattSwARC "UNM";
BA_ "VNSigAllNodes" SG_ 499 TrnsPFShftPattSw4Act 1;
BA_ "SignalLongName" SG_ 499 TrnsPFShftPattSw4Act "Transmission Platform Shift Pattern Switch 4 Active";
BA_ "SignalType" SG_ 499 TrnsPFShftPattSw4Act "BLN";
BA_ "VNSigAllNodes" SG_ 499 TrnsPFShftPattSw3Act 1;
BA_ "SignalLongName" SG_ 499 TrnsPFShftPattSw3Act "Transmission Platform Shift Pattern Switch 3 Active";
BA_ "SignalType" SG_ 499 TrnsPFShftPattSw3Act "BLN";
BA_ "VNSigAllNodes" SG_ 499 TrnsPFShftPattSw2Act 1;
BA_ "SignalLongName" SG_ 499 TrnsPFShftPattSw2Act "Transmission Platform Shift Pattern Switch 2 Active";
BA_ "SignalType" SG_ 499 TrnsPFShftPattSw2Act "BLN";
BA_ "VNSigAllNodes" SG_ 499 TrnsPFShftPattSw1Act 1;
BA_ "SignalLongName" SG_ 499 TrnsPFShftPattSw1Act "Transmission Platform Shift Pattern Switch 1 Active";
BA_ "SignalType" SG_ 499 TrnsPFShftPattSw1Act "BLN";
BA_ "VNSigAllNodes" SG_ 499 PFTrnsTUDSwStAlvRC 1;
BA_ "SignalLongName" SG_ 499 PFTrnsTUDSwStAlvRC "Platform Transmission Tap Up/Down Switch Status Alive Rolling Count";
BA_ "SignalType" SG_ 499 PFTrnsTUDSwStAlvRC "UNM";
BA_ "VNSigAllNodes" SG_ 499 PFTrnsTUDSwSt 1;
BA_ "SignalLongName" SG_ 499 PFTrnsTUDSwSt "Platform Transmission Tap Up/Down Switch State";
BA_ "SignalType" SG_ 499 PFTrnsTUDSwSt "ENM";
BA_ "VNSigAllNodes" SG_ 499 PFTrnsTUDEnSwSt 1;
BA_ "SignalLongName" SG_ 499 PFTrnsTUDEnSwSt "Platform Transmission Tap Up/Down Enable Switch State";
BA_ "SignalType" SG_ 499 PFTrnsTUDEnSwSt "ENM";
BA_ "VNSigAllNodes" SG_ 499 OvrdrvDsblReqd 1;
BA_ "SignalLongName" SG_ 499 OvrdrvDsblReqd "Overdrive Disable Requested";
BA_ "SignalType" SG_ 499 OvrdrvDsblReqd "BLN";
BA_ "VNSigAllNodes" SG_ 1906 DTCI_DTCFaultType_772 1;
BA_ "SignalLongName" SG_ 1906 DTCI_DTCFaultType_772 "Diagnostic Trouble Code Information Extended 772 : Diagnostic Trouble Code Fault Type";
BA_ "PacketOrder" SG_ 1906 DTCI_DTCFaultType_772 20;
BA_ "SignalType" SG_ 1906 DTCI_DTCFaultType_772 "ENM";
BA_ "VNSigAllNodes" SG_ 1906 DTCI_CodeSupported_772 1;
BA_ "SignalLongName" SG_ 1906 DTCI_CodeSupported_772 "Diagnostic Trouble Code Information Extended 772 : Code Supported";
BA_ "PacketOrder" SG_ 1906 DTCI_CodeSupported_772 19;
BA_ "SignalType" SG_ 1906 DTCI_CodeSupported_772 "BLN";
BA_ "VNSigAllNodes" SG_ 1906 DTCI_CurrentStatus_772 1;
BA_ "SignalLongName" SG_ 1906 DTCI_CurrentStatus_772 "Diagnostic Trouble Code Information Extended 772 : Current Status";
BA_ "PacketOrder" SG_ 1906 DTCI_CurrentStatus_772 18;
BA_ "SignalType" SG_ 1906 DTCI_CurrentStatus_772 "BLN";
BA_ "VNSigAllNodes" SG_ 1906 DTCI_TstNPsdCdClrdSt_772 1;
BA_ "SignalLongName" SG_ 1906 DTCI_TstNPsdCdClrdSt_772 "Diagnostic Trouble Code Information Extended 772 : Test Not Passed Since Code Cleared Status";
BA_ "PacketOrder" SG_ 1906 DTCI_TstNPsdCdClrdSt_772 17;
BA_ "SignalType" SG_ 1906 DTCI_TstNPsdCdClrdSt_772 "BLN";
BA_ "VNSigAllNodes" SG_ 1906 DTCI_TstFldCdClrdStat_772 1;
BA_ "SignalLongName" SG_ 1906 DTCI_TstFldCdClrdStat_772 "Diagnostic Trouble Code Information Extended 772 : Test Failed Since Code Cleared Status";
BA_ "PacketOrder" SG_ 1906 DTCI_TstFldCdClrdStat_772 16;
BA_ "SignalType" SG_ 1906 DTCI_TstFldCdClrdStat_772 "BLN";
BA_ "VNSigAllNodes" SG_ 1906 DTCI_HistStat_772 1;
BA_ "SignalLongName" SG_ 1906 DTCI_HistStat_772 "Diagnostic Trouble Code Information Extended 772 : History Status";
BA_ "PacketOrder" SG_ 1906 DTCI_HistStat_772 15;
BA_ "SignalType" SG_ 1906 DTCI_HistStat_772 "BLN";
BA_ "VNSigAllNodes" SG_ 1906 DTCI_TstNPsdPwrUpSt_772 1;
BA_ "SignalLongName" SG_ 1906 DTCI_TstNPsdPwrUpSt_772 "Diagnostic Trouble Code Information Extended 772 : Test Not Passed Since Power Up Status";
BA_ "PacketOrder" SG_ 1906 DTCI_TstNPsdPwrUpSt_772 14;
BA_ "SignalType" SG_ 1906 DTCI_TstNPsdPwrUpSt_772 "BLN";
BA_ "VNSigAllNodes" SG_ 1906 DTCI_TstFldPwrUpSt_772 1;
BA_ "SignalLongName" SG_ 1906 DTCI_TstFldPwrUpSt_772 "Diagnostic Trouble Code Information Extended 772 : Test Failed Since Power Up Status";
BA_ "PacketOrder" SG_ 1906 DTCI_TstFldPwrUpSt_772 13;
BA_ "SignalType" SG_ 1906 DTCI_TstFldPwrUpSt_772 "BLN";
BA_ "VNSigAllNodes" SG_ 1906 DTCI_WrnIndRqdSt_772 1;
BA_ "SignalLongName" SG_ 1906 DTCI_WrnIndRqdSt_772 "Diagnostic Trouble Code Information Extended 772 : Warning Indicator Requested Status";
BA_ "PacketOrder" SG_ 1906 DTCI_WrnIndRqdSt_772 12;
BA_ "SignalType" SG_ 1906 DTCI_WrnIndRqdSt_772 "BLN";
BA_ "VNSigAllNodes" SG_ 1906 DTCI_DTCFailType_772 1;
BA_ "SignalLongName" SG_ 1906 DTCI_DTCFailType_772 "Diagnostic Trouble Code Information Extended 772 : Diagnostic Trouble Code Failure Type";
BA_ "PacketOrder" SG_ 1906 DTCI_DTCFailType_772 11;
BA_ "SignalType" SG_ 1906 DTCI_DTCFailType_772 "UNM";
BA_ "VNSigAllNodes" SG_ 1906 DTCI_DTCNumber_772 1;
BA_ "SignalLongName" SG_ 1906 DTCI_DTCNumber_772 "Diagnostic Trouble Code Information Extended 772 : Diagnostic Trouble Code Number";
BA_ "PacketOrder" SG_ 1906 DTCI_DTCNumber_772 10;
BA_ "SignalType" SG_ 1906 DTCI_DTCNumber_772 "UNM";
BA_ "VNSigAllNodes" SG_ 1906 DTCI_DTCSource_772 1;
BA_ "SignalLongName" SG_ 1906 DTCI_DTCSource_772 "Diagnostic Trouble Code Information Extended 772 : Diagnostic Trouble Code Source";
BA_ "PacketOrder" SG_ 1906 DTCI_DTCSource_772 9;
BA_ "SignalType" SG_ 1906 DTCI_DTCSource_772 "UNM";
BA_ "VNSigAllNodes" SG_ 1906 DTCI_DTCTriggered_772 1;
BA_ "SignalLongName" SG_ 1906 DTCI_DTCTriggered_772 "Diagnostic Trouble Code Information Extended 772 : Diagnostic Trouble Code Triggered";
BA_ "PacketOrder" SG_ 1906 DTCI_DTCTriggered_772 8;
BA_ "SignalType" SG_ 1906 DTCI_DTCTriggered_772 "BLN";
BA_ "VNSigAllNodes" SG_ 1906 DTCIUnused7_772 1;
BA_ "SignalLongName" SG_ 1906 DTCIUnused7_772 "Diagnostic Trouble Code Information Extended 772 : Unused 7";
BA_ "PacketOrder" SG_ 1906 DTCIUnused7_772 7;
BA_ "SignalType" SG_ 1906 DTCIUnused7_772 "BLN";
BA_ "VNSigAllNodes" SG_ 1906 DTCIUnused6_772 1;
BA_ "SignalLongName" SG_ 1906 DTCIUnused6_772 "Diagnostic Trouble Code Information Extended 772 : Unused 6";
BA_ "PacketOrder" SG_ 1906 DTCIUnused6_772 6;
BA_ "SignalType" SG_ 1906 DTCIUnused6_772 "BLN";
BA_ "VNSigAllNodes" SG_ 1906 DTCIUnused5_772 1;
BA_ "SignalLongName" SG_ 1906 DTCIUnused5_772 "Diagnostic Trouble Code Information Extended 772 : Unused 5";
BA_ "PacketOrder" SG_ 1906 DTCIUnused5_772 5;
BA_ "SignalType" SG_ 1906 DTCIUnused5_772 "BLN";
BA_ "VNSigAllNodes" SG_ 1906 DTCIUnused4_772 1;
BA_ "SignalLongName" SG_ 1906 DTCIUnused4_772 "Diagnostic Trouble Code Information Extended 772 : Unused 4";
BA_ "PacketOrder" SG_ 1906 DTCIUnused4_772 4;
BA_ "SignalType" SG_ 1906 DTCIUnused4_772 "BLN";
BA_ "VNSigAllNodes" SG_ 1906 DTCIUnused3_772 1;
BA_ "SignalLongName" SG_ 1906 DTCIUnused3_772 "Diagnostic Trouble Code Information Extended 772 : Unused 3";
BA_ "PacketOrder" SG_ 1906 DTCIUnused3_772 3;
BA_ "SignalType" SG_ 1906 DTCIUnused3_772 "BLN";
BA_ "VNSigAllNodes" SG_ 1906 DTCIUnused2_772 1;
BA_ "SignalLongName" SG_ 1906 DTCIUnused2_772 "Diagnostic Trouble Code Information Extended 772 : Unused 2";
BA_ "PacketOrder" SG_ 1906 DTCIUnused2_772 2;
BA_ "SignalType" SG_ 1906 DTCIUnused2_772 "BLN";
BA_ "VNSigAllNodes" SG_ 1906 DTCIUnused1_772 1;
BA_ "SignalLongName" SG_ 1906 DTCIUnused1_772 "Diagnostic Trouble Code Information Extended 772 : Unused 1";
BA_ "PacketOrder" SG_ 1906 DTCIUnused1_772 1;
BA_ "SignalType" SG_ 1906 DTCIUnused1_772 "BLN";
BA_ "VNSigAllNodes" SG_ 579 DgnInf 1;
BA_ "SignalLongName" SG_ 579 DgnInf "Diagnostic Information";
BA_ "SignalType" SG_ 579 DgnInf "UNM";
BA_ "VNSigSLHSSharedDiagnostic" SG_ 579 DgnInf 1;
BA_ "VNSigAllNodes" SG_ 1603 DgnInf 1;
BA_ "SignalLongName" SG_ 1603 DgnInf "Diagnostic Information";
BA_ "SignalType" SG_ 1603 DgnInf "UNM";
BA_ "VNSigSLHSSharedDiagnostic" SG_ 1603 DgnInf 1;
BA_ "VNSigAllNodes" SG_ 1347 DgnInf_HS 1;
BA_ "SignalLongName" SG_ 1347 DgnInf_HS "Diagnostic Information HS543";
BA_ "SignalType" SG_ 1347 DgnInf_HS "UNM";
BA_ "VNSigSLHSSharedDiagnostic" SG_ 1347 DgnInf_HS 1;
BA_ "VNSigAllNodes" SG_ 577 DgnInf 1;
BA_ "SignalLongName" SG_ 577 DgnInf "Diagnostic Information";
BA_ "SignalType" SG_ 577 DgnInf "UNM";
BA_ "VNSigSLHSSharedDiagnostic" SG_ 577 DgnInf 1;
BA_ "GenSigSendOnInit_signal" SG_ 298 VhSecNImmoIndRq 1;
BA_ "GenSigSendType_signal" SG_ 298 VhSecNImmoIndRq 10;
BA_ "VNSigAllNodes" SG_ 298 VhSecNImmoIndRq 1;
BA_ "SignalLongName" SG_ 298 VhSecNImmoIndRq "Vehicle Security Non Immobilizer Indication Request";
BA_ "SignalType" SG_ 298 VhSecNImmoIndRq "ENM";
BA_ "VNSigAllNodes" SG_ 298 ChmAct 1;
BA_ "SignalLongName" SG_ 298 ChmAct "Chime Active";
BA_ "SignalType" SG_ 298 ChmAct "BLN";
BA_ "VNSigAllNodes" SG_ 298 DDAjrSwAtvM 1;
BA_ "SignalLongName" SG_ 298 DDAjrSwAtvM "Driver Door Ajar Switch Active Mask";
BA_ "SignalType" SG_ 298 DDAjrSwAtvM "ENM";
BA_ "VNSigAllNodes" SG_ 298 CrshAlrtDrvrSlctdType 1;
BA_ "SignalLongName" SG_ 298 CrshAlrtDrvrSlctdType "Crash Alert Driver Selected Type";
BA_ "SignalType" SG_ 298 CrshAlrtDrvrSlctdType "ENM";
BA_ "VNSigAllNodes" SG_ 298 PsSbltAtcV 1;
BA_ "SignalLongName" SG_ 298 PsSbltAtcV "Passenger Seatbelt Attached Validity";
BA_ "SignalType" SG_ 298 PsSbltAtcV "ENM";
BA_ "VNSigAllNodes" SG_ 298 PsSbltAtc 1;
BA_ "SignalLongName" SG_ 298 PsSbltAtc "Passenger Seatbelt Attached";
BA_ "SignalType" SG_ 298 PsSbltAtc "BLN";
BA_ "VNSigAllNodes" SG_ 298 TrlrBrkDsplyAct 1;
BA_ "SignalLongName" SG_ 298 TrlrBrkDsplyAct "Trailer Brake Display Active";
BA_ "SignalType" SG_ 298 TrlrBrkDsplyAct "BLN";
BA_ "VNSigAllNodes" SG_ 298 RdSpdCatType 1;
BA_ "SignalLongName" SG_ 298 RdSpdCatType "Road Speed Category Type";
BA_ "SignalType" SG_ 298 RdSpdCatType "ENM";
BA_ "VNSigAllNodes" SG_ 298 LnCat 1;
BA_ "SignalLongName" SG_ 298 LnCat "Lane Category";
BA_ "SignalType" SG_ 298 LnCat "ENM";
BA_ "VNSigAllNodes" SG_ 298 FncRdClass 1;
BA_ "SignalLongName" SG_ 298 FncRdClass "Functional Road Class";
BA_ "SignalType" SG_ 298 FncRdClass "ENM";
BA_ "VNSigAllNodes" SG_ 298 SprtLnRd 1;
BA_ "SignalLongName" SG_ 298 SprtLnRd "Separate Lane Road";
BA_ "SignalType" SG_ 298 SprtLnRd "BLN";
BA_ "VNSigAllNodes" SG_ 298 CntrldAccRd 1;
BA_ "SignalLongName" SG_ 298 CntrldAccRd "Controlled Access Road";
BA_ "SignalType" SG_ 298 CntrldAccRd "BLN";
BA_ "VNSigAllNodes" SG_ 298 BldUpArDet 1;
BA_ "SignalLongName" SG_ 298 BldUpArDet "Build Up Area Detected";
BA_ "SignalType" SG_ 298 BldUpArDet "BLN";
BA_ "VNSigAllNodes" SG_ 298 MpDataAvlbl 1;
BA_ "SignalLongName" SG_ 298 MpDataAvlbl "Map Data Available";
BA_ "SignalType" SG_ 298 MpDataAvlbl "BLN";
BA_ "VNSigAllNodes" SG_ 298 SusCustStngReq 1;
BA_ "SignalLongName" SG_ 298 SusCustStngReq "Suspension Customization Setting Request";
BA_ "SignalType" SG_ 298 SusCustStngReq "ENM";
BA_ "VNSigAllNodes" SG_ 298 StrCustStngReq 1;
BA_ "SignalLongName" SG_ 298 StrCustStngReq "Steering Customization Setting Request";
BA_ "SignalType" SG_ 298 StrCustStngReq "ENM";
BA_ "VNSigAllNodes" SG_ 298 RstrCustFctrDef 1;
BA_ "SignalLongName" SG_ 298 RstrCustFctrDef "Restore Customization Factory Defaults";
BA_ "SignalType" SG_ 298 RstrCustFctrDef "ENM";
BA_ "VNSigAllNodes" SG_ 298 DrvlnCustStngReq 1;
BA_ "SignalLongName" SG_ 298 DrvlnCustStngReq "Driveline Customization Setting Request";
BA_ "SignalType" SG_ 298 DrvlnCustStngReq "ENM";
BA_ "VNSigAllNodes" SG_ 298 ChmMstrVDA 1;
BA_ "GenSigStartValue" SG_ 298 ChmMstrVDA 1;
BA_ "SignalLongName" SG_ 298 ChmMstrVDA "Chime Master Virtual Device Availability";
BA_ "SignalType" SG_ 298 ChmMstrVDA "ENM";
BA_ "VNSigAllNodes" SG_ 298 IPCVDA 1;
BA_ "GenSigStartValue" SG_ 298 IPCVDA 1;
BA_ "SignalLongName" SG_ 298 IPCVDA "Instrument Panel Cluster Virtual Device Availability";
BA_ "SignalType" SG_ 298 IPCVDA "ENM";
BA_ "VNSigAllNodes" SG_ 298 HeadUpDispVDA 1;
BA_ "GenSigStartValue" SG_ 298 HeadUpDispVDA 1;
BA_ "SignalLongName" SG_ 298 HeadUpDispVDA "Head Up Display Virtual Device Availability";
BA_ "SignalType" SG_ 298 HeadUpDispVDA "ENM";
BA_ "VNSigAllNodes" SG_ 298 HapticSeatVDA 1;
BA_ "GenSigStartValue" SG_ 298 HapticSeatVDA 1;
BA_ "SignalLongName" SG_ 298 HapticSeatVDA "Haptic Seat Virtual Device Availability";
BA_ "SignalType" SG_ 298 HapticSeatVDA "ENM";
BA_ "VNSigAllNodes" SG_ 298 RRDoorAjarSwAct 1;
BA_ "SignalLongName" SG_ 298 RRDoorAjarSwAct "Rear Right Door Ajar Switch Active";
BA_ "SignalType" SG_ 298 RRDoorAjarSwAct "BLN";
BA_ "VNSigAllNodes" SG_ 298 PDAjrSwAtv 1;
BA_ "SignalLongName" SG_ 298 PDAjrSwAtv "Passenger Door Ajar Switch Active";
BA_ "SignalType" SG_ 298 PDAjrSwAtv "BLN";
BA_ "VNSigAllNodes" SG_ 298 DDAjrSwAtv 1;
BA_ "SignalLongName" SG_ 298 DDAjrSwAtv "Driver Door Ajar Switch Active";
BA_ "SignalType" SG_ 298 DDAjrSwAtv "BLN";
BA_ "VNSigAllNodes" SG_ 298 TrlrHWIntrfcVDA 1;
BA_ "GenSigStartValue" SG_ 298 TrlrHWIntrfcVDA 1;
BA_ "SignalLongName" SG_ 298 TrlrHWIntrfcVDA "Trailer Hardware Interface Virtual Device Availability";
BA_ "SignalType" SG_ 298 TrlrHWIntrfcVDA "ENM";
BA_ "VNSigAllNodes" SG_ 298 DrId 1;
BA_ "SignalLongName" SG_ 298 DrId "Driver Identifier";
BA_ "SignalType" SG_ 298 DrId "ENM";
BA_ "VNSigAllNodes" SG_ 298 EnrgMgtLdShdRq 1;
BA_ "SignalLongName" SG_ 298 EnrgMgtLdShdRq "Energy Management Load Shedding Request";
BA_ "SignalType" SG_ 298 EnrgMgtLdShdRq "ENM";
BA_ "VNSigAllNodes" SG_ 298 DrSbltAtcV 1;
BA_ "SignalLongName" SG_ 298 DrSbltAtcV "Driver Seatbelt Attached Validity";
BA_ "SignalType" SG_ 298 DrSbltAtcV "ENM";
BA_ "VNSigAllNodes" SG_ 298 TrlrHtchSwAtv 1;
BA_ "SignalLongName" SG_ 298 TrlrHtchSwAtv "Trailer Hitch Switch Active";
BA_ "SignalType" SG_ 298 TrlrHtchSwAtv "BLN";
BA_ "VNSigAllNodes" SG_ 298 TreInfMonSysRstReq 1;
BA_ "SignalLongName" SG_ 298 TreInfMonSysRstReq "Tire Inflation Monitoring System Reset Requested";
BA_ "SignalType" SG_ 298 TreInfMonSysRstReq "BLN";
BA_ "VNSigAllNodes" SG_ 298 HUDActv 1;
BA_ "SignalLongName" SG_ 298 HUDActv "Head Up Display Active";
BA_ "SignalType" SG_ 298 HUDActv "BLN";
BA_ "VNSigAllNodes" SG_ 298 BatVltV 1;
BA_ "SignalLongName" SG_ 298 BatVltV "Battery Voltage Validity";
BA_ "SignalType" SG_ 298 BatVltV "ENM";
BA_ "VNSigAllNodes" SG_ 298 BatVlt 1;
BA_ "SignalLongName" SG_ 298 BatVlt "Battery Voltage";
BA_ "SignalType" SG_ 298 BatVlt "UNM";
BA_ "VNSigAllNodes" SG_ 298 RLDoorAjarSwAct 1;
BA_ "SignalLongName" SG_ 298 RLDoorAjarSwAct "Rear Left Door Ajar Switch Active";
BA_ "SignalType" SG_ 298 RLDoorAjarSwAct "BLN";
BA_ "VNSigAllNodes" SG_ 298 DrSbltAtc 1;
BA_ "SignalLongName" SG_ 298 DrSbltAtc "Driver Seatbelt Attached";
BA_ "SignalType" SG_ 298 DrSbltAtc "BLN";
BA_ "VNSigAllNodes" SG_ 1601 DgnInf 1;
BA_ "SignalLongName" SG_ 1601 DgnInf "Diagnostic Information";
BA_ "SignalType" SG_ 1601 DgnInf "UNM";
BA_ "VNSigSLHSSharedDiagnostic" SG_ 1601 DgnInf 1;
BA_ "VNSigAllNodes" SG_ 2018 DgnInf 1;
BA_ "SignalLongName" SG_ 2018 DgnInf "Diagnostic Information";
BA_ "SignalType" SG_ 2018 DgnInf "UNM";
BA_ "VNSigSLHSSharedDiagnostic" SG_ 2018 DgnInf 1;
BA_ "VNSigAllNodes" SG_ 2026 DgnInf 1;
BA_ "SignalLongName" SG_ 2026 DgnInf "Diagnostic Information";
BA_ "SignalType" SG_ 2026 DgnInf "UNM";
BA_ "VNSigSLHSSharedDiagnostic" SG_ 2026 DgnInf 1;
BA_ "VNSigAllNodes" SG_ 1514 DgnInf 1;
BA_ "SignalLongName" SG_ 1514 DgnInf "Diagnostic Information";
BA_ "SignalType" SG_ 1514 DgnInf "UNM";
BA_ "VNSigSLHSSharedDiagnostic" SG_ 1514 DgnInf 1;
BA_ "VNSigAllNodes" SG_ 288 VehOdo 1;
BA_ "SignalLongName" SG_ 288 VehOdo "Vehicle Odometer";
BA_ "SignalType" SG_ 288 VehOdo "UNM";
BA_ "VNSigAllNodes" SG_ 288 VehOdoV 1;
BA_ "SignalLongName" SG_ 288 VehOdoV "Vehicle Odometer Validity";
BA_ "SignalType" SG_ 288 VehOdoV "ENM";
BA_ "VNSigAllNodes" SG_ 1001 DistRollCntAvgDrvnSrc 1;
BA_ "SignalLongName" SG_ 1001 DistRollCntAvgDrvnSrc "Distance Rolling Count Average Driven Source";
BA_ "SignalType" SG_ 1001 DistRollCntAvgDrvnSrc "ENM";
BA_ "VNSigAllNodes" SG_ 1001 VehSpdAvgDrvnSrc 1;
BA_ "SignalLongName" SG_ 1001 VehSpdAvgDrvnSrc "Vehicle Speed Average Driven Source";
BA_ "SignalType" SG_ 1001 VehSpdAvgDrvnSrc "ENM";
BA_ "VNSigAllNodes" SG_ 1001 DstRolCntAvgNonDrvnV 1;
BA_ "SignalLongName" SG_ 1001 DstRolCntAvgNonDrvnV "Distance Rolling Count Average Non Driven Validity";
BA_ "SignalType" SG_ 1001 DstRolCntAvgNonDrvnV "ENM";
BA_ "VNSigAllNodes" SG_ 1001 DstRolCntAvNDrRstOc 1;
BA_ "SignalLongName" SG_ 1001 DstRolCntAvNDrRstOc "Distance Rolling Count Average Non Driven Reset Occurred";
BA_ "SignalType" SG_ 1001 DstRolCntAvNDrRstOc "BLN";
BA_ "VNSigAllNodes" SG_ 1001 DstRolCntAvgNonDrvn 1;
BA_ "SignalLongName" SG_ 1001 DstRolCntAvgNonDrvn "Distance Rolling Count Average Non Driven";
BA_ "SignalType" SG_ 1001 DstRolCntAvgNonDrvn "UNM";
BA_ "VNSigAllNodes" SG_ 1001 DistRollCntAvgDrvnV 1;
BA_ "SignalLongName" SG_ 1001 DistRollCntAvgDrvnV "Distance Rolling Count Average Driven Validity";
BA_ "SignalType" SG_ 1001 DistRollCntAvgDrvnV "ENM";
BA_ "VNSigAllNodes" SG_ 1001 DstRolCntAvgDrnRstOc 1;
BA_ "SignalLongName" SG_ 1001 DstRolCntAvgDrnRstOc "Distance Rolling Count Average Driven Reset Occurred";
BA_ "SignalType" SG_ 1001 DstRolCntAvgDrnRstOc "BLN";
BA_ "VNSigAllNodes" SG_ 1001 DistRollCntAvgDrvn 1;
BA_ "SignalLongName" SG_ 1001 DistRollCntAvgDrvn "Distance Rolling Count Average Driven";
BA_ "SignalType" SG_ 1001 DistRollCntAvgDrvn "UNM";
BA_ "VNSigAllNodes" SG_ 1001 VehSpdAvgNDrvnV 1;
BA_ "SignalLongName" SG_ 1001 VehSpdAvgNDrvnV "Vehicle Speed Average Non Driven Validity";
BA_ "SignalType" SG_ 1001 VehSpdAvgNDrvnV "ENM";
BA_ "VNSigAllNodes" SG_ 1001 VehSpdAvgNDrvn 1;
BA_ "SignalLongName" SG_ 1001 VehSpdAvgNDrvn "Vehicle Speed Average Non Driven";
BA_ "SignalType" SG_ 1001 VehSpdAvgNDrvn "UNM";
BA_ "VNSigAllNodes" SG_ 1001 VehSpdAvgDrvnV 1;
BA_ "SignalLongName" SG_ 1001 VehSpdAvgDrvnV "Vehicle Speed Average Driven Validity";
BA_ "SignalType" SG_ 1001 VehSpdAvgDrvnV "ENM";
BA_ "VNSigAllNodes" SG_ 1001 VehSpdAvgDrvn 1;
BA_ "SignalLongName" SG_ 1001 VehSpdAvgDrvn "Vehicle Speed Average Driven";
BA_ "SignalType" SG_ 1001 VehSpdAvgDrvn "UNM";
BA_ "VNSigAllNodes" SG_ 961 PTImmblzerInfo 1;
BA_ "SignalLongName" SG_ 961 PTImmblzerInfo "Powertrain Immobilizer Information";
BA_ "SignalType" SG_ 961 PTImmblzerInfo "UNM";
BA_ "VNSigAllNodes" SG_ 842 WhlGrndVlctyRtNnDrvnV 1;
BA_ "SignalLongName" SG_ 842 WhlGrndVlctyRtNnDrvnV "Wheel Ground Velocity Right Non Driven Validity";
BA_ "SignalType" SG_ 842 WhlGrndVlctyRtNnDrvnV "ENM";
BA_ "VNSigAllNodes" SG_ 842 WhlGrndVlctyRtNnDrvn 1;
BA_ "SignalLongName" SG_ 842 WhlGrndVlctyRtNnDrvn "Wheel Ground Velocity Right Non Driven";
BA_ "SignalType" SG_ 842 WhlGrndVlctyRtNnDrvn "UNM";
BA_ "VNSigAllNodes" SG_ 842 WhlGrndVlctyLftNnDrvnV 1;
BA_ "SignalLongName" SG_ 842 WhlGrndVlctyLftNnDrvnV "Wheel Ground Velocity Left Non Driven Validity";
BA_ "SignalType" SG_ 842 WhlGrndVlctyLftNnDrvnV "ENM";
BA_ "VNSigAllNodes" SG_ 842 WhlGrndVlctyLftNnDrvn 1;
BA_ "SignalLongName" SG_ 842 WhlGrndVlctyLftNnDrvn "Wheel Ground Velocity Left Non Driven";
BA_ "SignalType" SG_ 842 WhlGrndVlctyLftNnDrvn "UNM";
BA_REL_ "GenSigTimeoutTime" BU_SG_REL_ ECM_HS SG_ 1009 PF_MinIdlBstLvlReq 625;
BA_REL_ "GenSigTimeoutMsg" BU_SG_REL_ ECM_HS SG_ 1009 PF_MinIdlBstLvlReq 1009;
BA_REL_ "GenSigSuprvResp" BU_SG_REL_ ECM_HS SG_ 1009 PF_MinIdlBstLvlReq 1;
BA_REL_ "GenSigTimeoutTime" BU_SG_REL_ ECM_HS SG_ 1009 VehTopSpdLmtReq 625;
BA_REL_ "GenSigTimeoutMsg" BU_SG_REL_ ECM_HS SG_ 1009 VehTopSpdLmtReq 1009;
BA_REL_ "GenSigSuprvResp" BU_SG_REL_ ECM_HS SG_ 1009 VehTopSpdLmtReq 1;
BA_REL_ "GenSigTimeoutTime" BU_SG_REL_ EBCM_HS SG_ 497 BkupPwrModeMstrVDA 250;
BA_REL_ "GenSigTimeoutMsg" BU_SG_REL_ EBCM_HS SG_ 497 BkupPwrModeMstrVDA 497;
BA_REL_ "GenSigSuprvResp" BU_SG_REL_ EBCM_HS SG_ 497 BkupPwrModeMstrVDA 2;
BA_REL_ "GenSigSuprvResp" BU_SG_REL_ TPM_HS SG_ 497 SysPwrMd 1;
BA_REL_ "GenSigTimeoutMsg" BU_SG_REL_ TPM_HS SG_ 497 SysPwrMd 497;
BA_REL_ "GenSigTimeoutTime" BU_SG_REL_ TPM_HS SG_ 497 SysPwrMd 3000;
BA_REL_ "GenSigTimeoutTime" BU_SG_REL_ EBCM_HS SG_ 497 SysPwrMd 250;
BA_REL_ "GenSigTimeoutMsg" BU_SG_REL_ EBCM_HS SG_ 497 SysPwrMd 497;
BA_REL_ "GenSigSuprvResp" BU_SG_REL_ EBCM_HS SG_ 497 SysPwrMd 1;
BA_REL_ "GenSigTimeoutTime" BU_SG_REL_ EBCM_HS SG_ 497 TrStLgMdAtv 250;
BA_REL_ "GenSigTimeoutMsg" BU_SG_REL_ EBCM_HS SG_ 497 TrStLgMdAtv 497;
BA_REL_ "GenSigSuprvResp" BU_SG_REL_ EBCM_HS SG_ 497 TrStLgMdAtv 1;
BA_REL_ "GenSigVDAFailResp" BU_SG_REL_ ECM_HS SG_ 497 ACCompNormLd 1;
BA_REL_ "GenSigVDAFailComment" BU_SG_REL_ ECM_HS SG_ 497 ACCompNormLd "Air Conditioning Compressor System VDA";
BA_REL_ "GenSigVBitResp" BU_SG_REL_ ECM_HS SG_ 497 ACCompNormLd 1;
BA_REL_ "GenSigTimeoutTime" BU_SG_REL_ ECM_HS SG_ 497 PTORSMstrEngShtReq 250;
BA_REL_ "GenSigTimeoutMsg" BU_SG_REL_ ECM_HS SG_ 497 PTORSMstrEngShtReq 497;
BA_REL_ "GenSigSuprvResp" BU_SG_REL_ ECM_HS SG_ 497 PTORSMstrEngShtReq 1;
BA_REL_ "GenSigTimeoutTime" BU_SG_REL_ ECM_HS SG_ 497 ThrtlPrgrsnReq 250;
BA_REL_ "GenSigTimeoutMsg" BU_SG_REL_ ECM_HS SG_ 497 ThrtlPrgrsnReq 497;
BA_REL_ "GenSigSuprvResp" BU_SG_REL_ ECM_HS SG_ 497 ThrtlPrgrsnReq 1;
BA_REL_ "GenSigTimeoutTime" BU_SG_REL_ BCM_HS SG_ 840 WhlGrndVlctyRtDrvn 250;
BA_REL_ "GenSigTimeoutMsg" BU_SG_REL_ BCM_HS SG_ 840 WhlGrndVlctyRtDrvn 840;
BA_REL_ "GenSigSuprvResp" BU_SG_REL_ BCM_HS SG_ 840 WhlGrndVlctyRtDrvn 1;
BA_REL_ "GenSigVBitResp" BU_SG_REL_ BCM_HS SG_ 840 WhlGrndVlctyRtDrvn 1;
BA_REL_ "GenSigTimeoutTime" BU_SG_REL_ BCM_HS SG_ 840 WhlGrndVlctyLftDrvn 250;
BA_REL_ "GenSigTimeoutMsg" BU_SG_REL_ BCM_HS SG_ 840 WhlGrndVlctyLftDrvn 840;
BA_REL_ "GenSigSuprvResp" BU_SG_REL_ BCM_HS SG_ 840 WhlGrndVlctyLftDrvn 1;
BA_REL_ "GenSigVBitResp" BU_SG_REL_ BCM_HS SG_ 840 WhlGrndVlctyLftDrvn 1;
BA_REL_ "GenSigTimeoutTime" BU_SG_REL_ BCM_HS SG_ 193 WRSLDWhlDisTpRC 250;
BA_REL_ "GenSigTimeoutMsg" BU_SG_REL_ BCM_HS SG_ 193 WRSLDWhlDisTpRC 193;
BA_REL_ "GenSigSuprvResp" BU_SG_REL_ BCM_HS SG_ 193 WRSLDWhlDisTpRC 1;
BA_REL_ "GenSigTimeoutTime" BU_SG_REL_ BCM_HS SG_ 193 WRSLDSeqNum 250;
BA_REL_ "GenSigTimeoutMsg" BU_SG_REL_ BCM_HS SG_ 193 WRSLDSeqNum 193;
BA_REL_ "GenSigSuprvResp" BU_SG_REL_ BCM_HS SG_ 193 WRSLDSeqNum 1;
BA_REL_ "GenSigTimeoutTime" BU_SG_REL_ BCM_HS SG_ 193 WRSLDWhlDistVal 250;
BA_REL_ "GenSigTimeoutMsg" BU_SG_REL_ BCM_HS SG_ 193 WRSLDWhlDistVal 193;
BA_REL_ "GenSigSuprvResp" BU_SG_REL_ BCM_HS SG_ 193 WRSLDWhlDistVal 1;
BA_REL_ "GenSigTimeoutTime" BU_SG_REL_ BCM_HS SG_ 193 WRSLDWhlRotStatRst 250;
BA_REL_ "GenSigTimeoutMsg" BU_SG_REL_ BCM_HS SG_ 193 WRSLDWhlRotStatRst 193;
BA_REL_ "GenSigSuprvResp" BU_SG_REL_ BCM_HS SG_ 193 WRSLDWhlRotStatRst 1;
BA_REL_ "GenSigTimeoutTime" BU_SG_REL_ BCM_HS SG_ 193 WRSLDWhlDistTmstm 250;
BA_REL_ "GenSigTimeoutMsg" BU_SG_REL_ BCM_HS SG_ 193 WRSLDWhlDistTmstm 193;
BA_REL_ "GenSigSuprvResp" BU_SG_REL_ BCM_HS SG_ 193 WRSLDWhlDistTmstm 1;
BA_REL_ "GenSigTimeoutTime" BU_SG_REL_ BCM_HS SG_ 193 WRSLDWhlDistPlsCntr 250;
BA_REL_ "GenSigTimeoutMsg" BU_SG_REL_ BCM_HS SG_ 193 WRSLDWhlDistPlsCntr 193;
BA_REL_ "GenSigSuprvResp" BU_SG_REL_ BCM_HS SG_ 193 WRSLDWhlDistPlsCntr 1;
BA_REL_ "GenSigTimeoutTime" BU_SG_REL_ BCM_HS SG_ 193 WRSRDWhlDisTpRC 250;
BA_REL_ "GenSigTimeoutMsg" BU_SG_REL_ BCM_HS SG_ 193 WRSRDWhlDisTpRC 193;
BA_REL_ "GenSigSuprvResp" BU_SG_REL_ BCM_HS SG_ 193 WRSRDWhlDisTpRC 1;
BA_REL_ "GenSigTimeoutTime" BU_SG_REL_ BCM_HS SG_ 193 WRSRDSeqNum 250;
BA_REL_ "GenSigTimeoutMsg" BU_SG_REL_ BCM_HS SG_ 193 WRSRDSeqNum 193;
BA_REL_ "GenSigSuprvResp" BU_SG_REL_ BCM_HS SG_ 193 WRSRDSeqNum 1;
BA_REL_ "GenSigTimeoutTime" BU_SG_REL_ BCM_HS SG_ 193 WRSRDWhlRotStatRst 250;
BA_REL_ "GenSigTimeoutMsg" BU_SG_REL_ BCM_HS SG_ 193 WRSRDWhlRotStatRst 193;
BA_REL_ "GenSigSuprvResp" BU_SG_REL_ BCM_HS SG_ 193 WRSRDWhlRotStatRst 1;
BA_REL_ "GenSigTimeoutTime" BU_SG_REL_ BCM_HS SG_ 193 WRSRDWhlDistVal 250;
BA_REL_ "GenSigTimeoutMsg" BU_SG_REL_ BCM_HS SG_ 193 WRSRDWhlDistVal 193;
BA_REL_ "GenSigSuprvResp" BU_SG_REL_ BCM_HS SG_ 193 WRSRDWhlDistVal 1;
BA_REL_ "GenSigTimeoutTime" BU_SG_REL_ BCM_HS SG_ 193 WRSRDWhlDistTmstm 250;
BA_REL_ "GenSigTimeoutMsg" BU_SG_REL_ BCM_HS SG_ 193 WRSRDWhlDistTmstm 193;
BA_REL_ "GenSigSuprvResp" BU_SG_REL_ BCM_HS SG_ 193 WRSRDWhlDistTmstm 1;
BA_REL_ "GenSigTimeoutTime" BU_SG_REL_ BCM_HS SG_ 193 WRSRDWhlDistPlsCntr 250;
BA_REL_ "GenSigTimeoutMsg" BU_SG_REL_ BCM_HS SG_ 193 WRSRDWhlDistPlsCntr 193;
BA_REL_ "GenSigSuprvResp" BU_SG_REL_ BCM_HS SG_ 193 WRSRDWhlDistPlsCntr 1;
BA_REL_ "GenSigTimeoutTime" BU_SG_REL_ TCM_HS SG_ 489 DrvIndpntBrkAppAct 50;
BA_REL_ "GenSigTimeoutMsg" BU_SG_REL_ TCM_HS SG_ 489 DrvIndpntBrkAppAct 489;
BA_REL_ "GenSigSuprvResp" BU_SG_REL_ TCM_HS SG_ 489 DrvIndpntBrkAppAct 1;
BA_REL_ "GenSigTimeoutTime" BU_SG_REL_ ECM_HS SG_ 489 DrvIndpntBrkAppAct 50;
BA_REL_ "GenSigTimeoutMsg" BU_SG_REL_ ECM_HS SG_ 489 DrvIndpntBrkAppAct 489;
BA_REL_ "GenSigSuprvResp" BU_SG_REL_ ECM_HS SG_ 489 DrvIndpntBrkAppAct 1;
BA_REL_ "GenSigTimeoutTime" BU_SG_REL_ BCM_HS SG_ 489 VehDynYawRateV 250;
BA_REL_ "GenSigTimeoutMsg" BU_SG_REL_ BCM_HS SG_ 489 VehDynYawRateV 489;
BA_REL_ "GenSigSuprvResp" BU_SG_REL_ BCM_HS SG_ 489 VehDynYawRateV 2;
BA_REL_ "GenSigSuprvRespSubValue" BU_SG_REL_ BCM_HS SG_ 489 VehDynYawRateV 1;
BA_REL_ "GenSigTimeoutTime" BU_SG_REL_ BCM_HS SG_ 489 VehDynYawRate 250;
BA_REL_ "GenSigTimeoutMsg" BU_SG_REL_ BCM_HS SG_ 489 VehDynYawRate 489;
BA_REL_ "GenSigSuprvResp" BU_SG_REL_ BCM_HS SG_ 489 VehDynYawRate 1;
BA_REL_ "GenSigVBitResp" BU_SG_REL_ BCM_HS SG_ 489 VehDynYawRate 1;
BA_REL_ "GenSigTimeoutTime" BU_SG_REL_ TCM_HS SG_ 489 TrnsBrkSysCltchRelRqd 50;
BA_REL_ "GenSigTimeoutMsg" BU_SG_REL_ TCM_HS SG_ 489 TrnsBrkSysCltchRelRqd 489;
BA_REL_ "GenSigSuprvResp" BU_SG_REL_ TCM_HS SG_ 489 TrnsBrkSysCltchRelRqd 1;
BA_REL_ "GenSigVBitResp" BU_SG_REL_ ECM_HS SG_ 489 BrkPdlDrvAppPrsDetcd 1;
BA_REL_ "GenSigTimeoutTime" BU_SG_REL_ BCM_HS SG_ 489 ABSAtv 250;
BA_REL_ "GenSigTimeoutMsg" BU_SG_REL_ BCM_HS SG_ 489 ABSAtv 489;
BA_REL_ "GenSigSuprvResp" BU_SG_REL_ BCM_HS SG_ 489 ABSAtv 1;
BA_REL_ "GenSigTimeoutTime" BU_SG_REL_ BCM_HS SG_ 381 StWhAnVDA 250;
BA_REL_ "GenSigTimeoutMsg" BU_SG_REL_ BCM_HS SG_ 381 StWhAnVDA 381;
BA_REL_ "GenSigSuprvResp" BU_SG_REL_ BCM_HS SG_ 381 StWhAnVDA 2;
BA_REL_ "GenSigTimeoutTime" BU_SG_REL_ BCM_HS SG_ 381 TirePrsLowIO 250;
BA_REL_ "GenSigTimeoutMsg" BU_SG_REL_ BCM_HS SG_ 381 TirePrsLowIO 381;
BA_REL_ "GenSigSuprvResp" BU_SG_REL_ BCM_HS SG_ 381 TirePrsLowIO 1;
BA_REL_ "GenSigTimeoutTime" BU_SG_REL_ BCM_HS SG_ 381 TreInfMonSysRstPrfmd 250;
BA_REL_ "GenSigTimeoutMsg" BU_SG_REL_ BCM_HS SG_ 381 TreInfMonSysRstPrfmd 381;
BA_REL_ "GenSigSuprvResp" BU_SG_REL_ BCM_HS SG_ 381 TreInfMonSysRstPrfmd 1;
BA_REL_ "GenSigTimeoutTime" BU_SG_REL_ BCM_HS SG_ 381 ABSIO 250;
BA_REL_ "GenSigTimeoutMsg" BU_SG_REL_ BCM_HS SG_ 381 ABSIO 381;
BA_REL_ "GenSigSuprvResp" BU_SG_REL_ BCM_HS SG_ 381 ABSIO 1;
BA_REL_ "GenSigTimeoutTime" BU_SG_REL_ BCM_HS SG_ 381 BrkPadWrnIO 250;
BA_REL_ "GenSigTimeoutMsg" BU_SG_REL_ BCM_HS SG_ 381 BrkPadWrnIO 381;
BA_REL_ "GenSigSuprvResp" BU_SG_REL_ BCM_HS SG_ 381 BrkPadWrnIO 1;
BA_REL_ "GenSigTimeoutTime" BU_SG_REL_ BCM_HS SG_ 381 VehStabEnhmntMd 250;
BA_REL_ "GenSigTimeoutMsg" BU_SG_REL_ BCM_HS SG_ 381 VehStabEnhmntMd 381;
BA_REL_ "GenSigSuprvResp" BU_SG_REL_ BCM_HS SG_ 381 VehStabEnhmntMd 1;
BA_REL_ "GenSigRxStartValue" BU_SG_REL_ BCM_HS SG_ 381 VehStabEnhmntMd "$1 - Normal";
BA_REL_ "GenSigTimeoutTime" BU_SG_REL_ BCM_HS SG_ 381 VehStabEnhmntStat 250;
BA_REL_ "GenSigTimeoutMsg" BU_SG_REL_ BCM_HS SG_ 381 VehStabEnhmntStat 381;
BA_REL_ "GenSigSuprvResp" BU_SG_REL_ BCM_HS SG_ 381 VehStabEnhmntStat 1;
BA_REL_ "GenSigTimeoutTime" BU_SG_REL_ BCM_HS SG_ 381 TCSysOpMd 250;
BA_REL_ "GenSigTimeoutMsg" BU_SG_REL_ BCM_HS SG_ 381 TCSysOpMd 381;
BA_REL_ "GenSigSuprvResp" BU_SG_REL_ BCM_HS SG_ 381 TCSysOpMd 1;
BA_REL_ "GenSigRxStartValue" BU_SG_REL_ BCM_HS SG_ 381 TCSysOpMd "$1 - Normal";
BA_REL_ "GenSigTimeoutTime" BU_SG_REL_ BCM_HS SG_ 381 TCSysOpStat 250;
BA_REL_ "GenSigTimeoutMsg" BU_SG_REL_ BCM_HS SG_ 381 TCSysOpStat 381;
BA_REL_ "GenSigSuprvResp" BU_SG_REL_ BCM_HS SG_ 381 TCSysOpStat 1;
BA_REL_ "GenSigTimeoutTime" BU_SG_REL_ BCM_HS SG_ 381 BrkSysVTopSpdLimVal 250;
BA_REL_ "GenSigTimeoutMsg" BU_SG_REL_ BCM_HS SG_ 381 BrkSysVTopSpdLimVal 381;
BA_REL_ "GenSigSuprvResp" BU_SG_REL_ BCM_HS SG_ 381 BrkSysVTopSpdLimVal 2;
BA_REL_ "GenSigSuprvRespSubValue" BU_SG_REL_ BCM_HS SG_ 381 BrkSysVTopSpdLimVal 255;
BA_REL_ "GenSigTimeoutTime" BU_SG_REL_ BCM_HS SG_ 381 BrkSysBrkLtsReqd 250;
BA_REL_ "GenSigTimeoutMsg" BU_SG_REL_ BCM_HS SG_ 381 BrkSysBrkLtsReqd 381;
BA_REL_ "GenSigSuprvResp" BU_SG_REL_ BCM_HS SG_ 381 BrkSysBrkLtsReqd 2;
BA_REL_ "GenSigVBitResp" BU_SG_REL_ ECM_HS SG_ 241 BrkPdlModTrvl 1;
BA_REL_ "GenSigTimeoutTime" BU_SG_REL_ BCM_HS SG_ 532 BrkSysMalFuncIndOn 300;
BA_REL_ "GenSigTimeoutMsg" BU_SG_REL_ BCM_HS SG_ 532 BrkSysMalFuncIndOn 532;
BA_REL_ "GenSigSuprvResp" BU_SG_REL_ BCM_HS SG_ 532 BrkSysMalFuncIndOn 1;
BA_REL_ "GenSigTimeoutTime" BU_SG_REL_ BCM_HS SG_ 532 BrkFldLvlLw 300;
BA_REL_ "GenSigTimeoutMsg" BU_SG_REL_ BCM_HS SG_ 532 BrkFldLvlLw 532;
BA_REL_ "GenSigSuprvResp" BU_SG_REL_ BCM_HS SG_ 532 BrkFldLvlLw 1;
BA_REL_ "GenSigVBitResp" BU_SG_REL_ BCM_HS SG_ 532 BrkFldLvlLw 1;
BA_REL_ "GenSigTimeoutTime" BU_SG_REL_ BCM_HS SG_ 451 PTRegGenCntlAct 250;
BA_REL_ "GenSigTimeoutMsg" BU_SG_REL_ BCM_HS SG_ 451 PTRegGenCntlAct 451;
BA_REL_ "GenSigSuprvResp" BU_SG_REL_ BCM_HS SG_ 451 PTRegGenCntlAct 1;
BA_REL_ "GenSigTimeoutTime" BU_SG_REL_ BCM_HS SG_ 451 EngTrqActExtRng 250;
BA_REL_ "GenSigTimeoutMsg" BU_SG_REL_ BCM_HS SG_ 451 EngTrqActExtRng 451;
BA_REL_ "GenSigSuprvResp" BU_SG_REL_ BCM_HS SG_ 451 EngTrqActExtRng 1;
BA_REL_ "GenSigVBitResp" BU_SG_REL_ BCM_HS SG_ 451 EngTrqActExtRng 1;
BA_REL_ "GenSigTimeoutTime" BU_SG_REL_ BCM_HS SG_ 288 VehOdo 2500;
BA_REL_ "GenSigTimeoutMsg" BU_SG_REL_ BCM_HS SG_ 288 VehOdo 288;
BA_REL_ "GenSigSuprvResp" BU_SG_REL_ BCM_HS SG_ 288 VehOdo 1;
BA_REL_ "GenSigTimeoutTime" BU_SG_REL_ BCM_HS SG_ 1001 DstRolCntAvgNonDrvn 250;
BA_REL_ "GenSigTimeoutMsg" BU_SG_REL_ BCM_HS SG_ 1001 DstRolCntAvgNonDrvn 1001;
BA_REL_ "GenSigSuprvResp" BU_SG_REL_ BCM_HS SG_ 1001 DstRolCntAvgNonDrvn 1;
BA_REL_ "GenSigVBitResp" BU_SG_REL_ BCM_HS SG_ 1001 DstRolCntAvgNonDrvn 1;
BA_REL_ "GenSigTimeoutTime" BU_SG_REL_ BCM_HS SG_ 1001 DistRollCntAvgDrvn 250;
BA_REL_ "GenSigTimeoutMsg" BU_SG_REL_ BCM_HS SG_ 1001 DistRollCntAvgDrvn 1001;
BA_REL_ "GenSigSuprvResp" BU_SG_REL_ BCM_HS SG_ 1001 DistRollCntAvgDrvn 1;
BA_REL_ "GenSigVBitResp" BU_SG_REL_ BCM_HS SG_ 1001 DistRollCntAvgDrvn 1;
BA_REL_ "GenSigTimeoutTime" BU_SG_REL_ BCM_HS SG_ 1001 VehSpdAvgNDrvn 250;
BA_REL_ "GenSigTimeoutMsg" BU_SG_REL_ BCM_HS SG_ 1001 VehSpdAvgNDrvn 1001;
BA_REL_ "GenSigSuprvResp" BU_SG_REL_ BCM_HS SG_ 1001 VehSpdAvgNDrvn 1;
BA_REL_ "GenSigVBitResp" BU_SG_REL_ BCM_HS SG_ 1001 VehSpdAvgNDrvn 1;
BA_REL_ "GenSigSuprvResp" BU_SG_REL_ TPM_HS SG_ 1001 VehSpdAvgDrvn 1;
BA_REL_ "GenSigTimeoutMsg" BU_SG_REL_ TPM_HS SG_ 1001 VehSpdAvgDrvn 1001;
BA_REL_ "GenSigTimeoutTime" BU_SG_REL_ TPM_HS SG_ 1001 VehSpdAvgDrvn 3000;
BA_REL_ "GenSigTimeoutTime" BU_SG_REL_ BCM_HS SG_ 1001 VehSpdAvgDrvn 250;
BA_REL_ "GenSigTimeoutMsg" BU_SG_REL_ BCM_HS SG_ 1001 VehSpdAvgDrvn 1001;
BA_REL_ "GenSigSuprvResp" BU_SG_REL_ BCM_HS SG_ 1001 VehSpdAvgDrvn 1;
BA_REL_ "GenSigVBitResp" BU_SG_REL_ BCM_HS SG_ 1001 VehSpdAvgDrvn 1;
BA_REL_ "GenSigTimeoutTime" BU_SG_REL_ BCM_HS SG_ 842 WhlGrndVlctyRtNnDrvn 250;
BA_REL_ "GenSigTimeoutMsg" BU_SG_REL_ BCM_HS SG_ 842 WhlGrndVlctyRtNnDrvn 842;
BA_REL_ "GenSigSuprvResp" BU_SG_REL_ BCM_HS SG_ 842 WhlGrndVlctyRtNnDrvn 1;
BA_REL_ "GenSigVBitResp" BU_SG_REL_ BCM_HS SG_ 842 WhlGrndVlctyRtNnDrvn 1;
BA_REL_ "GenSigTimeoutTime" BU_SG_REL_ BCM_HS SG_ 842 WhlGrndVlctyLftNnDrvn 250;
BA_REL_ "GenSigTimeoutMsg" BU_SG_REL_ BCM_HS SG_ 842 WhlGrndVlctyLftNnDrvn 842;
BA_REL_ "GenSigSuprvResp" BU_SG_REL_ BCM_HS SG_ 842 WhlGrndVlctyLftNnDrvn 1;
BA_REL_ "GenSigVBitResp" BU_SG_REL_ BCM_HS SG_ 842 WhlGrndVlctyLftNnDrvn 1;
VAL_ 249 TrnsOtptRotRCRstOcc 1 "true" 0 "false" ;
VAL_ 249 TrnsOtptRotRCV 1 "Invalid" 0 "Valid" ;
VAL_ 249 TrnsOtptShftAngVelSnrPr 1 "true" 0 "false" ;
VAL_ 249 TrnsOutShftAngVelV 1 "Invalid" 0 "Valid" ;
VAL_ 249 TrnsOvrallEstTorqRatioV 1 "Invalid" 0 "Valid" ;
VAL_ 1009 ACCmEngRunReq 1 "Engine Run Requested" 0 "No Action" ;
VAL_ 1009 OutAirTempVDA 1 "VirtualDeviceAvailable" 0 "VirtualDeviceUnavailable" ;
VAL_ 1009 OtsAirTmpCrValV 1 "Invalid" 0 "Valid" ;
VAL_ 1009 EngOffTmVDA 1 "VirtualDeviceAvailable" 0 "VirtualDeviceUnavailable" ;
VAL_ 1009 ClntCircPmpRq 1 "On" 0 "Off" ;
VAL_ 1009 EngOffTmExtRngV 1 "Invalid" 0 "Valid" ;
VAL_ 1009 PF_MinIdlBstLvlReq 3 "Boost Level 3" 2 "Boost Level 2" 1 "Boost Level 1" 0 "No Boost Requested" ;
VAL_ 1257 ElpsdTimeCntRstOcc 1 "true" 0 "false" ;
VAL_ 1257 ACCompType 4 "Electric Driven Motor" 3 "Variable Displacement Electronic" 2 "Variable Displacement Mechanical" 1 "Fixed Displacement Clutched" 0 "None" ;
VAL_ 1257 VSESysPrs 1 "true" 0 "false" ;
VAL_ 1257 ABSPr 1 "true" 0 "false" ;
VAL_ 1257 TCSysPr 1 "true" 0 "false" ;
VAL_ 1257 VehSpdCntlSystmType 2 "Adaptive Cruise Control" 1 "Conventional Cruise Control" 0 "No Vehicle Speed Control" ;
VAL_ 1257 PltfrmEngSpdCmdSysTp 6 "Auto Elevated Idle" 5 "Enhanced Fast Idle" 4 "Fast Idle" 3 "Mobile Variable PTO" 2 "Stationary Variable PTO" 1 "Stationary PTO" 0 "No Platform Eng. Speed Command Sys." ;
VAL_ 497 FuelFltLfRstRqd 1 "true" 0 "false" ;
VAL_ 497 ACCompSysVDA 1 "VirtualDeviceAvailable" 0 "VirtualDeviceUnavailable" ;
VAL_ 497 BkupPwrModeMstrVDA 1 "VirtualDeviceAvailable" 0 "VirtualDeviceUnavailable" ;
VAL_ 497 PrkBrkVDA 1 "VirtualDeviceAvailable" 0 "VirtualDeviceUnavailable" ;
VAL_ 497 PrkBrkVDM 1 "Use Data" 0 "Don't Use Data" ;
VAL_ 497 BkupPwrModeMstrVDM 1 "Use Data" 0 "Don't Use Data" ;
VAL_ 497 ACCompSysVDM 1 "Use Data" 0 "Don't Use Data" ;
VAL_ 497 AirbgVDA 1 "VirtualDeviceAvailable" 0 "VirtualDeviceUnavailable" ;
VAL_ 497 SysBkupPwrMdEn 1 "true" 0 "false" ;
VAL_ 497 SysBkUpPwrMd 3 "Crank Request" 2 "Run" 1 "Accessory" 0 "Off" ;
VAL_ 497 SysPwrMd 3 "Crank Request" 2 "Run" 1 "Accessory" 0 "Off" ;
VAL_ 497 TrStLgMdAtv 1 "true" 0 "false" ;
VAL_ 497 DispMeasSys 1 "English" 0 "Metric" ;
VAL_ 497 ACCmpsrFldOn 1 "true" 0 "false" ;
VAL_ 497 ACCompModReq 3 "No Action" 2 "Engage" 1 "Disengage" 0 "Disengage Immediately" ;
VAL_ 497 ACCompNormLdV 1 "Invalid" 0 "Valid" ;
VAL_ 497 PTORSMstrEngShtReq 1 "true" 0 "false" ;
VAL_ 497 EngOilLfRstRq 1 "true" 0 "false" ;
VAL_ 497 SIRDpl 1 "true" 0 "false" ;
VAL_ 497 PTORmStMsEngStRq 1 "PTO Remote Start Requested" 0 "PTO Remote Start Not Requested" ;
VAL_ 497 RmVehStrRq 1 "Remote Start Requested" 0 "Remote Start Not Requested" ;
VAL_ 497 ThrtlPrgrsnReq 2 "Map C" 1 "Map B" 0 "Map A" ;
VAL_ 497 PrkBrkSwAtv 1 "true" 0 "false" ;
VAL_ 497 PMMAccTrmSt 1 "Active" 0 "Inactive" ;
VAL_ 497 PMMRunCrkTrmSt 1 "Active" 0 "Inactive" ;
VAL_ 497 ImmblzrPreRelPswdStat 1 "Information Valid" 0 "No Information" ;
VAL_ 840 WhlGrndVlctyRtDrvnV 1 "Invalid" 0 "Valid" ;
VAL_ 840 WhlGrndVlctyLftDrvnV 1 "Invalid" 0 "Valid" ;
VAL_ 193 WRSLDWhlDistVal 1 "Invalid" 0 "Valid" ;
VAL_ 193 WRSLDWhlRotStatRst 1 "true" 0 "false" ;
VAL_ 193 WRSRDWhlRotStatRst 1 "true" 0 "false" ;
VAL_ 193 WRSRDWhlDistVal 1 "Invalid" 0 "Valid" ;
VAL_ 481 AuxHtrRq 1 "On" 0 "Off" ;
VAL_ 481 AuxHtrAtv 1 "true" 0 "false" ;
VAL_ 481 DrvSelMdSw1Sta 1 "Active" 0 "Inactive" ;
VAL_ 481 FuelMdSwActV 1 "Invalid" 0 "Valid" ;
VAL_ 481 FuelMdSwAct 1 "True" 0 "False" ;
VAL_ 481 CrsSpdLmtrSwStat 9 "Between Ranges" 8 "Short to Power" 7 "Open/Short to Ground" 6 "Cancel" 5 "Cruise On/Off" 4 "SL/SW On/Off/GAP" 3 "Set" 2 "Resume" 1 "No Activation" 0 "Indeterminate" ;
VAL_ 481 AdptCrsGapSwAct 2 "Increase Gap" 1 "Decrease Gap" 0 "No Activation" ;
VAL_ 481 CrsCntrlSwStCanSwAct 1 "true" 0 "false" ;
VAL_ 481 CrsCntrlSwStSwDataIntgty 3 "Illegal Range" 2 "Failure Detected" 1 "Data Invalid" 0 "Data Valid" ;
VAL_ 481 CrsCntrlSwStSpdInSwAct 1 "true" 0 "false" ;
VAL_ 481 CrsCntrlSwStSpDcSwAct 1 "true" 0 "false" ;
VAL_ 481 CrsCntrlSwStSetSwAct 1 "true" 0 "false" ;
VAL_ 481 CrsCntrlSwStResSwAct 1 "true" 0 "false" ;
VAL_ 481 CrsCntrlSwStOnSwAct 1 "true" 0 "false" ;
VAL_ 481 CrsCntCncRq 1 "Cancel" 0 "Do Not Cancel" ;
VAL_ 761 ABFI_CollPrepSysInhbt 1 "true" 0 "false" ;
VAL_ 761 ABFI_RrVirtlBmprInh 1 "true" 0 "false" ;
VAL_ 761 BrkPdlDrvApplPresV 1 "Invalid" 0 "Valid" ;
VAL_ 761 WhlSpdSnsgDTCStat 4 "Diagnostic Failed" 3 "Diagnostic Passed" 2 "No Status to Report" 1 "Critically Disabled" 0 "Not Supported" ;
VAL_ 761 SprTireSt 2 "Spare Detected" 1 "No Spare Detected" 0 "Undetermined" ;
VAL_ 489 DrvIndpntBrkAppAct 1 "true" 0 "false" ;
VAL_ 489 WhlSlpSt 3 "Slip Detection Fault" 2 "Positive Slip Detected" 1 "Negative Slip Detected" 0 "No Slip Detected" ;
VAL_ 489 BSTGRReqdGear 8 "Eighth Gear" 7 "Seventh Gear" 6 "Sixth Gear" 5 "Fifth Gear" 4 "Fourth Gear" 3 "Third Gear" 2 "Second Gear" 1 "First Gear" 0 "No Action" ;
VAL_ 489 BSTGRReqType 3 "Hold Gear" 2 "Min Gear Request" 1 "Max Gear Request" 0 "No Action" ;
VAL_ 489 VSELatAccV 1 "Invalid" 0 "Valid" ;
VAL_ 489 VSEAct 1 "true" 0 "false" ;
VAL_ 489 VhDynCntlSysSt 7 "Driver Disabled" 6 "Enhanced Operation" 5 "Calibrating" 4 "Warming Up" 3 "Permanently Failed" 2 "Temporarily Inhibited" 1 "Reduced Function" 0 "Normal Operation" ;
VAL_ 489 VehDynYawRateV 1 "Invalid" 0 "Valid" ;
VAL_ 489 TrnsBrkSysCltchRelRqd 1 "true" 0 "false" ;
VAL_ 489 TracCntrlSysDrIntnt 1 "Enabled" 0 "Disabled" ;
VAL_ 489 VehDynOvrUndrStrV 1 "Invalid" 0 "Valid" ;
VAL_ 489 TCSysEnbld 1 "true" 0 "false" ;
VAL_ 489 TCSysAtv 1 "true" 0 "false" ;
VAL_ 489 BrkPdlDrvAppPrsDetcdV 1 "Invalid" 0 "Valid" ;
VAL_ 489 BrkPdlDrvAppPrsDetcd 1 "true" 0 "false" ;
VAL_ 489 ACCBrkngAct 1 "true" 0 "false" ;
VAL_ 489 ABSFld 1 "true" 0 "false" ;
VAL_ 489 ABSAtv 1 "true" 0 "false" ;
VAL_ 381 EBDFailed 1 "true" 0 "false" ;
VAL_ 381 StWhAnVDA 1 "VirtualDeviceAvailable" 0 "VirtualDeviceUnavailable" ;
VAL_ 381 TirePrsLowIO 1 "true" 0 "false" ;
VAL_ 381 VaccBoostFailure 1 "true" 0 "false" ;
VAL_ 381 VSESysPrs 1 "true" 0 "false" ;
VAL_ 381 HalfSysFail 1 "true" 0 "false" ;
VAL_ 381 ActVehAccelV 1 "Invalid" 0 "Valid" ;
VAL_ 381 BksOvht 1 "true" 0 "false" ;
VAL_ 381 TCSysPr 1 "true" 0 "false" ;
VAL_ 381 ABSPr 1 "true" 0 "false" ;
VAL_ 381 TreInfMonSysRstPrfmd 1 "true" 0 "false" ;
VAL_ 381 ABSIO 1 "true" 0 "false" ;
VAL_ 381 BrkPadWrnIO 1 "true" 0 "false" ;
VAL_ 381 VehStabEnhmntMd 2 "Competitive" 1 "Normal" 0 "Off" ;
VAL_ 381 VehStabEnhmntStat 4 "Not Ready" 3 "Warming Up" 2 "Fault" 1 "Active" 0 "Inactive" ;
VAL_ 381 TCSysOpMd 2 "Off Road" 1 "Normal" 0 "Off" ;
VAL_ 381 TCSysOpStat 2 "Fault" 1 "Active" 0 "Inactive" ;
VAL_ 381 BrkSysRedBrkTlltlReq 1 "true" 0 "false" ;
VAL_ 381 BrkSysBrkLtsReqd 1 "true" 0 "false" ;
VAL_ 241 BrkPedTrvlAchvdV 1 "Invalid" 0 "Valid" ;
VAL_ 241 BrkPedTrvlAchvd 1 "true" 0 "false" ;
VAL_ 241 BrkAppSnsrHmPosLrnd 1 "true" 0 "false" ;
VAL_ 241 BrkPdlModTrvlV 1 "Invalid" 0 "Valid" ;
VAL_ 241 BrkPdlModTrvl 1 "true" 0 "false" ;
VAL_ 500 DrvSelMd1ReqDnd 1 "true" 0 "false" ;
VAL_ 500 DrvSelMd1Stat 1 "Active" 0 "Inactive" ;
VAL_ 407 TrnsOvrallActTorqRatioV 1 "Invalid" 0 "Valid" ;
VAL_ 738 EngTrnsRngDspRvAct 1 "true" 0 "false" ;
VAL_ 738 EngTrnsRngDspNtrlAct 1 "true" 0 "false" ;
VAL_ 738 EngTrnsRngDspFwdAc 1 "true" 0 "false" ;
VAL_ 738 EngTrnsRngDspPrkAct 1 "true" 0 "false" ;
VAL_ 738 EngShftrMlfIO 1 "true" 0 "false" ;
VAL_ 738 EngRedPwrSecEvntIO 1 "true" 0 "false" ;
VAL_ 738 EngShtdwnSecEvtIO 1 "true" 0 "false" ;
VAL_ 738 EngVehPrkWhnStpIO 1 "true" 0 "false" ;
VAL_ 738 EngGnrlTrnsMlfIO 1 "true" 0 "false" ;
VAL_ 431 TrnsTrqCnvCltCmdMdF 1 "true" 0 "false" ;
VAL_ 431 AutoTransGrSftDirectFl 1 "true" 0 "false" ;
VAL_ 431 TrnsInpCltchStat 0 "Disengaged" 1 "Engaging" 2 "Engaged" 3 "Disengaging" 4 "Controlled Slip" 5 "Reserved" 6 "Reserved" 7 "Not Supported" ;
VAL_ 431 TrnsAntcptdCrpTrqRRnV 1 "Invalid" 0 "Valid" ;
VAL_ 431 TrnCltAdpAtv 1 "true" 0 "false" ;
VAL_ 431 TransCrnkPermsnStat 0 "Crank Not Permitted" 1 "Crank Permitted" ;
VAL_ 431 WrmUpShftPtrn 0 "Inactive" 1 "Active" ;
VAL_ 309 StBltTgtCSRq 0 "No Action" 1 "Low" 2 "Normal" 3 "Performance" 4 "Locked" ;
VAL_ 309 ColPrSysCustReq 0 "No Action" 1 "Off" 2 "Alert" 3 "Alert and Brake" ;
VAL_ 309 SecV 1 "Invalid" 0 "Valid" ;
VAL_ 309 CldrMth_154 12 "December" 11 "November" 10 "October" 9 "September" 8 "August" 7 "July" 6 "June" 5 "May" 4 "April" 3 "March" 2 "February" 1 "January" 0 "Unknown" ;
VAL_ 309 CldrMth 12 "December" 11 "November" 10 "October" 9 "September" 8 "August" 7 "July" 6 "June" 5 "May" 4 "April" 3 "March" 2 "February" 1 "January" 0 "Unknown" ;
VAL_ 309 AutoHiBmVDA 1 "VirtualDeviceAvailable" 0 "VirtualDeviceUnavailable" ;
VAL_ 309 CtLghtDet 1 "true" 0 "false" ;
VAL_ 309 RrClosVDA 1 "VirtualDeviceAvailable" 0 "VirtualDeviceUnavailable" ;
VAL_ 309 TCSysDisSwAtv 1 "true" 0 "false" ;
VAL_ 309 VehMovState 4 "Invalid" 3 "Reverse" 2 "Forward" 1 "Neutral" 0 "Parked" ;
VAL_ 309 TCSysDisSwAtvV 1 "Invalid" 0 "Valid" ;
VAL_ 309 HillDesCtrlMdSwActV 1 "Invalid" 0 "Valid" ;
VAL_ 309 WSWshSwAtv 1 "true" 0 "false" ;
VAL_ 309 HillDesCtrlMdSwAct 1 "true" 0 "false" ;
VAL_ 309 RrClosAjarSwAct 1 "true" 0 "false" ;
VAL_ 309 WSWprAct 1 "true" 0 "false" ;
VAL_ 532 AutoBrkngAvlbl 1 "true" 0 "false" ;
VAL_ 532 ABSAutnmsBrkReq 1 "true" 0 "false" ;
VAL_ 532 HlStrAssActIO 1 "true" 0 "false" ;
VAL_ 532 BrkSysAutBrkFld 1 "true" 0 "false" ;
VAL_ 532 IntBrkAssPreFilReq 1 "true" 0 "false" ;
VAL_ 532 BrkSysMalFuncIndOn 1 "true" 0 "false" ;
VAL_ 532 BPDAPS_BkPDrvApPV 1 "Invalid" 0 "Valid" ;
VAL_ 532 BrkFldLvlLwV 1 "Invalid" 0 "Valid" ;
VAL_ 532 AutoBrkngAct 1 "true" 0 "false" ;
VAL_ 532 BrkFldLvlLw 1 "true" 0 "false" ;
VAL_ 451 AuxHtrAlwd 1 "true" 0 "false" ;
VAL_ 451 EconMdRqDndIO 1 "true" 0 "false" ;
VAL_ 451 EconMdAtvIO 1 "true" 0 "false" ;
VAL_ 451 AppCltchAutSrtIO 1 "true" 0 "false" ;
VAL_ 451 PTRegGenCntlAct 1 "true" 0 "false" ;
VAL_ 451 EngTrqRdFlrSt 4 "Torq Reduction Communication Failed" 3 "Torque Reduction Limited" 2 "Torque Reduction Permanently Failed" 1 "Torque Reduction Temporarily Failed" 0 "Torque Reduction OK" ;
VAL_ 451 EngTrqDrRqdExtRngV 1 "Invalid" 0 "Valid" ;
VAL_ 451 EngTrqActExtRngV 1 "Invalid" 0 "Valid" ;
VAL_ 320 HiBmIO 1 "true" 0 "false" ;
VAL_ 320 PrkLtIO 1 "true" 0 "false" ;
VAL_ 320 RrFgLtIO 1 "true" 0 "false" ;
VAL_ 320 FrFgLtIO 1 "true" 0 "false" ;
VAL_ 320 RtTrnLmpAtv 2 "On with telltale" 1 "On without telltale" 0 "Off" ;
VAL_ 320 LftTrnLmpAtv 2 "On with telltale" 1 "On without telltale" 0 "Off" ;
VAL_ 320 HazSwAtv 1 "true" 0 "false" ;
VAL_ 320 BrkLtsAtv 1 "true" 0 "false" ;
VAL_ 320 TrnSwAct 2 "Right" 1 "Left" 0 "No Activation" ;
VAL_ 320 RrFogLmpsAct 1 "true" 0 "false" ;
VAL_ 320 OtsdAmbtLtLvlStatV 1 "Invalid" 0 "Valid" ;
VAL_ 320 OtsdAmbtLtLvlStat 2 "Day" 1 "Night" 0 "Unknown" ;
VAL_ 320 MainLghtSw 3 "HEADLAMP" 2 "PARKLAMP" 1 "OFF" 0 "AUTO" ;
VAL_ 320 LowBmAct 1 "true" 0 "false" ;
VAL_ 320 HighBmAct 1 "true" 0 "false" ;
VAL_ 320 HdlmpBmSelectStat 2 "High Beams" 1 "Low Beams" 0 "Unknown" ;
VAL_ 320 FlToPsSwAtv 1 "true" 0 "false" ;
VAL_ 320 AdvFrntLghtSysEnbld 1 "true" 0 "false" ;
VAL_ 320 FrFogLmpsAct 1 "true" 0 "false" ;
VAL_ 320 AutLghtCtrl 1 "true" 0 "false" ;
VAL_ 1919 DTCI_DTCFaultType_77F 3 "Type C" 2 "Type B" 1 "Type A" 0 "Not Supported" ;
VAL_ 1919 DTCI_CodeSupported_77F 1 "true" 0 "false" ;
VAL_ 1919 DTCI_CurrentStatus_77F 1 "true" 0 "false" ;
VAL_ 1919 DTCI_TstNPsdCdClrdSt_77F 1 "true" 0 "false" ;
VAL_ 1919 DTCI_TstFldCdClrdStat_77F 1 "true" 0 "false" ;
VAL_ 1919 DTCI_HistStat_77F 1 "true" 0 "false" ;
VAL_ 1919 DTCI_TstNPsdPwrUpSt_77F 1 "true" 0 "false" ;
VAL_ 1919 DTCI_TstFldPwrUpSt_77F 1 "true" 0 "false" ;
VAL_ 1919 DTCI_WrnIndRqdSt_77F 1 "true" 0 "false" ;
VAL_ 1919 DTCI_DTCTriggered_77F 1 "true" 0 "false" ;
VAL_ 1919 DTCIUnused7_77F 1 "true" 0 "false" ;
VAL_ 1919 DTCIUnused6_77F 1 "true" 0 "false" ;
VAL_ 1919 DTCIUnused5_77F 1 "true" 0 "false" ;
VAL_ 1919 DTCIUnused4_77F 1 "true" 0 "false" ;
VAL_ 1919 DTCIUnused3_77F 1 "true" 0 "false" ;
VAL_ 1919 DTCIUnused2_77F 1 "true" 0 "false" ;
VAL_ 1919 DTCIUnused1_77F 1 "true" 0 "false" ;
VAL_ 499 ElecShftPFShftIntlckPer 1 "Shift out of Park is not Permitted" 0 "Shift out of Park is Permitted" ;
VAL_ 499 PTShftPtrnOvrdAct 1 "true" 0 "false" ;
VAL_ 499 PFTrnsTUDSecSwSt 3 "Illegal Up/Down Switch State Active" 2 "Decrement Switch Active" 1 "Increment Switch Active" 0 "No Activation" ;
VAL_ 499 TrnsPFShftPattSw4Act 1 "true" 0 "false" ;
VAL_ 499 TrnsPFShftPattSw3Act 1 "true" 0 "false" ;
VAL_ 499 TrnsPFShftPattSw2Act 1 "true" 0 "false" ;
VAL_ 499 TrnsPFShftPattSw1Act 1 "true" 0 "false" ;
VAL_ 499 PFTrnsTUDSwSt 3 "Illegal Up/Down Switch State Active" 2 "Decrement Switch Active" 1 "Increment Switch Active" 0 "No Activation" ;
VAL_ 499 PFTrnsTUDEnSwSt 3 "Illegal Enable Switch State" 2 "Electronic Range Select Enable Sw" 1 "Driver Shift Control Enable Switch" 0 "No Activation" ;
VAL_ 499 OvrdrvDsblReqd 1 "true" 0 "false" ;
VAL_ 1906 DTCI_DTCFaultType_772 3 "Type C" 2 "Type B" 1 "Type A" 0 "Not Supported" ;
VAL_ 1906 DTCI_CodeSupported_772 1 "true" 0 "false" ;
VAL_ 1906 DTCI_CurrentStatus_772 1 "true" 0 "false" ;
VAL_ 1906 DTCI_TstNPsdCdClrdSt_772 1 "true" 0 "false" ;
VAL_ 1906 DTCI_TstFldCdClrdStat_772 1 "true" 0 "false" ;
VAL_ 1906 DTCI_HistStat_772 1 "true" 0 "false" ;
VAL_ 1906 DTCI_TstNPsdPwrUpSt_772 1 "true" 0 "false" ;
VAL_ 1906 DTCI_TstFldPwrUpSt_772 1 "true" 0 "false" ;
VAL_ 1906 DTCI_WrnIndRqdSt_772 1 "true" 0 "false" ;
VAL_ 1906 DTCI_DTCTriggered_772 1 "true" 0 "false" ;
VAL_ 1906 DTCIUnused7_772 1 "true" 0 "false" ;
VAL_ 1906 DTCIUnused6_772 1 "true" 0 "false" ;
VAL_ 1906 DTCIUnused5_772 1 "true" 0 "false" ;
VAL_ 1906 DTCIUnused4_772 1 "true" 0 "false" ;
VAL_ 1906 DTCIUnused3_772 1 "true" 0 "false" ;
VAL_ 1906 DTCIUnused2_772 1 "true" 0 "false" ;
VAL_ 1906 DTCIUnused1_772 1 "true" 0 "false" ;
VAL_ 298 VhSecNImmoIndRq 2 "Flashing Indication" 1 "Continuous Indication" 0 "No Indication" ;
VAL_ 298 ChmAct 1 "true" 0 "false" ;
VAL_ 298 DDAjrSwAtvM 0 "Don't Use Data" 1 "Use Data" ;
VAL_ 298 CrshAlrtDrvrSlctdType 0 "Chime" 1 "Seat" ;
VAL_ 298 PsSbltAtcV 1 "Invalid" 0 "Valid" ;
VAL_ 298 PsSbltAtc 1 "true" 0 "false" ;
VAL_ 298 TrlrBrkDsplyAct 1 "true" 0 "false" ;
VAL_ 298 RdSpdCatType 3 "all speed categories 0 - 50 km/h" 2 "all speed categories 51-80 km/h" 1 "all speed categories 81-130 km/h" 0 "all speed categories > 130 km/h" ;
VAL_ 298 LnCat 3 "Four Or More Lanes" 2 "Two Or Three Lanes" 1 "One lane" 0 "no info available" ;
VAL_ 298 FncRdClass 4 "Highway" 3 "Unused 3" 2 "Unused 2" 1 "Unused 1" 0 "Residential Road" ;
VAL_ 298 SprtLnRd 1 "true" 0 "false" ;
VAL_ 298 CntrldAccRd 1 "true" 0 "false" ;
VAL_ 298 BldUpArDet 1 "true" 0 "false" ;
VAL_ 298 MpDataAvlbl 1 "true" 0 "false" ;
VAL_ 298 SusCustStngReq 2 "Sport

" 1 "Normal/Off" 0 "No Action" ;
VAL_ 298 StrCustStngReq 2 "Sport

" 1 "Normal/Off" 0 "No Action" ;
VAL_ 298 RstrCustFctrDef 1 "Restore Defaults" 0 "No Action" ;
VAL_ 298 DrvlnCustStngReq 2 "Sport

" 1 "Normal/Off" 0 "No Action" ;
VAL_ 298 ChmMstrVDA 1 "VirtualDeviceAvailable" 0 "VirtualDeviceUnavailable" ;
VAL_ 298 IPCVDA 1 "VirtualDeviceAvailable" 0 "VirtualDeviceUnavailable" ;
VAL_ 298 HeadUpDispVDA 1 "VirtualDeviceAvailable" 0 "VirtualDeviceUnavailable" ;
VAL_ 298 HapticSeatVDA 1 "VirtualDeviceAvailable" 0 "VirtualDeviceUnavailable" ;
VAL_ 298 RRDoorAjarSwAct 1 "true" 0 "false" ;
VAL_ 298 PDAjrSwAtv 1 "true" 0 "false" ;
VAL_ 298 DDAjrSwAtv 1 "true" 0 "false" ;
VAL_ 298 TrlrHWIntrfcVDA 1 "VirtualDeviceAvailable" 0 "VirtualDeviceUnavailable" ;
VAL_ 298 DrId 7 "Unknown" 6 "Driver #7" 5 "Driver #6" 4 "Driver #5" 3 "Driver #4" 2 "Driver #3" 1 "Driver #2" 0 "Driver #1" ;
VAL_ 298 EnrgMgtLdShdRq 4 "Load Shed Level 4" 3 "Load Shed Level 3" 2 "Load Shed Level 2" 1 "Load Shed Level 1" 0 "No Load Shedding" ;
VAL_ 298 DrSbltAtcV 1 "Invalid" 0 "Valid" ;
VAL_ 298 TrlrHtchSwAtv 1 "true" 0 "false" ;
VAL_ 298 TreInfMonSysRstReq 1 "true" 0 "false" ;
VAL_ 298 HUDActv 1 "true" 0 "false" ;
VAL_ 298 BatVltV 1 "Invalid" 0 "Valid" ;
VAL_ 298 RLDoorAjarSwAct 1 "true" 0 "false" ;
VAL_ 298 DrSbltAtc 1 "true" 0 "false" ;
VAL_ 288 VehOdoV 1 "Invalid" 0 "Valid" ;
VAL_ 1001 DistRollCntAvgDrvnSrc 1 "Wheel Speed" 0 "Transmission Output Speed" ;
VAL_ 1001 VehSpdAvgDrvnSrc 1 "Wheel Speed" 0 "Transmission Output Speed" ;
VAL_ 1001 DstRolCntAvgNonDrvnV 1 "Invalid" 0 "Valid" ;
VAL_ 1001 DstRolCntAvNDrRstOc 1 "true" 0 "false" ;
VAL_ 1001 DistRollCntAvgDrvnV 1 "Invalid" 0 "Valid" ;
VAL_ 1001 DstRolCntAvgDrnRstOc 1 "true" 0 "false" ;
VAL_ 1001 VehSpdAvgNDrvnV 1 "Invalid" 0 "Valid" ;
VAL_ 1001 VehSpdAvgDrvnV 1 "Invalid" 0 "Valid" ;
VAL_ 842 WhlGrndVlctyRtNnDrvnV 1 "Invalid" 0 "Valid" ;
VAL_ 842 WhlGrndVlctyLftNnDrvnV 1 "Invalid" 0 "Valid" ;
SIG_GROUP_ 193 WhlRotatStatLftDrvn 1 : WRSLDWhlDisTpRC WRSLDSeqNum WRSLDWhlDistVal WRSLDWhlRotStatRst WRSLDWhlDistTmstm WRSLDWhlDistPlsCntr;
SIG_GROUP_ 193 WhlRotatStatRtDrvn 1 : WRSRDWhlDisTpRC WRSRDSeqNum WRSRDWhlRotStatRst WRSRDWhlDistVal WRSRDWhlDistTmstm WRSRDWhlDistPlsCntr;
SIG_GROUP_ 481 CrsCntrlSwStat 1 : CrsCntrlSwStCanSwAct CrsCntrlSwStSwDataIntgty CrsCntrlSwStSpdInSwAct CrsCntrlSwStSpDcSwAct CrsCntrlSwStSetSwAct CrsCntrlSwStResSwAct CrsCntrlSwStOnSwAct;
SIG_GROUP_ 761 AutoBrkFeatInhbt 1 : ABFI_CollPrepSysInhbt ABFI_RrVirtlBmprInh;
SIG_GROUP_ 761 WhlSpdSnsLgsDiagStat 1 : WhlSpdSnsgDTCIndex WhlSpdSnsgDTCStat;
SIG_GROUP_ 489 BrkSysTransGearReq 1 : BSTGRReqdGear BSTGRReqType;
SIG_GROUP_ 241 BrkPedInitTrvlAchvdStat 1 : BrkPedTrvlAchvdV BrkPedTrvlAchvd;
SIG_GROUP_ 532 BrkPdDrvAppPrsStat 1 : BPDAPS_BkPDrvApPV BPDAPS_BkPDrvApP;
SIG_GROUP_ 1919 DTCInfo_77F 1 : DTCI_DTCFaultType_77F DTCI_CodeSupported_77F DTCI_CurrentStatus_77F DTCI_TstNPsdCdClrdSt_77F DTCI_TstFldCdClrdStat_77F DTCI_HistStat_77F DTCI_TstNPsdPwrUpSt_77F DTCI_TstFldPwrUpSt_77F DTCI_WrnIndRqdSt_77F DTCI_DTCFailType_77F DTCI_DTCNumber_77F DTCI_DTCSource_77F DTCI_DTCTriggered_77F DTCIUnused7_77F DTCIUnused6_77F DTCIUnused5_77F DTCIUnused4_77F DTCIUnused3_77F DTCIUnused2_77F DTCIUnused1_77F;
SIG_GROUP_ 1906 DTCInfo_772 1 : DTCI_DTCFaultType_772 DTCI_CodeSupported_772 DTCI_CurrentStatus_772 DTCI_TstNPsdCdClrdSt_772 DTCI_TstFldCdClrdStat_772 DTCI_HistStat_772 DTCI_TstNPsdPwrUpSt_772 DTCI_TstFldPwrUpSt_772 DTCI_WrnIndRqdSt_772 DTCI_DTCFailType_772 DTCI_DTCNumber_772 DTCI_DTCSource_772 DTCI_DTCTriggered_772 DTCIUnused7_772 DTCIUnused6_772 DTCIUnused5_772 DTCIUnused4_772 DTCIUnused3_772 DTCIUnused2_772 DTCIUnused1_772;
